VERSION "created by canmatrix"

NS_ :

BS_:

BU_: CabHeater_44 EAC_94 DCDC_1A HVJB_1E PPC_HV_5B PPC_00 PPC_EngineBrake_29 VECU_27 SAC_30 DTCO_EE eDS_5A EBS3_0B AEBS_A0 BMS_F4 Gearbox_03 DD_17 SERVICE_TOOL_F9 DANA_5F

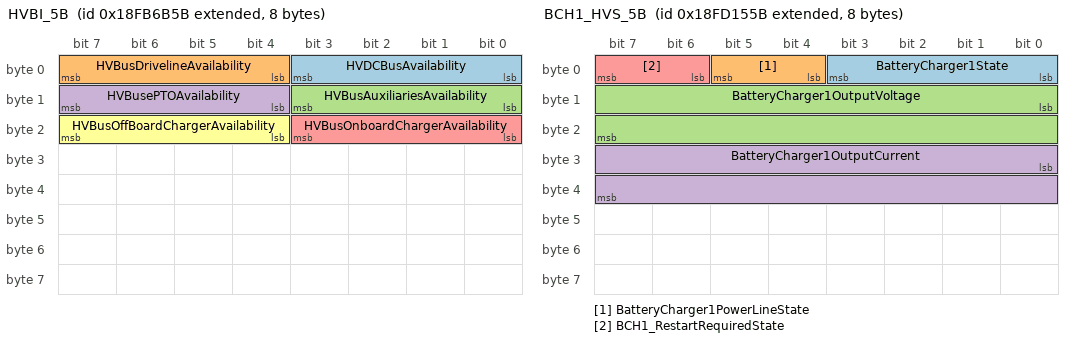
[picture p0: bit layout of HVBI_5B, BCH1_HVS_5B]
BO_ 2566613851 HVBI_5B: 8 PPC_HV_5B
 SG_ HVDCBusAvailability : 0|4@1+ (1,0) [0|15] "state" Vector__XXX
 SG_ HVBusDrivelineAvailability : 4|4@1+ (1,0) [0|15] "state" Vector__XXX
 SG_ HVBusAuxiliariesAvailability : 8|4@1+ (1,0) [0|15] "state" Vector__XXX
 SG_ HVBusePTOAvailability : 12|4@1+ (1,0) [0|15] "state" Vector__XXX
 SG_ HVBusOnboardChargerAvailability : 16|4@1+ (1,0) [0|15] "state" Vector__XXX
 SG_ HVBusOffBoardChargerAvailability : 20|4@1+ (1,0) [0|15] "state" Vector__XXX

BO_ 2566658651 HVESSTC1_5B: 8 PPC_HV_5B
 SG_ HVESSThermalManagementSystemHtrE : 32|2@1+ (1,0) [0|3] "state" Vector__XXX

BO_ 2566675956 HVESSCFG_F4: 20 BMS_F4
 SG_ HVESSNominalVoltage : 0|16@1+ (0.05,0) [0|3212.75] "V" Vector__XXX
 SG_ HVESSRecommendedMinOperatingVolt : 16|16@1+ (0.05,0) [0|3212.75] "V" Vector__XXX
 SG_ HVESSRecommendedMaxOperatingVolt : 32|16@1+ (0.05,0) [0|3212.75] "V" Vector__XXX
 SG_ HVESSRecommendedMinStateOfCharge : 48|16@1+ (0.0015625,0) [0|100.3984375] "%" Vector__XXX
 SG_ HVESSRecommendedMaxStateOfCharge : 64|16@1+ (0.0015625,0) [0|100.3984375] "%" Vector__XXX
 SG_ HVESSRecommendedMaxOperatingTemp : 80|16@1+ (0.03125,-273) [-273|1734.96875] "degC" Vector__XXX
 SG_ HVESSRecommendedMinOperatingTemp : 96|16@1+ (0.03125,-273) [-273|1734.96875] "degC" Vector__XXX
 SG_ HVESSCellMaximumVoltageLimit : 112|8@1+ (0.02044,0) [0|5.11] "V" Vector__XXX
 SG_ HVESSCellMinimumVoltageLimit : 120|8@1+ (0.02044,0) [0|5.11] "V" Vector__XXX
 SG_ HVESSNumberofHVESPsConfigured : 128|8@1+ (1,0) [0|250] "count" Vector__XXX
 SG_ HVESSNominalRatedCapacity : 136|24@1+ (0.001,0) [0|16449.535] "kWh" Vector__XXX

BO_ 2566722907 BCH1_HVS_5B: 8 PPC_HV_5B
 SG_ BatteryCharger1State : 0|4@1+ (1,0) [0|15] "state" Vector__XXX
 SG_ BatteryCharger1PowerLineState : 4|2@1+ (1,0) [0|3] "state" Vector__XXX
 SG_ BatteryCharger1OutputVoltage : 8|16@1+ (0.05,0) [0|3276.75] "V" Vector__XXX
 SG_ BatteryCharger1OutputCurrent : 24|16@1+ (0.05,-1600) [-1600|1676.75] "A" Vector__XXX
 SG_ BCH1_RestartRequiredState : 6|2@1+ (1,0) [0|0] "" Vector__XXX

BO_ 2566771751 CM3_27: 8 VECU_27
 SG_ OperatorKeySwitchIgnitionPower : 20|2@1+ (1,0) [0|3] "state" Vector__XXX

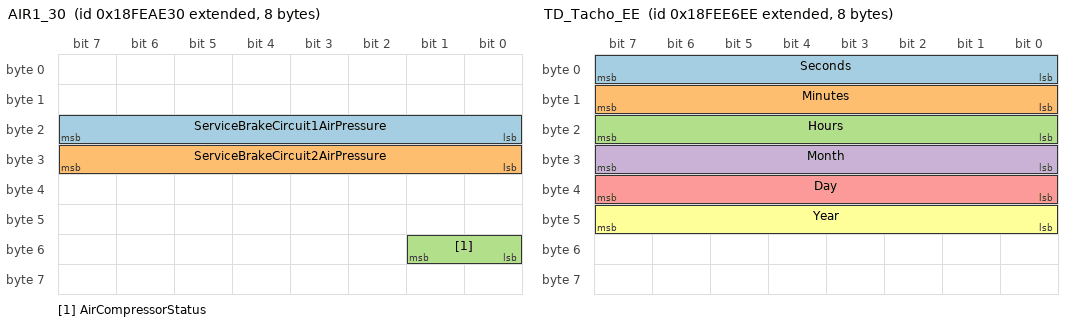
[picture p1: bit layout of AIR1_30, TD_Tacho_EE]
BO_ 2566827568 AIR1_30: 8 SAC_30
 SG_ ServiceBrakeCircuit1AirPressure : 16|8@1+ (8,0) [0|2040] "kPa" Vector__XXX
 SG_ ServiceBrakeCircuit2AirPressure : 24|8@1+ (8,0) [0|2040] "kPa" Vector__XXX
 SG_ AirCompressorStatus : 48|2@1+ (1,0) [0|3] "state" Vector__XXX

BO_ 2566832423 VDHR_VECU_27: 8 VECU_27

BO_ 2566832622 VDHR_EE: 8 DTCO_EE
 SG_ TotalVehicleDistHighResolution : 0|32@1+ (5,0) [-5|0] "m" Vector__XXX

BO_ 2566840154 EEC3_eDS_5A: 8 eDS_5A
 SG_ NominalFrictionPercentTorque : 0|8@1+ (1,-125) [-125|130] "%" Vector__XXX

BO_ 2566840666 RC_eDS_5A: 19 eDS_5A
 SG_ RetarderReferenceTorque : 128|16@1+ (1,0) [0|64255] "Nm" Vector__XXX
 SG_ RetarderType : 0|4@1+ (1,0) [0|15] "state" Vector__XXX
 SG_ RetarderLocation : 4|4@1+ (1,0) [0|15] "state" Vector__XXX
 SG_ RetarderControlMethod : 8|8@1+ (1,0) [0|250] "step" Vector__XXX
 SG_ RetarderPercentTorqueAtIdlePnt1 : 32|8@1+ (1,-125) [-125|125] "%" Vector__XXX
 SG_ RetarderPctTorqueAtMaxSpeedPnt2 : 56|8@1+ (1,-125) [-125|125] "%" Vector__XXX
 SG_ RetarderPercentTorqueAtPoint3 : 80|8@1+ (1,-125) [-125|125] "%" Vector__XXX
 SG_ RetarderPercentTorqueAtPoint4 : 104|8@1+ (1,-125) [-125|125] "%" Vector__XXX
 SG_ RetPctTorqueAtPeakTorquePnt5 : 144|8@1+ (1,-125) [-125|125] "%" Vector__XXX

BO_ 2566841895 TD_VECU_27: 8 VECU_27

BO_ 2566842094 TD_Tacho_EE: 8 DTCO_EE
 SG_ Seconds : 0|8@1+ (0.25,0) [0|63.75] "s" Vector__XXX
 SG_ Minutes : 8|8@1+ (1,0) [0|255] "min" Vector__XXX
 SG_ Hours : 16|8@1+ (1,0) [0|255] "h" Vector__XXX
 SG_ Month : 24|8@1+ (1,0) [0|255] "month" Vector__XXX
 SG_ Day : 32|8@1+ (0.25,0) [0|63.75] "day" Vector__XXX
 SG_ Year : 40|8@1+ (1,1985) [1985|2240] "year" Vector__XXX

BO_ 2566845696 AMB_Engine_00: 8 PPC_00
 SG_ BarometricPressure : 0|8@1+ (0.5,0) [0|127.5] "kPa" Vector__XXX
 SG_ AmbientAirTemperature : 24|16@1+ (0.03125,-273) [-273|1774.96875] "degC" Vector__XXX

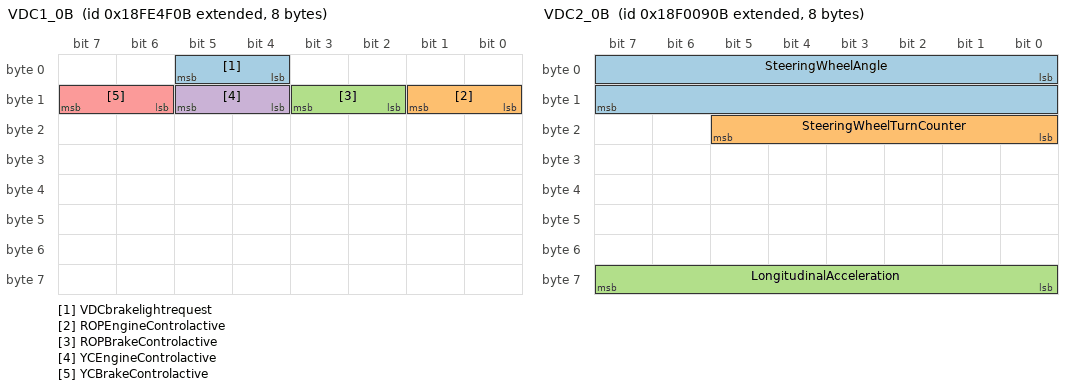
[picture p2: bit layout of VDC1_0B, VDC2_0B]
BO_ 2566803211 VDC1_0B: 8 EBS3_0B
 SG_ VDCbrakelightrequest : 4|2@1+ (1,0) [0|3] "state" Vector__XXX
 SG_ ROPEngineControlactive : 8|2@1+ (1,0) [0|3] "state" Vector__XXX
 SG_ ROPBrakeControlactive : 10|2@1+ (1,0) [0|3] "state" Vector__XXX
 SG_ YCEngineControlactive : 12|2@1+ (1,0) [0|3] "state" Vector__XXX
 SG_ YCBrakeControlactive : 14|2@1+ (1,0) [0|3] "state" Vector__XXX

BO_ 2565867787 VDC2_0B: 8 EBS3_0B
 SG_ SteeringWheelAngle : 0|16@1+ (0.0009765625,-31.374) [-31.374|32.625023437] "rad" Vector__XXX
 SG_ SteeringWheelTurnCounter : 16|6@1+ (1,-32) [-32|31] "count" Vector__XXX
 SG_ LongitudinalAcceleration : 56|8@1+ (0.1,-12.5) [-12.5|13] "m/s^2" Vector__XXX

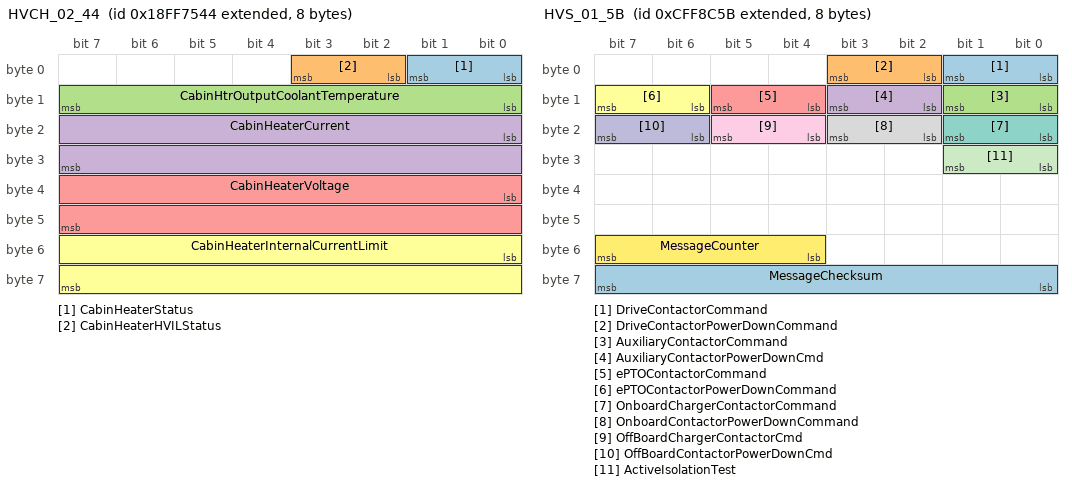
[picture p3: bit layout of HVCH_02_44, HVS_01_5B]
BO_ 2566878532 HVCH_02_44: 8 CabHeater_44
 SG_ CabinHeaterStatus : 0|2@1+ (1,0) [0|3] "state" Vector__XXX
 SG_ CabinHeaterHVILStatus : 2|2@1+ (1,0) [0|3] "state" Vector__XXX
 SG_ CabinHtrOutputCoolantTemperature : 8|8@1+ (1,-40) [-40|215] "degC" Vector__XXX
 SG_ CabinHeaterCurrent : 16|16@1+ (0.05,0) [0|3276.75] "A" Vector__XXX
 SG_ CabinHeaterVoltage : 32|16@1+ (0.05,0) [0|3276.75] "V" Vector__XXX
 SG_ CabinHeaterInternalCurrentLimit : 48|16@1+ (0.05,0) [0|3276.75] "A" Vector__XXX

BO_ 2633727015 WAKE_VECU_27: 8 VECU_27
 SG_ ControlBitVector : 0|8@1+ (1,0) [0|255] "state" Vector__XXX

BO_ 2633727067 WAKE_HVS_5B: 8 PPC_HV_5B
 SG_ ControlBitVector : 0|8@1+ (1,0) [0|255] "state" Vector__XXX

BO_ 2633727220 WAKE_BMS_F4: 8 BMS_F4
 SG_ ControlBitVector : 0|8@1+ (1,0) [0|255] "state" Vector__XXX

BO_ 2566549595 PC1LD_5B: 16 PPC_HV_5B
 SG_ PwrConv1TotalChargeGenerated : 96|32@1+ (100,0) [0|421108121500] "Ah" Vector__XXX
 SG_ PwrConv1TotalChargeConsumed : 64|32@1+ (100,0) [0|421108121500] "Ah" Vector__XXX
 SG_ PwrConv1TotalEnergyGenerated : 32|32@1+ (100,0) [0|201326492] "Wh" Vector__XXX
 SG_ PwrConv1TotalEnergyConsumed : 0|32@1+ (100,0) [0|201326492] "Wh" Vector__XXX

BO_ 2566549851 PC2LD_5B: 16 PPC_HV_5B
 SG_ PwrConv2TotalChargeGenerated : 96|32@1+ (100,0) [0|421108121500] "Ah" Vector__XXX
 SG_ PwrConv2TotalChargeConsumed : 64|32@1+ (100,0) [0|421108121500] "Ah" Vector__XXX
 SG_ PwrConv2TotalEnergyGenerated : 32|32@1+ (100,0) [0|201326492] "Wh" Vector__XXX
 SG_ PwrConv2TotalEnergyConsumed : 0|32@1+ (100,0) [0|201326492] "Wh" Vector__XXX

BO_ 2566569307 MG1LD_5B: 16 PPC_HV_5B
 SG_ MG1_TotalChargeGenerated : 96|32@1+ (100,0) [0|201326492] "Ah" Vector__XXX
 SG_ MG1_TotalChargeConsumed : 64|32@1+ (100,0) [0|201326492] "Ah" Vector__XXX
 SG_ MG1_TotalEnergyGenerated : 32|32@1+ (100,0) [0|201326492] "Wh" Vector__XXX
 SG_ MG1_TotalEnergyConsumed : 0|32@1+ (100,0) [0|201326492] "Wh" Vector__XXX

BO_ 2365557851 HVS_01_5B: 8 PPC_HV_5B
 SG_ DriveContactorCommand : 0|2@1+ (1,0) [0|3] "state" Vector__XXX
 SG_ DriveContactorPowerDownCommand : 2|2@1+ (1,0) [0|3] "state" Vector__XXX
 SG_ AuxiliaryContactorCommand : 8|2@1+ (1,0) [0|3] "state" Vector__XXX
 SG_ AuxiliaryContactorPowerDownCmd : 10|2@1+ (1,0) [0|3] "state" Vector__XXX
 SG_ ePTOContactorCommand : 12|2@1+ (1,0) [0|3] "state" Vector__XXX
 SG_ ePTOContactorPowerDownCommand : 14|2@1+ (1,0) [0|3] "state" Vector__XXX
 SG_ OnboardChargerContactorCommand : 16|2@1+ (1,0) [0|3] "state" Vector__XXX
 SG_ OnboardContactorPowerDownCommand : 18|2@1+ (1,0) [0|3] "state" Vector__XXX
 SG_ OffBoardChargerContactorCmd : 20|2@1+ (1,0) [0|3] "state" Vector__XXX
 SG_ OffBoardContactorPowerDownCmd : 22|2@1+ (1,0) [0|3] "state" Vector__XXX
 SG_ ActiveIsolationTest : 24|2@1+ (1,0) [0|3] "state" Vector__XXX
 SG_ MessageCounter : 52|4@1+ (1,0) [0|15] "count" Vector__XXX
 SG_ MessageChecksum : 56|8@1+ (1,0) [0|255] "count" Vector__XXX

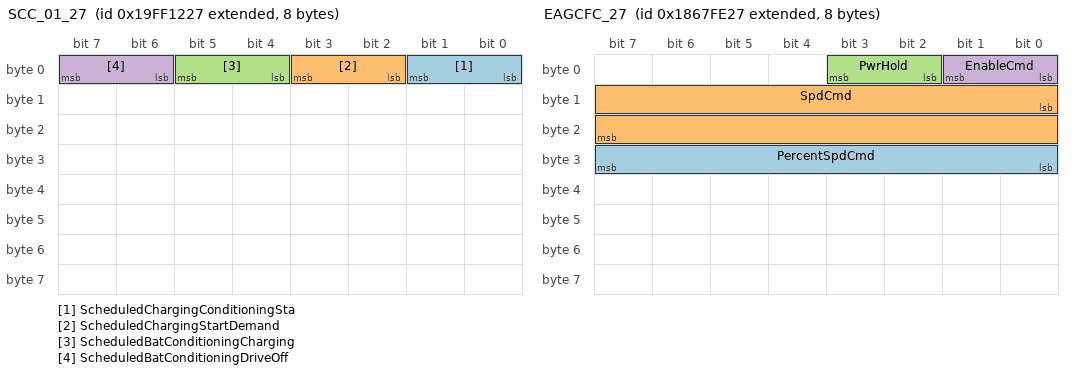
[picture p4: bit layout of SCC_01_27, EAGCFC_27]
BO_ 2583630375 SCC_01_27: 8 VECU_27
 SG_ ScheduledChargingConditioningSta : 0|2@1+ (1,0) [0|3] "state" Vector__XXX
 SG_ ScheduledChargingStartDemand : 2|2@1+ (1,0) [0|3] "state" Vector__XXX
 SG_ ScheduledBatConditioningCharging : 4|2@1+ (1,0) [0|3] "state" Vector__XXX
 SG_ ScheduledBatConditioningDriveOff : 6|2@1+ (1,0) [0|3] "state" Vector__XXX

BO_ 2556952103 EAGCFC_27: 8 VECU_27
 SG_ PercentSpdCmd : 24|8@1+ (0.5,0) [0|100] "%" Vector__XXX
 SG_ SpdCmd : 8|16@1+ (0.5,0) [0|32767.5] "rpm" Vector__XXX
 SG_ PwrHold : 2|2@1+ (1,0) [0|3] "" Vector__XXX
 SG_ EnableCmd : 0|2@1+ (1,0) [0|3] "" Vector__XXX

BO_ 2365558046 HVJB_01_1E: 8 HVJB_1E
 SG_ DriveContactorState : 0|2@1+ (1,0) [0|3] "state" Vector__XXX
 SG_ DrivePreChargeContactorState : 2|2@1+ (1,0) [0|3] "state" Vector__XXX
 SG_ DriveContactorErrorState : 4|2@1+ (1,0) [0|3] "state" Vector__XXX
 SG_ DrivePreChargeContactorErrorStat : 6|2@1+ (1,0) [0|3] "state" Vector__XXX
 SG_ AuxiliaryContactorState : 8|2@1+ (1,0) [0|3] "state" Vector__XXX
 SG_ AuxiliaryPreChargeContactorState : 10|2@1+ (1,0) [0|3] "state" Vector__XXX
 SG_ AuxiliaryContactorErrorState : 12|2@1+ (1,0) [0|3] "state" Vector__XXX
 SG_ AuxiliaryPreChargeContactorError : 14|2@1+ (1,0) [0|3] "state" Vector__XXX
 SG_ ePTOPositiveContactorState : 16|2@1+ (1,0) [0|3] "state" Vector__XXX
 SG_ ePTOPreChargeContactorState : 18|2@1+ (1,0) [0|3] "state" Vector__XXX
 SG_ ePTOPositiveContactorErrorState : 20|2@1+ (1,0) [0|3] "state" Vector__XXX
 SG_ ePTOPreChargeContactorErrorState : 22|2@1+ (1,0) [0|3] "state" Vector__XXX
 SG_ ePTONegativeContactorState : 24|2@1+ (1,0) [0|3] "state" Vector__XXX
 SG_ OnboardChargerContactorState_IM3 : 26|2@1+ (1,0) [0|3] "state" Vector__XXX
 SG_ ePTONegativeContactorErrorState : 28|2@1+ (1,0) [0|3] "state" Vector__XXX
 SG_ OnboardChargerContactorErrorStat : 30|2@1+ (1,0) [0|3] "state" Vector__XXX
 SG_ OffBoardChargerPosContactorState : 32|2@1+ (1,0) [0|3] "state" Vector__XXX
 SG_ OffBoardChargerNegContactorState : 34|2@1+ (1,0) [0|3] "state" Vector__XXX
 SG_ OffBoardChargerPosContactorError : 36|2@1+ (1,0) [0|3] "state" Vector__XXX
 SG_ OffBoardChargerNegContactorError : 38|2@1+ (1,0) [0|3] "state" Vector__XXX
 SG_ HVILStatus1_Drive : 40|2@1+ (1,0) [0|3] "state" Vector__XXX
 SG_ HVILStatus2_Aux : 42|2@1+ (1,0) [0|3] "state" Vector__XXX
 SG_ HVILStatus3_ePTO : 44|2@1+ (1,0) [0|3] "state" Vector__XXX
 SG_ HVJB_OperationalState : 48|4@1+ (1,0) [0|15] "state" Vector__XXX
 SG_ HVJB_01MessageCounter : 52|4@1+ (1,0) [0|15] "count" Vector__XXX
 SG_ HVJB_01MessageChecksum : 56|8@1+ (1,0) [0|255] "count" Vector__XXX

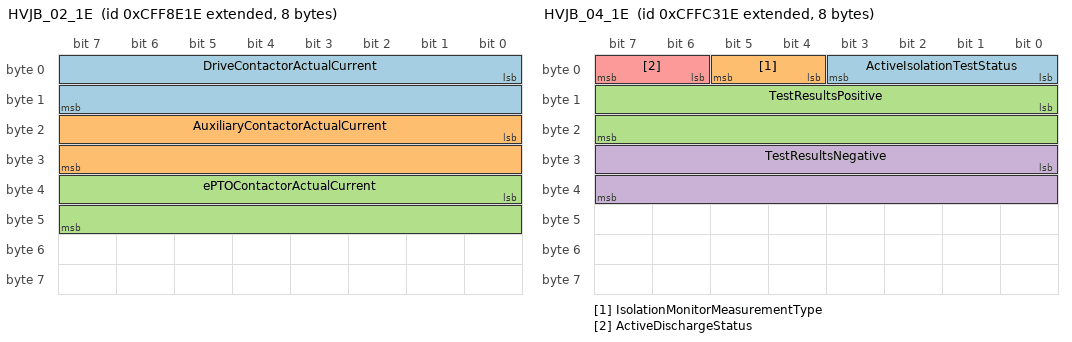
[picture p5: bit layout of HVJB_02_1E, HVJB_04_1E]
BO_ 2365558302 HVJB_02_1E: 8 HVJB_1E
 SG_ DriveContactorActualCurrent : 0|16@1+ (0.05,-1600) [-1600|1676.75] "A" Vector__XXX
 SG_ AuxiliaryContactorActualCurrent : 16|16@1+ (0.05,-1600) [-1600|1676.75] "A" Vector__XXX
 SG_ ePTOContactorActualCurrent : 32|16@1+ (0.05,-1600) [-1600|1676.75] "A" Vector__XXX

BO_ 2365558558 HVJB_03_1E: 8 HVJB_1E
 SG_ OffBoardChargerActualVoltage : 0|16@1+ (0.05,-1600) [-1600|1676.75] "V" Vector__XXX

BO_ 2365571870 HVJB_04_1E: 8 HVJB_1E
 SG_ ActiveIsolationTestStatus : 0|4@1+ (1,0) [0|15] "state" Vector__XXX
 SG_ IsolationMonitorMeasurementType : 4|2@1+ (1,0) [0|3] "state" Vector__XXX
 SG_ TestResultsPositive : 8|16@1+ (1,0) [0|65535] "kOhm" Vector__XXX
 SG_ TestResultsNegative : 24|16@1+ (1,0) [0|65535] "kOhm" Vector__XXX
 SG_ ActiveDischargeStatus : 6|2@1+ (1,0) [0|3] "state" Vector__XXX

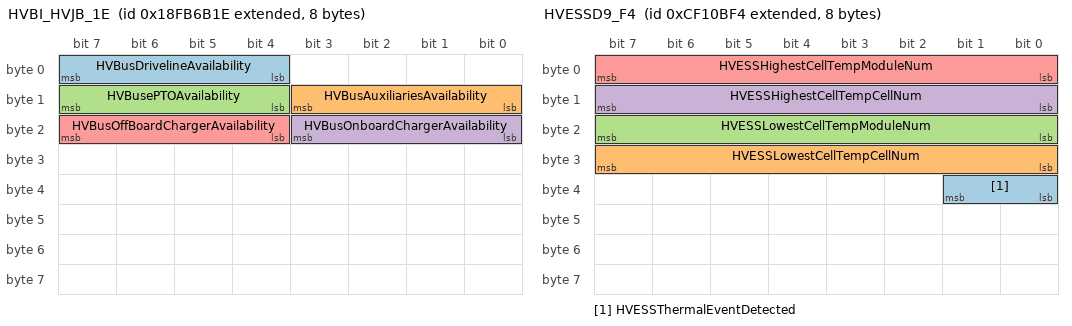
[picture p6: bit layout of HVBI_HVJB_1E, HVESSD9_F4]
BO_ 2566613790 HVBI_HVJB_1E: 8 HVJB_1E
 SG_ HVBusDrivelineAvailability : 4|4@1+ (1,0) [0|15] "state" Vector__XXX
 SG_ HVBusAuxiliariesAvailability : 8|4@1+ (1,0) [0|15] "state" Vector__XXX
 SG_ HVBusePTOAvailability : 12|4@1+ (1,0) [0|15] "state" Vector__XXX
 SG_ HVBusOnboardChargerAvailability : 16|4@1+ (1,0) [0|15] "state" Vector__XXX
 SG_ HVBusOffBoardChargerAvailability : 20|4@1+ (1,0) [0|15] "state" Vector__XXX

BO_ 2364607476 HVESSD9_F4: 8 BMS_F4
 SG_ HVESSThermalEventDetected : 32|2@1+ (1,0) [0|3] "" Vector__XXX
 SG_ HVESSLowestCellTempCellNum : 24|8@1+ (1,0) [0|250] "" Vector__XXX
 SG_ HVESSLowestCellTempModuleNum : 16|8@1+ (1,0) [0|250] "" Vector__XXX
 SG_ HVESSHighestCellTempCellNum : 8|8@1+ (1,0) [0|250] "" Vector__XXX
 SG_ HVESSHighestCellTempModuleNum : 0|8@1+ (1,0) [0|250] "" Vector__XXX

BO_ 2583632219 HVS_05_5B: 8 PPC_HV_5B
 SG_ CabinACCompressorSpeed : 0|8@1+ (50,0) [0|12500] "rpm" Vector__XXX
 SG_ CabinACCompressorErrorStatus : 8|2@1+ (1,0) [0|3] "state" Vector__XXX

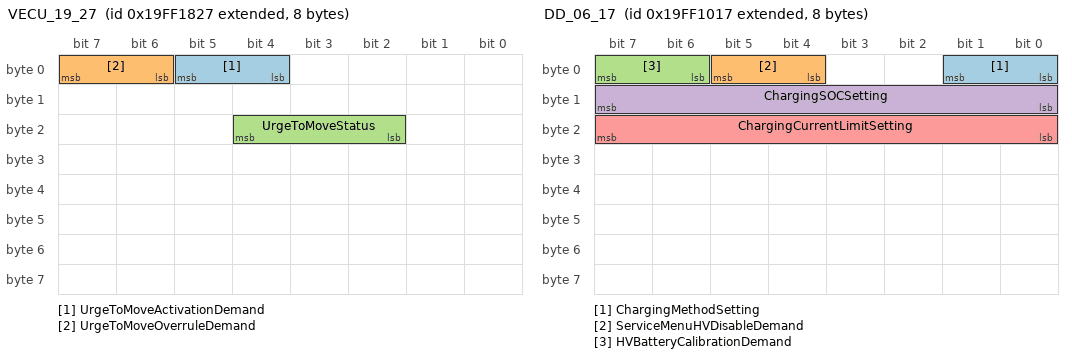
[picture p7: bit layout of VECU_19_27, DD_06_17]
BO_ 2583631911 VECU_19_27: 8 VECU_27
 SG_ UrgeToMoveActivationDemand : 4|2@1+ (1,0) [0|3] "state"  Gearbox_03
 SG_ UrgeToMoveOverruleDemand : 6|2@1+ (1,0) [0|3] "state"  Gearbox_03
 SG_ UrgeToMoveStatus : 18|3@1+ (1,0) [0|7] "state"  Gearbox_03

BO_ 2566810971 HTR_5B: 8 PPC_HV_5B
 SG_ AuxiliaryHeaterMode : 24|4@1+ (1,0) [0|15] "state" Vector__XXX

BO_ 2583631655 BCR_01_27: 8 VECU_27
 SG_ EnergyCapResPluginCharging : 0|8@1+ (1,0) [0|250] "kWh"  Gearbox_03
 SG_ EnergyCapResRegenerativeBraking : 8|8@1+ (1,0) [0|250] "kWh"  Gearbox_03

BO_ 2583629847 DD_06_17: 8 DD_17
 SG_ ChargingMethodSetting : 0|2@1+ (1,0) [0|3] "state"  Gearbox_03
 SG_ ServiceMenuHVDisableDemand : 4|2@1+ (1,0) [0|3] "state"  Gearbox_03
 SG_ HVBatteryCalibrationDemand : 6|2@1+ (1,0) [0|3] "state"  Gearbox_03
 SG_ ChargingSOCSetting : 8|8@1+ (0.5,0) [0|125] "%"  Gearbox_03
 SG_ ChargingCurrentLimitSetting : 16|8@1+ (5,0) [0|1250] "A"  Gearbox_03

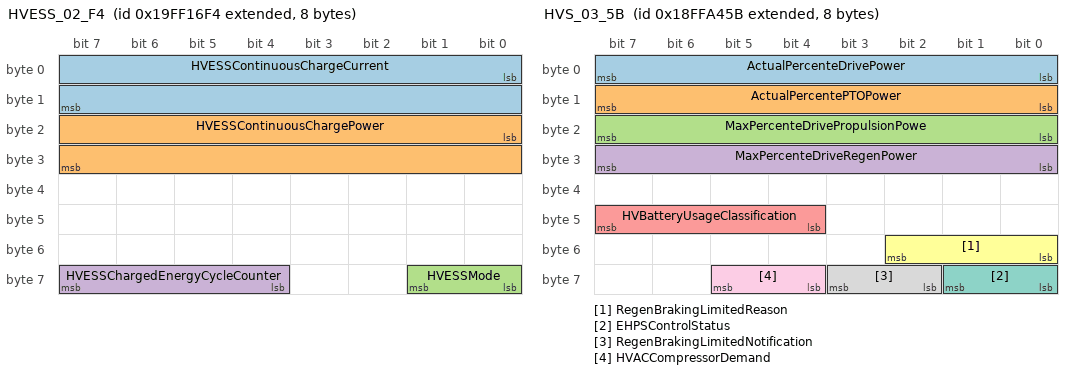
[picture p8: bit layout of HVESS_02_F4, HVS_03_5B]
BO_ 2583631604 HVESS_02_F4: 8 BMS_F4
 SG_ HVESSContinuousChargeCurrent : 0|16@1+ (0.05,-1600) [-1600|1612] "A"  Gearbox_03
 SG_ HVESSContinuousChargePower : 16|16@1+ (0.05,0) [0|3212] "kW"  Gearbox_03
 SG_ HVESSMode : 56|2@1+ (1,0) [0|3] "state"  Gearbox_03
 SG_ HVESSChargedEnergyCycleCounter : 60|4@1+ (1,0) [0|15] "count"  Gearbox_03

BO_ 2566889563 HVS_02_5B: 8 PPC_HV_5B
 SG_ StopChargingSwitchIndication : 8|2@1+ (1,0) [0|0] "" Vector__XXX
 SG_ ChargingState : 0|4@1+ (1,0) [0|15] "state" Vector__XXX
 SG_ ChargePlugLockedStatus : 4|2@1+ (1,0) [0|3] "state" Vector__XXX
 SG_ ChargePlugUnlockedStatus : 6|2@1+ (1,0) [0|3] "state" Vector__XXX
 SG_ ChargePlugNotSuppNotification : 24|2@1+ (1,0) [0|3] "state" Vector__XXX
 SG_ ChargePlugTempNotification : 26|2@1+ (1,0) [0|3] "state" Vector__XXX
 SG_ ChargingInterlockParkBrake : 28|2@1+ (1,0) [0|3] "state" Vector__XXX
 SG_ EVSEErrorNotification : 30|2@1+ (1,0) [0|3] "state" Vector__XXX
 SG_ EVSECommErrorNotification : 32|2@1+ (1,0) [0|3] "state" Vector__XXX
 SG_ EVSEVoltageRangeNotification : 34|2@1+ (1,0) [0|3] "state" Vector__XXX
 SG_ EVSECurrentRangeNotification : 36|2@1+ (1,0) [0|3] "state" Vector__XXX
 SG_ EVSEIsolationFailNotification : 38|2@1+ (1,0) [0|3] "state" Vector__XXX
 SG_ ChargeSessVehRestartNotification : 40|2@1+ (1,0) [0|3] "state" Vector__XXX
 SG_ HVBatteryCalibrationStatus : 42|2@1+ (1,0) [0|3] "state" Vector__XXX
 SG_ HVBattCalibrationPlannedForNextC : 44|2@1+ (1,0) [0|3] "state" Vector__XXX
 SG_ ChargingSOCActualSetting : 48|4@1+ (1,0) [0|15] "state" Vector__XXX
 SG_ ChargeSOCDriverSettingNotPossibl : 52|2@1+ (1,0) [0|3] "state" Vector__XXX
 SG_ ChargingMethodSelected : 54|2@1+ (1,0) [0|3] "state" Vector__XXX
 SG_ ChargingSOCTarget : 56|8@1+ (0.5,0) [0|125] "%" Vector__XXX

BO_ 2566890587 HVS_03_5B: 8 PPC_HV_5B
 SG_ ActualPercenteDrivePower : 0|8@1+ (1,-125) [-125|125] "%" Vector__XXX
 SG_ ActualPercentePTOPower : 8|8@1+ (1,-125) [-125|125] "%" Vector__XXX
 SG_ MaxPercenteDrivePropulsionPowe : 16|8@1+ (1,-125) [-125|125] "%" Vector__XXX
 SG_ MaxPercenteDriveRegenPower : 24|8@1+ (1,-125) [-125|125] "%" Vector__XXX
 SG_ HVBatteryUsageClassification : 44|4@1+ (1,0) [0|15] "state" Vector__XXX
 SG_ RegenBrakingLimitedReason : 48|3@1+ (1,0) [0|7] "state" Vector__XXX
 SG_ EHPSControlStatus : 56|2@1+ (1,0) [0|3] "state" Vector__XXX
 SG_ RegenBrakingLimitedNotification : 58|2@1+ (1,0) [0|3] "state" Vector__XXX
 SG_ HVACCompressorDemand : 60|2@1+ (1,0) [0|3] "state" Vector__XXX

BO_ 2364577115 HVESSD6_5B: 8 PPC_HV_5B
 SG_ HVESSIntakeCoolantTemperature : 32|8@1+ (1,-40) [-40|210] "degC" Vector__XXX

BO_ 2566775131 CCSI1_5B: 8 PPC_HV_5B
 SG_ AirConditionerCompressorStatus : 8|2@1+ (1,0) [0|3] "state" Vector__XXX

BO_ 2566573919 EVCC1D1_5F: 12 DANA_5F
 SG_ CompatibilityCode : 88|4@1+ (1,0) [0|15] "" Vector__XXX
 SG_ InletConnectorTemp : 80|8@1+ (1,-40) [-40|210] "∞C" Vector__XXX
 SG_ ProximityCircVoltage : 64|16@1+ (0.01,0) [0|642.55] "V" Vector__XXX
 SG_ CtrlPilotSubState : 60|4@1+ (1,0) [0|15] "" Vector__XXX
 SG_ CtrlPilotState : 56|4@1+ (1,0) [0|15] "" Vector__XXX
 SG_ CtrlPilotDutyCycle : 48|8@1+ (0.5,0) [0|125] "%" Vector__XXX
 SG_ CtrlPilotPWMFreq : 32|16@1+ (1,0) [0|64255] "Hz" Vector__XXX
 SG_ CtrlPilotMinVoltage : 16|16@1+ (0.05,-1606) [-1606|1606.75] "V" Vector__XXX
 SG_ CtrlPilotMaxVoltage : 0|16@1+ (0.05,-1606) [-1606|1606.75] "V" Vector__XXX

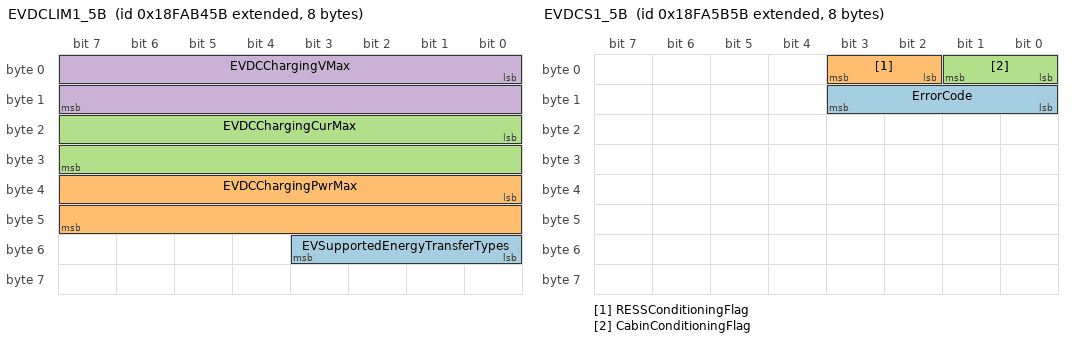
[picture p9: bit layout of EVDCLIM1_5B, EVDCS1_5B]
BO_ 2566567003 EVDCLIM1_5B: 8 PPC_HV_5B
 SG_ EVSupportedEnergyTransferTypes : 48|4@1+ (1,0) [0|15] "" Vector__XXX
 SG_ EVDCChargingPwrMax : 32|16@1+ (0.05,0) [0|3212.75] "kW" Vector__XXX
 SG_ EVDCChargingCurMax : 16|16@1+ (0.0625,0) [0|4015.9375] "A" Vector__XXX
 SG_ EVDCChargingVMax : 0|16@1+ (0.05,0) [0|3212.75] "V" Vector__XXX

BO_ 2566544219 EVDCS1_5B: 8 PPC_HV_5B
 SG_ ErrorCode : 8|4@1+ (1,0) [0|15] "" Vector__XXX
 SG_ RESSConditioningFlag : 2|2@1+ (1,0) [0|3] "" Vector__XXX
 SG_ CabinConditioningFlag : 0|2@1+ (1,0) [0|3] "" Vector__XXX

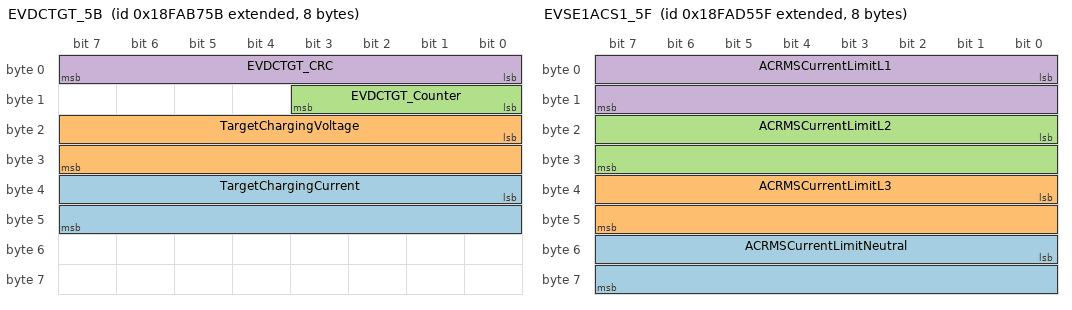
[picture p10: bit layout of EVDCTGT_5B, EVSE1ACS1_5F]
BO_ 2566567771 EVDCTGT_5B: 8 PPC_HV_5B
 SG_ TargetChargingCurrent : 32|16@1+ (0.0625,0) [0|4015.9375] "A" Vector__XXX
 SG_ TargetChargingVoltage : 16|16@1+ (0.05,0) [0|3212.75] "V" Vector__XXX
 SG_ EVDCTGT_Counter : 8|4@1+ (1,0) [0|15] "" Vector__XXX
 SG_ EVDCTGT_CRC : 0|8@1+ (1,0) [0|255] "" Vector__XXX

BO_ 2566575455 EVSE1ACS1_5F: 8 DANA_5F
 SG_ ACRMSCurrentLimitNeutral : 48|16@1+ (0.0625,0) [0|4015.9375] "A" Vector__XXX
 SG_ ACRMSCurrentLimitL3 : 32|16@1+ (0.0625,0) [0|4015.9375] "A" Vector__XXX
 SG_ ACRMSCurrentLimitL2 : 16|16@1+ (0.0625,0) [0|4015.9375] "A" Vector__XXX
 SG_ ACRMSCurrentLimitL1 : 0|16@1+ (0.0625,0) [0|4015.9375] "A" Vector__XXX

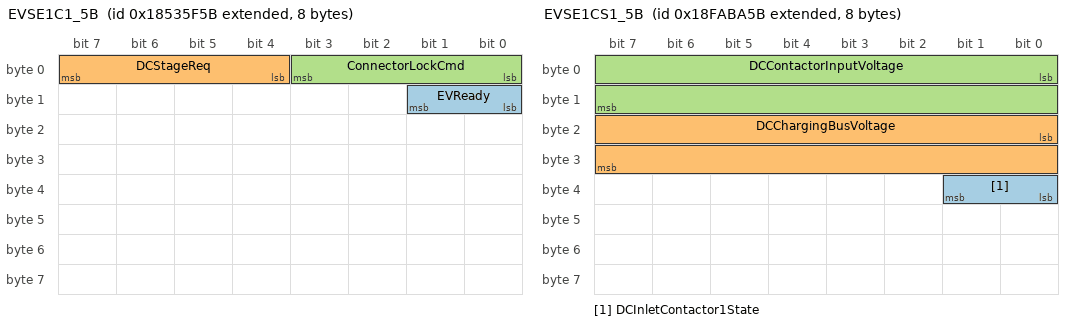
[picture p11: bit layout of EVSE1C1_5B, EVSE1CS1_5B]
BO_ 2555600731 EVSE1C1_5B: 8 PPC_HV_5B
 SG_ EVReady : 8|2@1+ (1,0) [0|3] "" Vector__XXX
 SG_ DCStageReq : 4|4@1+ (1,0) [0|15] "" Vector__XXX
 SG_ ConnectorLockCmd : 0|4@1+ (1,0) [0|15] "" Vector__XXX

BO_ 2566568287 EVSE1CC1_5F: 8 DANA_5F
 SG_ DCInletContactorCommand : 0|2@1+ (1,0) [0|3] "" Vector__XXX

BO_ 2566568539 EVSE1CS1_5B: 8 PPC_HV_5B
 SG_ DCInletContactor1State : 32|2@1+ (1,0) [0|3] "" Vector__XXX
 SG_ DCChargingBusVoltage : 16|16@1+ (0.05,0) [0|3212.75] "V" Vector__XXX
 SG_ DCContactorInputVoltage : 0|16@1+ (0.05,0) [0|3212.75] "V" Vector__XXX

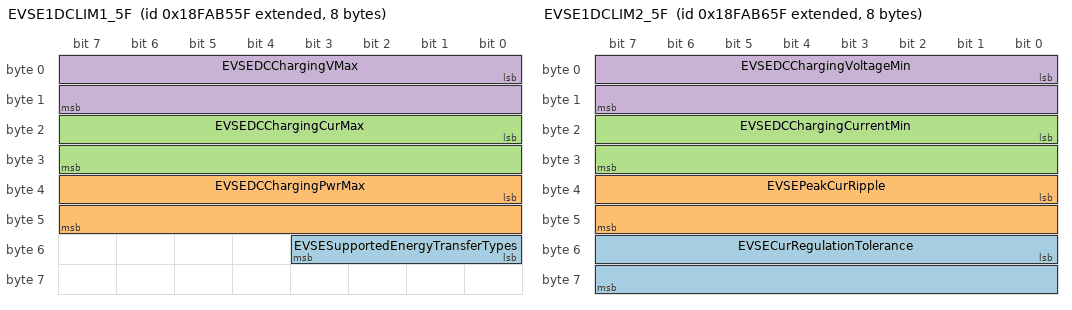
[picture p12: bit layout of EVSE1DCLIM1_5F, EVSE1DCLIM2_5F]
BO_ 2566567263 EVSE1DCLIM1_5F: 8 DANA_5F
 SG_ EVSESupportedEnergyTransferTypes : 48|4@1+ (1,0) [0|15] "" Vector__XXX
 SG_ EVSEDCChargingPwrMax : 32|16@1+ (0.05,0) [0|3212.75] "kW" Vector__XXX
 SG_ EVSEDCChargingCurMax : 16|16@1+ (0.0625,0) [0|4015.9375] "A" Vector__XXX
 SG_ EVSEDCChargingVMax : 0|16@1+ (0.05,0) [0|3212.75] "V" Vector__XXX

BO_ 2566567519 EVSE1DCLIM2_5F: 8 DANA_5F
 SG_ EVSECurRegulationTolerance : 48|16@1+ (0.0625,0) [0|4015.9375] "A" Vector__XXX
 SG_ EVSEPeakCurRipple : 32|16@1+ (0.0625,0) [0|4015.9375] "A" Vector__XXX
 SG_ EVSEDCChargingCurrentMin : 16|16@1+ (0.0625,0) [0|4015.9375] "A" Vector__XXX
 SG_ EVSEDCChargingVoltageMin : 0|16@1+ (0.05,0) [0|3212.75] "V" Vector__XXX

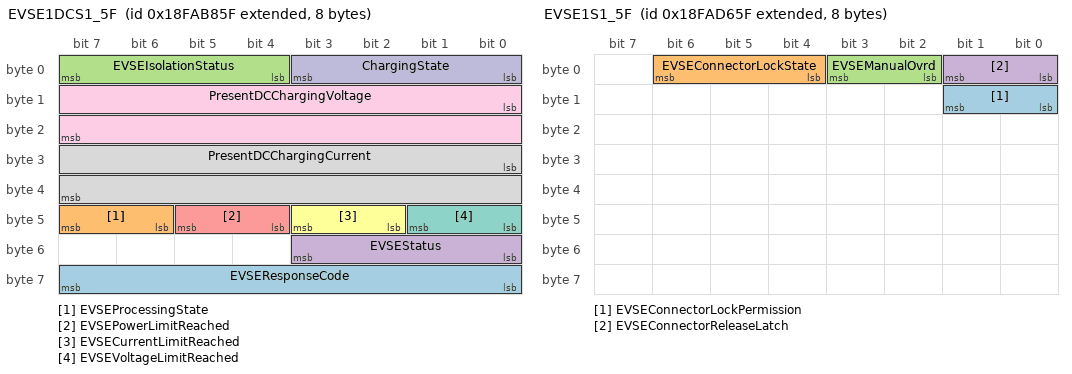
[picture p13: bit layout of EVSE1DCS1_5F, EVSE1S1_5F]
BO_ 2566568031 EVSE1DCS1_5F: 8 DANA_5F
 SG_ EVSEResponseCode : 56|8@1+ (1,0) [0|255] "" Vector__XXX
 SG_ EVSEProcessingState : 46|2@1+ (1,0) [0|3] "" Vector__XXX
 SG_ EVSEIsolationStatus : 4|4@1+ (1,0) [0|15] "" Vector__XXX
 SG_ EVSEStatus : 48|4@1+ (1,0) [0|15] "" Vector__XXX
 SG_ EVSEPowerLimitReached : 44|2@1+ (1,0) [0|3] "" Vector__XXX
 SG_ EVSECurrentLimitReached : 42|2@1+ (1,0) [0|3] "" Vector__XXX
 SG_ EVSEVoltageLimitReached : 40|2@1+ (1,0) [0|3] "" Vector__XXX
 SG_ PresentDCChargingCurrent : 24|16@1+ (0.05,-1600) [-1600|1612.75] "A" Vector__XXX
 SG_ PresentDCChargingVoltage : 8|16@1+ (0.05,0) [0|3212.75] "V" Vector__XXX
 SG_ ChargingState : 0|4@1+ (1,0) [0|15] "" Vector__XXX

BO_ 2566575711 EVSE1S1_5F: 8 DANA_5F
 SG_ EVSEConnectorLockPermission : 8|2@1+ (1,0) [0|3] "" Vector__XXX
 SG_ EVSEConnectorLockState : 4|3@1+ (1,0) [0|7] "" Vector__XXX
 SG_ EVSEManualOvrd : 2|2@1+ (1,0) [0|3] "" Vector__XXX
 SG_ EVSEConnectorReleaseLatch : 0|2@1+ (1,0) [0|3] "" Vector__XXX

BO_ 2558590815 HSC1_5F: 8 DANA_5F
 SG_ ConnectedEnergySourceType : 22|2@1+ (1,0) [0|3] "" Vector__XXX

BO_ 2566837855 HSI1_5F: 8 DANA_5F
 SG_ OffBoardChargerConnectionState : 6|2@1+ (1,0) [0|3] "" Vector__XXX

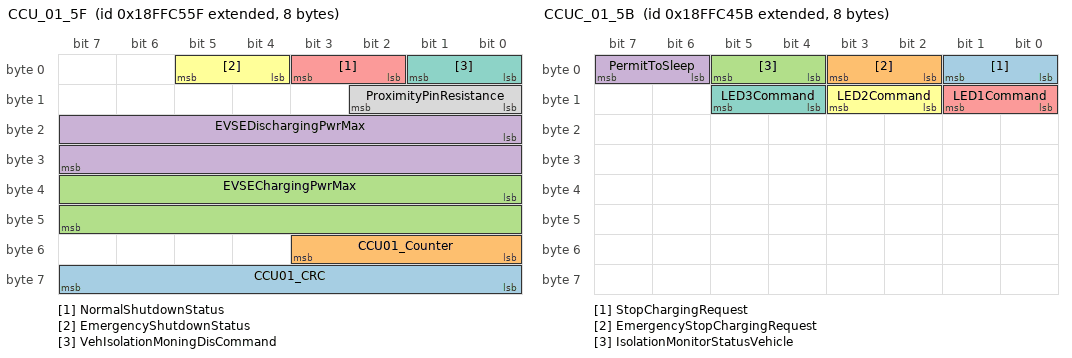
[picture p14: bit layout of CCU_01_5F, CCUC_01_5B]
BO_ 2566899039 CCU_01_5F: 8 DANA_5F
 SG_ CCU01_CRC : 56|8@1+ (1,0) [0|255] "" Vector__XXX
 SG_ CCU01_Counter : 48|4@1+ (1,0) [0|0] "" Vector__XXX
 SG_ EVSEChargingPwrMax : 32|16@1+ (0.05,0) [0|3212.75] "kW" Vector__XXX
 SG_ EVSEDischargingPwrMax : 16|16@1+ (0.05,0) [0|3212.75] "kW" Vector__XXX
 SG_ NormalShutdownStatus : 2|2@1+ (1,0) [0|0] "" Vector__XXX
 SG_ EmergencyShutdownStatus : 4|2@1+ (1,0) [0|0] "" Vector__XXX
 SG_ VehIsolationMoningDisCommand : 0|2@1+ (1,0) [0|3] "state" Vector__XXX
 SG_ ProximityPinResistance : 8|3@1+ (1,0) [0|7] "state" Vector__XXX

BO_ 2566898779 CCUC_01_5B: 8 PPC_HV_5B
 SG_ StopChargingRequest : 0|2@1+ (1,0) [0|3] "state" Vector__XXX
 SG_ EmergencyStopChargingRequest : 2|2@1+ (1,0) [0|3] "state" Vector__XXX
 SG_ IsolationMonitorStatusVehicle : 4|2@1+ (1,0) [0|3] "state" Vector__XXX
 SG_ PermitToSleep : 6|2@1+ (1,0) [0|3] "state" Vector__XXX
 SG_ LED1Command : 8|2@1+ (1,0) [0|3] "state" Vector__XXX
 SG_ LED2Command : 10|2@1+ (1,0) [0|3] "state" Vector__XXX
 SG_ LED3Command : 12|2@1+ (1,0) [0|3] "state" Vector__XXX

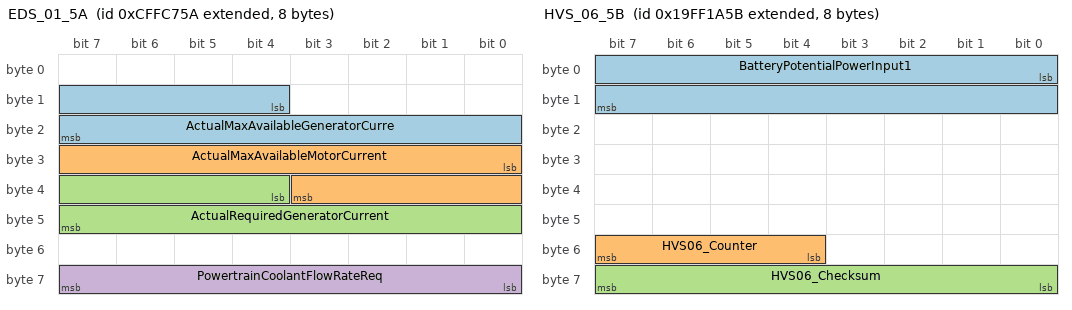
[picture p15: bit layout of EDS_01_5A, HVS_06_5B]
BO_ 2365572954 EDS_01_5A: 8 eDS_5A
 SG_ ActualMaxAvailableGeneratorCurre : 12|12@1+ (0.0625,-125) [-125|125] "%" Vector__XXX
 SG_ ActualMaxAvailableMotorCurrent : 24|12@1+ (0.0625,-125) [-125|125] "%" Vector__XXX
 SG_ ActualRequiredGeneratorCurrent : 36|12@1+ (0.0625,-125) [-125|125] "%" Vector__XXX
 SG_ PowertrainCoolantFlowRateReq : 56|8@1+ (0.5,0) [0|125] "l/min" Vector__XXX

BO_ 2583632475 HVS_06_5B: 8 PPC_HV_5B
 SG_ BatteryPotentialPowerInput1 : 0|16@1+ (0.05,0) [0|3212] "V" Vector__XXX
 SG_ HVS06_Counter : 52|4@1+ (1,0) [0|15] "count" Vector__XXX
 SG_ HVS06_Checksum : 56|8@1+ (1,0) [0|255] "count" Vector__XXX

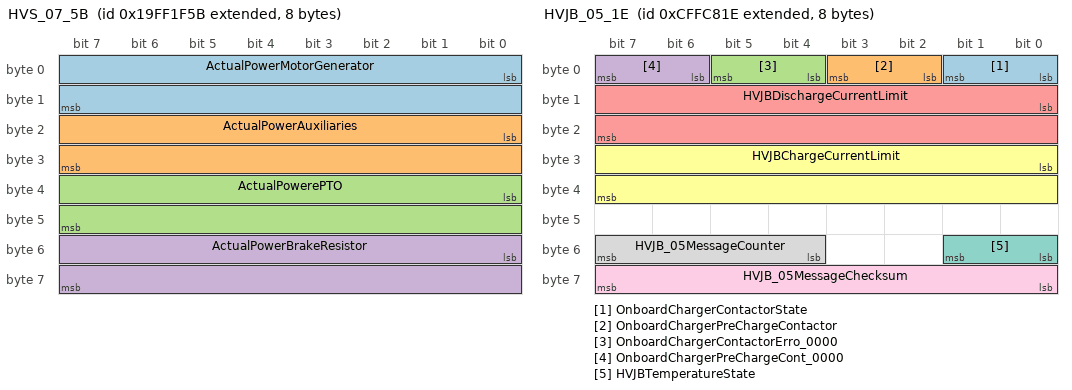
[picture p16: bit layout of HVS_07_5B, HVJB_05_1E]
BO_ 2583633755 HVS_07_5B: 8 PPC_HV_5B
 SG_ ActualPowerMotorGenerator : 0|16@1+ (0.05,-1600) [-1600|1612] "kW" Vector__XXX
 SG_ ActualPowerAuxiliaries : 16|16@1+ (0.05,-1600) [-1600|1612] "kW" Vector__XXX
 SG_ ActualPowerePTO : 32|16@1+ (0.05,-1600) [-1600|1612] "kW" Vector__XXX
 SG_ ActualPowerBrakeResistor : 48|16@1+ (0.05,-1600) [-1600|1612] "kW" Vector__XXX

BO_ 2365573150 HVJB_05_1E: 8 HVJB_1E
 SG_ OnboardChargerContactorState : 0|2@1+ (1,0) [0|3] "state" Vector__XXX
 SG_ OnboardChargerPreChargeContactor : 2|2@1+ (1,0) [0|3] "state" Vector__XXX
 SG_ OnboardChargerContactorErro_0000 : 4|2@1+ (1,0) [0|3] "state" Vector__XXX
 SG_ OnboardChargerPreChargeCont_0000 : 6|2@1+ (1,0) [0|3] "state" Vector__XXX
 SG_ HVJBDischargeCurrentLimit : 8|16@1+ (0.05,-1600) [-1600|1612] "A" Vector__XXX
 SG_ HVJBChargeCurrentLimit : 24|16@1+ (0.05,-1600) [-1600|1612] "A" Vector__XXX
 SG_ HVJBTemperatureState : 48|2@1+ (1,0) [0|3] "state" Vector__XXX
 SG_ HVJB_05MessageCounter : 52|4@1+ (1,0) [0|15] "count" Vector__XXX
 SG_ HVJB_05MessageChecksum : 56|8@1+ (1,0) [0|255] "count" Vector__XXX

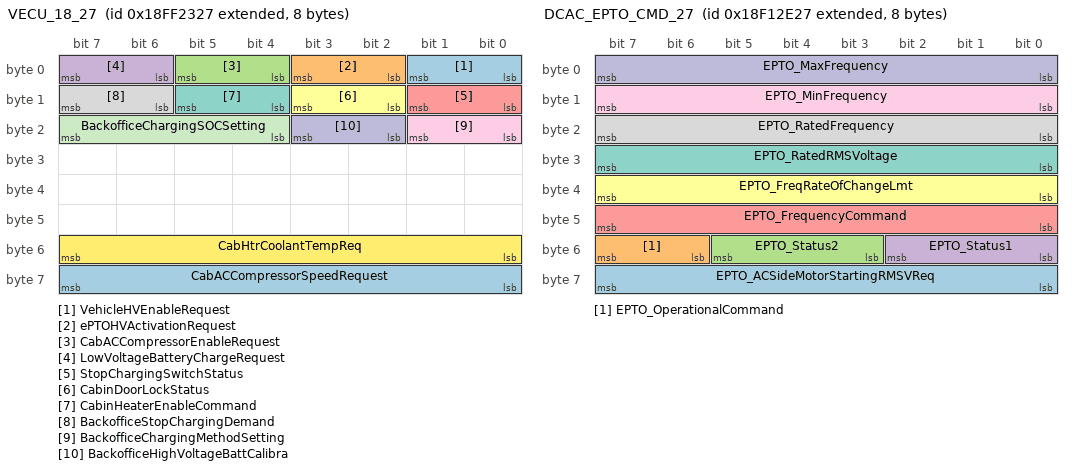
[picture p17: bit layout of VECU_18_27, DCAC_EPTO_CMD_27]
BO_ 2566857511 VECU_18_27: 8 VECU_27
 SG_ VehicleHVEnableRequest : 0|2@1+ (1,0) [0|3] "state" Vector__XXX
 SG_ ePTOHVActivationRequest : 2|2@1+ (1,0) [0|3] "state" Vector__XXX
 SG_ CabACCompressorEnableRequest : 4|2@1+ (1,0) [0|3] "state" Vector__XXX
 SG_ LowVoltageBatteryChargeRequest : 6|2@1+ (1,0) [0|3] "state" Vector__XXX
 SG_ StopChargingSwitchStatus : 8|2@1+ (1,0) [0|3] "state" Vector__XXX
 SG_ CabinDoorLockStatus : 10|2@1+ (1,0) [0|3] "state" Vector__XXX
 SG_ CabinHeaterEnableCommand : 12|2@1+ (1,0) [0|3] "state" Vector__XXX
 SG_ BackofficeStopChargingDemand : 14|2@1+ (1,0) [0|3] "state" Vector__XXX
 SG_ BackofficeChargingMethodSetting : 16|2@1+ (1,0) [0|3] "state" Vector__XXX
 SG_ BackofficeHighVoltageBattCalibra : 18|2@1+ (1,0) [0|3] "state" Vector__XXX
 SG_ BackofficeChargingSOCSetting : 20|4@1+ (1,0) [0|15] "state" Vector__XXX
 SG_ CabHtrCoolantTempReq : 48|8@1+ (1,-40) [-40|210] "degC" Vector__XXX
 SG_ CabACCompressorSpeedRequest : 56|8@1+ (50,0) [0|12500] "rpm" Vector__XXX

BO_ 2565942823 DCAC_EPTO_CMD_27: 8 VECU_27
 SG_ EPTO_ACSideMotorStartingRMSVReq : 56|8@1+ (2,0) [0|500] "V" Vector__XXX
 SG_ EPTO_OperationalCommand : 54|2@1+ (1,0) [0|3] "" Vector__XXX
 SG_ EPTO_Status2 : 51|3@1+ (1,0) [0|7] "" Vector__XXX
 SG_ EPTO_Status1 : 48|3@1+ (1,0) [0|7] "" Vector__XXX
 SG_ EPTO_FrequencyCommand : 40|8@1+ (1,0) [0|250] "Hz" Vector__XXX
 SG_ EPTO_FreqRateOfChangeLmt : 32|8@1+ (2,0) [0|500] "Hz/s" Vector__XXX
 SG_ EPTO_RatedRMSVoltage : 24|8@1+ (2,0) [0|500] "V" Vector__XXX
 SG_ EPTO_RatedFrequency : 16|8@1+ (1,0) [0|250] "Hz" Vector__XXX
 SG_ EPTO_MinFrequency : 8|8@1+ (1,0) [0|250] "Hz" Vector__XXX
 SG_ EPTO_MaxFrequency : 0|8@1+ (1,0) [0|250] "Hz" Vector__XXX

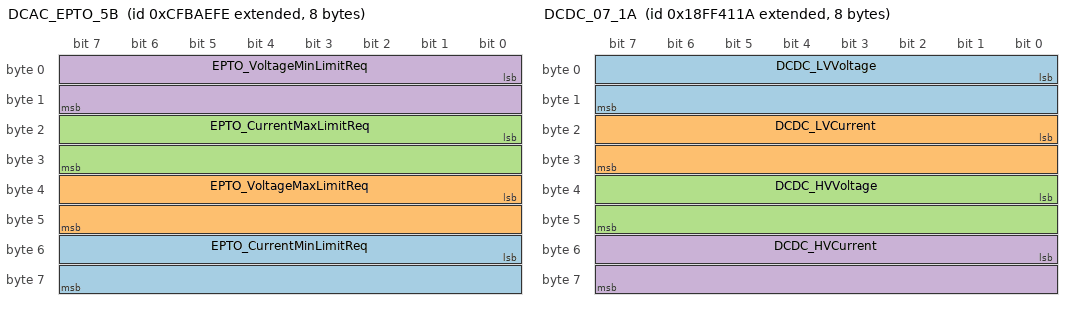
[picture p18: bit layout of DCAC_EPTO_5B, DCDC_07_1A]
BO_ 2365304574 DCAC_EPTO_5B: 8 PPC_HV_5B
 SG_ EPTO_CurrentMinLimitReq : 48|16@1+ (0.05,-3212.75) [-3212.75|0] "A" Vector__XXX
 SG_ EPTO_VoltageMaxLimitReq : 32|16@1+ (0.05,0) [0|3212.75] "V" Vector__XXX
 SG_ EPTO_CurrentMaxLimitReq : 16|16@1+ (0.05,0) [0|3212.75] "A" Vector__XXX
 SG_ EPTO_VoltageMinLimitReq : 0|16@1+ (0.05,0) [0|3212.75] "V" Vector__XXX

BO_ 2566865178 DCDC_07_1A: 8 DCDC_1A
 SG_ DCDC_LVVoltage : 0|16@1+ (0.05,0) [0|3276.75] "V" Vector__XXX
 SG_ DCDC_LVCurrent : 16|16@1+ (0.05,-1600) [-1600|1676.75] "A" Vector__XXX
 SG_ DCDC_HVVoltage : 32|16@1+ (0.05,0) [0|3276.75] "V" Vector__XXX
 SG_ DCDC_HVCurrent : 48|16@1+ (0.05,-1600) [-1600|1676.75] "A" Vector__XXX

BO_ 2365573467 HVS_04_5B: 8 PPC_HV_5B
 SG_ HVESSModeRequest : 0|2@1+ (1,0) [0|3] "state" Vector__XXX
 SG_ HVESSStopPreconditioningRequest : 2|2@1+ (1,0) [0|3] "state" Vector__XXX

CM_ BO_ 2566613851 "High Voltage Bus Information : High Voltage Bus Information";
CM_ BO_ 2566658651 "HVESS Thermal Management System Control 1 : Control requests to be sent to High Voltage Energy Storage System (or Pack 1 in systems with only one pack) Thermal Management System.";
CM_ SG_ 2566658651 HVESSThermalManagementSystemHtrE "SPN:20457 VVR:[0,1]
Command to enable HVESS Thermal Management heater.
00b = Disable Heater
01b = Enable Heater
10b = Reserved
11b = Dont Care/Take no action";
CM_ BO_ 2566675956 "High Voltage Energy Storage System Configuration : Configuration data for High Voltage Energy Storage System (or Pack 1 in systems with only one pack).Note that configuration data should not dynamically change during vehicle operation.";
CM_ SG_ 2566675956 HVESSNominalVoltage "SPN 8115";
CM_ SG_ 2566675956 HVESSNumberofHVESPsConfigured "SPN 12904";
CM_ BO_ 2566722907 "Battery Charger 1 : Parameters for the battery charger connected to the main battery.";
CM_ SG_ 2566722907 BatteryCharger1State "SPN:4990 VVR:[0,2]
A state of the battery charger connected to the main battery.";
CM_ SG_ 2566722907 BatteryCharger1PowerLineState "SPN:4991
A state of the battery charger connection to the power line for the charger connected to the main battery.";
CM_ SG_ 2566722907 BatteryCharger1OutputVoltage "SPN:4992 VVR:[0,64255]
Output voltage measured on the battery terminals of the battery charger connected to the main battery.";
CM_ SG_ 2566722907 BatteryCharger1OutputCurrent "SPN:4993
Output current of the battery charger connected to the main battery. If positive, this parameter shows the charging current of the battery charger connected to the main battery.  ";
CM_ SG_ 2566722907 BCH1_RestartRequiredState "Indicates that the battery charger requires a restart due to an exception event.
The battery charger operates in conjunction with the vehicle's HVESS controller. The HVESS will control the charger's output by sending current and voltage limits ...";
CM_ BO_ 2566771751 "Cab Message 3 : Provides information from Cab mounted operator inputs.";
CM_ SG_ 2566771751 OperatorKeySwitchIgnitionPower "SPN:10145
Indicates that the ignition (or run) state of the operator key switch is active.";
CM_ BO_ 2566827568 "Air Supply Pressure : Air Supply Pressure";
CM_ SG_ 2566827568 ServiceBrakeCircuit1AirPressure "SPN:1087 VVR:[0,250]
The pneumatic pressure in the primary service brake circuit or reservoir, supplying the rear axle.";
CM_ SG_ 2566827568 ServiceBrakeCircuit2AirPressure "SPN:1088 VVR:[0,250]
The pneumatic pressure in the secondary service brake circuit or reservoir, supplying the front axle.";
CM_ SG_ 2566827568 AirCompressorStatus "SPN:1351
Indicates whether the air compressor is actively compressing air.
00     Compressor not active
01     Compressor active
10     Error indicator
11     Not available";
CM_ BO_ 2566832423 "GTW: High Resolution Vehicle Distance : ";
CM_ BO_ 2566832622 "High Resolution Vehicle Distance : ";
CM_ SG_ 2566832622 TotalVehicleDistHighResolution "SPN:917
Accumulated distance traveled by the vehicle during its operation.
NOTE - See SPN 245 for alternate resolution.";
CM_ BO_ 2566840154 "Electronic Engine Controller 3 : ";
CM_ SG_ 2566840154 NominalFrictionPercentTorque "SPN:514
The calculated torque that indicates the amount of torque required by the basic engine itself added by the loss torque of accessories.";
CM_ BO_ 2566840666 "Retarder Configuration : This map describes the stationary behavior of the retarder.Note:  Grandfathered definition for systems that implemented this message prior to July, 2010: On change of torque/speed points of more than 10% since last transmission, or every 5 s.";
CM_ BO_ 2566841895 "GTW: Time/Date : ";
CM_ BO_ 2566842094 "Time/Date : ";
CM_ SG_ 2566842094 Seconds "SPN:959 VVR:[0,239]
The seconds component of the current time of day.  ";
CM_ SG_ 2566842094 Minutes "SPN:960 VVR:[0,59]
The minutes component of the current time of day. ";
CM_ SG_ 2566842094 Hours "SPN:961 VVR:[0,23]
The hour component of the current time of day.";
CM_ SG_ 2566842094 Month "SPN:963 VVR:[0,12]
The month component of the current calendar date. ";
CM_ SG_ 2566842094 Day "SPN:962 VVR:[1,127]
The day component of the current calendar date.  ";
CM_ BO_ 2566845696 "Ambient Conditions : ";
CM_ SG_ 2566845696 BarometricPressure "SPN:108 VVR:[0,250]
Absolute air pressure of the atmosphere.";
CM_ SG_ 2566845696 AmbientAirTemperature "SPN:171
Temperature of air surrounding vehicle.";
CM_ BO_ 2566803211 "Vehicle Dynamic Stability Control 1 : Contains information which relates to the VDC system status.";
CM_ SG_ 2566803211 VDCbrakelightrequest "SPN:1815 VVR:[0,1]
Indicates whether VDC requests to turn the vehicle brake lights on
00 Turn brake light not on
01 Turn brake light on
10 Reserved
11 Dont care/Take no action";
CM_ SG_ 2566803211 ROPEngineControlactive "SPN:1816 VVR:[0,1]
State Signal which indicates that the Roll Over Prevention (ROP) has commanded engine control to be active. ";
CM_ SG_ 2566803211 ROPBrakeControlactive "SPN:1818 VVR:[0,1]
State signal which indicates that Roll over Prevention (ROP) has activated brake control.";
CM_ SG_ 2566803211 YCEngineControlactive "SPN:1817 VVR:[0,1]
State Signal which indicates that the Yaw Control (YC) has commanded engine control to be active.";
CM_ SG_ 2566803211 YCBrakeControlactive "SPN:1819 VVR:[0,1]
State signal which indicates that Yaw Control (YC) has activated brake control.";
CM_ BO_ 2565867787 "Vehicle Dynamic Stability Control 2 : Contains information which relates to the vehicle's movement.";
CM_ SG_ 2565867787 SteeringWheelAngle "SPN:1807
The main operator`s steering wheel angle (on the steering column, not the actual wheel angle). ";
CM_ SG_ 2565867787 LongitudinalAcceleration "SPN:1810
Indicates the longitudinal acceleration of the vehicle. A positive longitudinal acceleration signal results when the vehicle speed increases,";
CM_ BO_ 2566878532 "PropB_HVCH_02 : High Voltage Cabin Heater Status Message";
CM_ SG_ 2566878532 CabinHeaterStatus "SPN:521903 VVR:[0,1]
00b = Disabled
01b = Enabled
10b = Reserved
11b = Not available";
CM_ SG_ 2566878532 CabinHeaterHVILStatus "SPN:521905 VVR:[0,1]
00b = HVIL Closed
01b = HVIL Open
10b = Reserved
11b = Not Available";
CM_ SG_ 2566878532 CabinHtrOutputCoolantTemperature "SPN:521904
";
CM_ SG_ 2566878532 CabinHeaterCurrent "SPN:521906 VVR:[0,64255]
";
CM_ SG_ 2566878532 CabinHeaterVoltage "SPN:521907 VVR:[0,64255]
";
CM_ SG_ 2566878532 CabinHeaterInternalCurrentLimit "SPN:521908 VVR:[0,64255]
";
CM_ BO_ 2633727015 "Wake : Reserved for Network Operation Mode";
CM_ SG_ 2633727015 ControlBitVector "SPN:8623
The Control Bit Vector shall consist of:
Bit 0: Repeat Message Request
Bit 3: NM Coordinator Sleep Bit
Bit 4 Active Wakeup Bit
";
CM_ BO_ 2633727067 "Wake : Reserved for Network Operation Mode";
CM_ SG_ 2633727067 ControlBitVector "SPN:8623
The Control Bit Vector shall consist of:
Bit 0: Repeat Message Request
Bit 3: NM Coordinator Sleep Bit
Bit 4 Active Wakeup Bit
";
CM_ BO_ 2566549595 "Inverter 1 Lifetime Data
Contains data accumulated over the lifetime of this Inverter.";
CM_ SG_ 2566549595 PwrConv1TotalChargeGenerated "Indicates the total lifetime charge generated by this Inverter.  For example, this would include the charge created during regerative braking in a propulsion system.";
CM_ SG_ 2566549595 PwrConv1TotalChargeConsumed "Indicates the total lifetime charge consumed by this Inverter.  For example, this would include the charge used for propulsion in a propulsion system.";
CM_ SG_ 2566549595 PwrConv1TotalEnergyGenerated "Indicates the total lifetime energy generated by this Inverter.  For example, this would include the energy created during regerative braking in a propulsion system.";
CM_ SG_ 2566549595 PwrConv1TotalEnergyConsumed "Indicates the total lifetime energy consumed by this Inverter.  For example, this would include the energy used for propulsion in a propulsion system.";
CM_ BO_ 2566549851 "Inverter 2 Lifetime Data
Contains data accumulated over the lifetime of this Inverter.";
CM_ SG_ 2566549851 PwrConv2TotalChargeGenerated "Indicates the total lifetime charge generated by this Inverter.  For example, this would include the charge created during regerative braking in a propulsion system.";
CM_ SG_ 2566549851 PwrConv2TotalChargeConsumed "Indicates the total lifetime charge consumed by this Inverter.  For example, this would include the charge used for propulsion in a propulsion system.";
CM_ SG_ 2566549851 PwrConv2TotalEnergyGenerated "Indicates the total lifetime energy generated by this Inverter.  For example, this would include the energy created during regerative braking in a propulsion system.";
CM_ SG_ 2566549851 PwrConv2TotalEnergyConsumed "Indicates the total lifetime energy consumed by this Inverter.  For example, this would include the energy used for propulsion in a propulsion system.";
CM_ BO_ 2566569307 "Motor/Generator 1 Lifetime Data
Contains data accumulated over the lifetime of this Motor/Generator.";
CM_ SG_ 2566569307 MG1_TotalChargeGenerated "Indicates the total lifetime charge generated by this Motor/Generator.  For example, this would include the charge created during regerative braking in a propulsion motor.";
CM_ SG_ 2566569307 MG1_TotalChargeConsumed "Indicates the total lifetime charge consumed by this Motor/Generator.  For example, this would include the charge used for propulsion in a propulsion motor.";
CM_ SG_ 2566569307 MG1_TotalEnergyGenerated "Indicates the total lifetime energy generated by this Motor/Generator.  For example, this would include the energy created during regerative braking in a propulsion motor.";
CM_ SG_ 2566569307 MG1_TotalEnergyConsumed "Indicates the total lifetime energy consumed by this Motor/Generator.  For example, this would include the energy used for propulsion in a propulsion motor.";
CM_ BO_ 2365557851 "PropB_HVS_01 : Control commands to be sent to High Voltage Junction Box.";
CM_ SG_ 2365557851 DriveContactorCommand "SPN:521910 VVR:[0,1]
Command to connect the Drive Contactor
00b = Open contactor
01b = Close contactor
10b = Reserved
11b = Not available";
CM_ SG_ 2365557851 DriveContactorPowerDownCommand "SPN:520064
Command to shut down the High Voltage Contactor Group.
00b = Power-down not requested
01b = Execute normal power-down
10b = Execute emergency power-down
11b = Dont care/Take no action";
CM_ SG_ 2365557851 AuxiliaryContactorCommand "SPN:521914 VVR:[0,1]
Command to connect the Auxiliary Contactor
00b = Open contactor
01b = Close contactor
10b = Reserved
11b = Not available";
CM_ SG_ 2365557851 AuxiliaryContactorPowerDownCmd "SPN:520065
Command to shut down the High Voltage Contactor Group.
00b = Power-down not requested
01b = Execute normal power-down
10b = Execute emergency power-down
11b = Dont care/Take no action";
CM_ SG_ 2365557851 ePTOContactorCommand "SPN:521916 VVR:[0,1]
Command to connect the ePTO Contactor
00b = Open contactor
01b = Close contactor
10b = Reserved
11b = Not available";
CM_ SG_ 2365557851 ePTOContactorPowerDownCommand "SPN:520066
Command to shut down the High Voltage Contactor Group.
00b = Power-down not requested
01b = Execute normal power-down
10b = Execute emergency power-down
11b = Dont care/Take no action";
CM_ SG_ 2365557851 OnboardChargerContactorCommand "SPN:521918 VVR:[0,1]
Command to connect the On Board Charger Contactor
00b = Open contactor
01b = Close contactor
10b = Reserved
11b = Not available";
CM_ SG_ 2365557851 OnboardContactorPowerDownCommand "SPN:520067
Command to shut down the High Voltage Contactor Group.
00b = Power-down not requested
01b = Execute normal power-down
10b = Execute emergency power-down
11b = Dont care/Take no action";
CM_ SG_ 2365557851 OffBoardChargerContactorCmd "SPN:521920 VVR:[0,1]
Command to connect the Off Board Charger + Contactor
00b = Open contactor
01b = Close contactor
10b = Reserved
11b = Not available";
CM_ SG_ 2365557851 OffBoardContactorPowerDownCmd "SPN:520068
Command to shut down the High Voltage Contactor Group.
00b = Power-down not requested
01b = Execute normal power-down
10b = Execute emergency power-down
11b = Dont care/Take no action";
CM_ SG_ 2365557851 ActiveIsolationTest "SPN:521951
Command for the High Voltage Junction Box to perform an active electrical isolation test on the high voltage bus.";
CM_ SG_ 2365557851 MessageCounter "SPN:521922
The message counter is used to detect situations where the transmitting ECU malfunction repeats the same frame all the time. ";
CM_ SG_ 2365557851 MessageChecksum "SPN:521923
The CRC is defined as follows:
";
CM_ BO_ 2583630375 "PropB_ScheduledChargingConditioning_01 : Control commands of the schedule energy usage function to enable charging and/or vehicle conditioning.";
CM_ SG_ 2583630375 ScheduledChargingConditioningSta "SPN:520041 VVR:[0,1]
Status of the Scheduled Charging / Conditioning function.
00b = Not active
01b = Active
10b = Reserved
11b = Not available";
CM_ SG_ 2583630375 ScheduledChargingStartDemand "SPN:520042 VVR:[0,1]
Demand to start the Scheduled Charging.
00b = Not active
01b = Active
10b = Reserved
11b = Not available";
CM_ SG_ 2583630375 ScheduledBatConditioningCharging "SPN:520043 VVR:[0,1]
Demand to start the Scheduled Conditioning function for charging.
00b = Not active
01b = Active
10b = Reserved
11b = Not available";
CM_ SG_ 2583630375 ScheduledBatConditioningDriveOff "SPN:520044 VVR:[0,1]
Status of the Scheduled Charging / Conditioning function for drive off.
00b = Not active
01b = Active
10b = Reserved
11b = Not available";
CM_ BO_ 2556952103 "Electrified Accessory Generator Coolant Fan Command
The command message to the electrified accessory: Generator Coolant Fan.   See PGN 64382 for the corresponding status message.";
CM_ SG_ 2556952103 PercentSpdCmd "Speed command to the Generator Coolant Fan in percentage of maximum speed.";
CM_ SG_ 2556952103 SpdCmd "Speed command to the Generator Coolant Fan.
Note: Both Speed Command and Percent Speed Command cannot be used at the same time.  Always set the unused speed command to Not Available.  If both commands are set to Not Available, a preprogrammed ...";
CM_ SG_ 2556952103 PwrHold "Command to allow the Generator Coolant Fan to remain alive independently of the electrical enable input to the Accessory Motor. ";
CM_ SG_ 2556952103 EnableCmd "Enable and direction command to the Generator Coolant Fan.";
CM_ BO_ 2365558046 "PropB_HVJB_01 : High Voltage Junction Box Status";
CM_ SG_ 2365558046 DriveContactorState "SPN:521924
Status of the Drive Contactor
00b = Contactor Open
01b = Contactor Closed
10b = Error
11b = Not available";
CM_ SG_ 2365558046 DrivePreChargeContactorState "SPN:521925
Status of the Drive Pre-Charge Contactor
00b = Contactor Open
01b = Contactor Closed
10b = Error
11b = Not available";
CM_ SG_ 2365558046 DriveContactorErrorState "SPN:520070
Status of the Drive Contactor
00b = Other error
01b = Failed to Open
10b = Failed to Close
11b = Take no action (leave function as is)";
CM_ SG_ 2365558046 DrivePreChargeContactorErrorStat "SPN:520071
Status of the Drive Contactor
00b = Other error
01b = Failed to Open
10b = Failed to Close
11b = Take no action (leave function as is)";
CM_ SG_ 2365558046 AuxiliaryContactorState "SPN:521928
Status of the Auxiliary Contactor
00b = Contactor Open
01b = Contactor Closed
10b = Error
11b = Not available";
CM_ SG_ 2365558046 AuxiliaryPreChargeContactorState "SPN:521929
Status of the Auxiliary Pre-Charge Contactor
00b = Contactor Open
01b = Contactor Closed
10b = Error
11b = Not available";
CM_ SG_ 2365558046 AuxiliaryContactorErrorState "SPN:520072
Status of the Drive Contactor
00b = Other error
01b = Failed to Open
10b = Failed to Close
11b = Take no action (leave function as is)";
CM_ SG_ 2365558046 AuxiliaryPreChargeContactorError "SPN:520073
Status of the Drive Contactor
00b = Other error
01b = Failed to Open
10b = Failed to Close
11b = Take no action (leave function as is)";
CM_ SG_ 2365558046 ePTOPositiveContactorState "SPN:521930
Status of the ePTO Contactor
00b = Contactor Open
01b = Contactor Closed
10b = Error
11b = Not available";
CM_ SG_ 2365558046 ePTOPreChargeContactorState "SPN:521931
Status of the ePTO Pre-Charge Contactor
00b = Contactor Open
01b = Contactor Closed
10b = Error
11b = Not available";
CM_ SG_ 2365558046 ePTOPositiveContactorErrorState "SPN:520074
Status of the Drive Contactor
00b = Other error
01b = Failed to Open
10b = Failed to Close
11b = Take no action (leave function as is)";
CM_ SG_ 2365558046 ePTOPreChargeContactorErrorState "SPN:520075
Status of the Drive Contactor
00b = Other error
01b = Failed to Open
10b = Failed to Close
11b = Take no action (leave function as is)";
CM_ SG_ 2365558046 ePTONegativeContactorState "SPN:521950
Status of the ePTO Contactor
00b = Contactor Open
01b = Contactor Closed
10b = Error
11b = Not available";
CM_ SG_ 2365558046 OnboardChargerContactorState_IM3 "SPN:521932
Status of the On Board Contactor
00b = Contactor Open
01b = Contactor Closed
10b = Error
11b = Not available";
CM_ SG_ 2365558046 ePTONegativeContactorErrorState "SPN:520076
Status of the Drive Contactor
00b = Other error
01b = Failed to Open
10b = Failed to Close
11b = Take no action (leave function as is)";
CM_ SG_ 2365558046 OnboardChargerContactorErrorStat "SPN:520077
Status of the Onboard Charger  Contactor
00b = Other error
01b = Failed to Open
10b = Failed to Close
11b = Take no action (leave function as is)";
CM_ SG_ 2365558046 OffBoardChargerPosContactorState "SPN:521934
Status of the Off Board Positive Contactor
00b = Contactor Open
01b = Contactor Closed
10b = Error
11b = Not available";
CM_ SG_ 2365558046 OffBoardChargerNegContactorState "SPN:521935
Status of the Off board Negative Contactor
00b = Contactor Open
01b = Contactor Closed
10b = Error
11b = Not available";
CM_ SG_ 2365558046 OffBoardChargerPosContactorError "SPN:520078
Status of the Off Board Charger Positive Contactor
00b = Other error
01b = Failed to Open
10b = Failed to Close
11b = Take no action (leave function as is)";
CM_ SG_ 2365558046 OffBoardChargerNegContactorError "SPN:520079
Status of the Off Board Charger Negative Contactor
00b = Other error
01b = Failed to Open
10b = Failed to Close
11b = Take no action (leave function as is)";
CM_ SG_ 2365558046 HVILStatus1_Drive "SPN:521936
Reports the High Voltage Interlock Loop (HVIL) state.
00b = HVIL Closed
01b = HVIL Open
10b = Error
11b = Not Available";
CM_ SG_ 2365558046 HVILStatus2_Aux "SPN:521937
Reports the High Voltage Interlock Loop (HVIL) state.
00b = HVIL Closed
01b = HVIL Open
10b = Error
11b = Not Available";
CM_ SG_ 2365558046 HVILStatus3_ePTO "SPN:521938
Reports the High Voltage Interlock Loop (HVIL) state.
00b = HVIL Closed
01b = HVIL Open
10b = Error
11b = Not Available";
CM_ SG_ 2365558046 HVJB_OperationalState "SPN:520061 VVR:[0,1]
Operational State of the HVJB
0000b = Startup, self initialization ongoing.
0001b = Operational, ready to accept commands
0010b-1101b = Reserved
1110b = Error
1111b = Not available";
CM_ SG_ 2365558046 HVJB_01MessageCounter "SPN:521939
The message counter will count from 0 to 15 and then restart at 0.
Since there is no Not Available state, the sender must support the counter.";
CM_ SG_ 2365558046 HVJB_01MessageChecksum "SPN:521940
The CRC is defined as follows:
- Length: 8 bits
- Polynomial: x^8+x^5+x^3+x^2+x+1
- Initial Value: FFh
";
CM_ BO_ 2365558302 "PropB_HVJB_02 : HV Junction Box Current measurements";
CM_ SG_ 2365558302 DriveContactorActualCurrent "SPN:521941
The setting defines the Drive Contactor Actual current";
CM_ SG_ 2365558302 AuxiliaryContactorActualCurrent "SPN:521942
The setting defines the Auxiliary Contactor Actual Current";
CM_ SG_ 2365558302 ePTOContactorActualCurrent "SPN:521943
The setting defines the PTO Contactor Actual Current";
CM_ BO_ 2365558558 "PropB_HVJB_03 : HV Junction Box Voltage measurements";
CM_ SG_ 2365558558 OffBoardChargerActualVoltage "SPN:521945
The setting defines the Actual Off Board Voltage level";
CM_ BO_ 2365571870 "PropB_HVJB_04 : HV Junction Box Voltage Isolation Measurements";
CM_ SG_ 2365571870 IsolationMonitorMeasurementType "SPN:522015
Measurement type of the isolation monitoring.
00b = Estimation
01b = Measured value during startup (first measurement pulse)
10b = Measured value (normal measurement)
11b = Not available";
CM_ SG_ 2365571870 TestResultsPositive "SPN:521953 VVR:[0,64255]
The isolation resistance of the high voltage positive wire expressed in Ohms per Volt that resulted from the High Voltage Bus Active Isolation Test.";
CM_ SG_ 2365571870 TestResultsNegative "SPN:521954 VVR:[0,64255]
The isolation resistance of the high voltage negative wire expressed in Ohms per Volt that resulted from the High Voltage Bus Active Isolation Test.";
CM_ BO_ 2566613790 "High Voltage Bus Information : High Voltage Bus Information";
CM_ BO_ 2364607476 "High Voltage Energy Storage System Data 9
Data set 9 (thermal) for High Voltage Energy Storage System (or Pack 1 in systems with only one pack).";
CM_ SG_ 2364607476 HVESSThermalEventDetected "A sensor has detected the presence of a thermal event at or near HVESS.
00b = No Thermal Event Detected
01b = Thermal Event Detected
10b = Error
11b = Not available";
CM_ SG_ 2364607476 HVESSLowestCellTempCellNum "Identifies the location of SPN 8076 (HVESS Lowest Cell Temperature) within SPN 8243 (HVESS Lowest Cell Temperature Module Number).
This parameter provides HVES system level information. If there are multiple packs in the system, then both ...";
CM_ SG_ 2364607476 HVESSLowestCellTempModuleNum "Identifies the location of the module containing SPN 8076 (HVESS Lowest Cell Temperature ).";
CM_ SG_ 2364607476 HVESSHighestCellTempCellNum "Identifies the location of SPN 8075 (HVESS Highest Cell Temperature) within SPN 8241 (HVESS Highest Cell Temperature Module Number).";
CM_ SG_ 2364607476 HVESSHighestCellTempModuleNum "Identifies the location of the module containing SPN 8075 (HVESS Highest Cell Temperature).";
CM_ BO_ 2583632219 "HVS_05_5B";
CM_ SG_ 2583632219 CabinACCompressorSpeed "CabinACCompressorSpeed";
CM_ SG_ 2583632219 CabinACCompressorErrorStatus "CabinACCompressorErrorStatus";
CM_ BO_ 2583631911 "VECU_19_27";
CM_ SG_ 2583631911 UrgeToMoveActivationDemand "UrgeToMoveActivationDemand";
CM_ SG_ 2583631911 UrgeToMoveOverruleDemand "UrgeToMoveOverruleDemand";
CM_ SG_ 2583631911 UrgeToMoveStatus "UrgeToMoveStatus";
CM_ BO_ 2566810971 "HTR_HVS_5B";
CM_ SG_ 2566810971 AuxiliaryHeaterMode "AuxiliaryHeaterMode";
CM_ BO_ 2583631655 "BCR_01_27";
CM_ SG_ 2583631655 EnergyCapResPluginCharging "HVESSEnergyCapacityReservationPluginCharging";
CM_ SG_ 2583631655 EnergyCapResRegenerativeBraking "HVESSEnergyCapacityReservationRegenerativeBraking";
CM_ BO_ 2583629847 "DD_06_17";
CM_ SG_ 2583629847 ChargingMethodSetting "ChargingMethodSetting";
CM_ SG_ 2583629847 ServiceMenuHVDisableDemand "ServiceMenuHighVoltageDisableDemand";
CM_ SG_ 2583629847 HVBatteryCalibrationDemand "HighVoltageBatteryCalibrationDemand";
CM_ SG_ 2583629847 ChargingSOCSetting "ChargingSOCSetting";
CM_ SG_ 2583629847 ChargingCurrentLimitSetting "ChargingCurrentLimitSetting";
CM_ BO_ 2583631604 "HVESS_02_F4";
CM_ SG_ 2583631604 HVESSContinuousChargeCurrent "HVESSContinuousChargeCurrent";
CM_ SG_ 2583631604 HVESSContinuousChargePower "HVESSContinuousChargePower";
CM_ SG_ 2583631604 HVESSMode "HVESSMode";
CM_ SG_ 2583631604 HVESSChargedEnergyCycleCounter "HVESSChargedEnergyCycleCounter";
CM_ BO_ 2566889563 "HVS_02_5B";
CM_ SG_ 2566889563 StopChargingSwitchIndication "StopChargingSwitchIndication";
CM_ SG_ 2566889563 ChargingState "ChargingState";
CM_ SG_ 2566889563 ChargePlugLockedStatus "ChargePlugLockedStatus";
CM_ SG_ 2566889563 ChargePlugUnlockedStatus "ChargePlugUnlockedStatus";
CM_ SG_ 2566889563 ChargePlugNotSuppNotification "ChargePlugNotSupportedNotification";
CM_ SG_ 2566889563 ChargePlugTempNotification "ChargePlugTemperatureNotification";
CM_ SG_ 2566889563 ChargingInterlockParkBrake "ChargingInterlockParkBrake";
CM_ SG_ 2566889563 EVSEErrorNotification "EVSEErrorNotification";
CM_ SG_ 2566889563 EVSECommErrorNotification "EVSECommunicationErrorNotification";
CM_ SG_ 2566889563 EVSEVoltageRangeNotification "EVSEVoltageRangeNotification";
CM_ SG_ 2566889563 EVSECurrentRangeNotification "EVSECurrentRangeNotification";
CM_ SG_ 2566889563 EVSEIsolationFailNotification "EVSEIsolationFailureNotification";
CM_ SG_ 2566889563 ChargeSessVehRestartNotification "ChargingSessionVehicleRestartNotification";
CM_ SG_ 2566889563 HVBatteryCalibrationStatus "HighVoltageBatteryCalibrationStatus";
CM_ SG_ 2566889563 HVBattCalibrationPlannedForNextC "HighVoltageBatteryCalibrationPlannedforNextCharging";
CM_ SG_ 2566889563 ChargingSOCActualSetting "ChargingSOCActualSetting";
CM_ SG_ 2566889563 ChargeSOCDriverSettingNotPossibl "ChargingSOCDriverSettingNotPossibleIndication";
CM_ SG_ 2566889563 ChargingMethodSelected "ChargingMethodSelected";
CM_ SG_ 2566889563 ChargingSOCTarget "ChargingSOCTarget";
CM_ BO_ 2566890587 "HVS_03_5B";
CM_ SG_ 2566890587 ActualPercenteDrivePower "ActualPercenteDrivePower";
CM_ SG_ 2566890587 ActualPercentePTOPower "ActualPercentePTOPower";
CM_ SG_ 2566890587 MaxPercenteDrivePropulsionPowe "MaximumPercenteDrivePropulsionPower";
CM_ SG_ 2566890587 MaxPercenteDriveRegenPower "MaximumPercenteDriveRegenerationPower";
CM_ SG_ 2566890587 HVBatteryUsageClassification "HighVoltageBatteryUsageClassification";
CM_ SG_ 2566890587 RegenBrakingLimitedReason "RegenerativeBrakingLimitedReason";
CM_ SG_ 2566890587 EHPSControlStatus "EHPSControlStatus";
CM_ SG_ 2566890587 RegenBrakingLimitedNotification "RegenerativeBrakingLimitedNotification";
CM_ SG_ 2566890587 HVACCompressorDemand "HVACCompressorDemand";
CM_ BO_ 2364577115 "HVESSD6_HVS_5B";
CM_ SG_ 2364577115 HVESSIntakeCoolantTemperature "HVESSIntakeCoolantTemperature";
CM_ BO_ 2566775131 "CCSI1_HVS_5B";
CM_ SG_ 2566775131 AirConditionerCompressorStatus "AirConditionerCompressorStatus";
CM_ BO_ 2566573919 "EVCC1 Diagnostic Data 1
Reports this EVCC internal parameters for diagnostic purposes.";
CM_ SG_ 2566573919 CompatibilityCode "Indicates incompatability between the vehicle and the EVSE.";
CM_ SG_ 2566573919 InletConnectorTemp "Temperature reading at the vehicle inlet connector.";
CM_ SG_ 2566573919 ProximityCircVoltage "The cable from the EVSE may contain a resistive proximity circuit.  Resistors are built into both the cable and inlet sides of the connectors and are supplied from a DC source....";
CM_ SG_ 2566573919 CtrlPilotSubState "Indicates the EVSE sub-state as determined by the frequency of the Control Pilot as defined by IEC-61851 and J1772.";
CM_ SG_ 2566573919 CtrlPilotState "Indicates the EVSE state as determined by the peak voltage level of the Control Pilot and representing states A to F as defined by IEC-61851 and J1772.";
CM_ SG_ 2566573919 CtrlPilotDutyCycle "The control pilot from the off-board EVSE is either a DC signal or a square wave. This parameter contains the duty cycle of the PWM square wave.";
CM_ SG_ 2566573919 CtrlPilotPWMFreq "The control pilot from the off-board EVSE is either a DC signal or a square wave. This parameter contains either zero when a DC value or the frequency when a square wave.";
CM_ SG_ 2566573919 CtrlPilotMinVoltage "The control pilot from the off-board EVSE is either a DC signal or a square wave. This parameter contains the DC value or the minimum voltage of the square wave.";
CM_ SG_ 2566573919 CtrlPilotMaxVoltage "The control pilot from the off-board EVSE is either a DC signal or a square wave. This parameter contains the DC value or the maximum voltage of the square wave.";
CM_ BO_ 2566567003 "EV DC Charging Limits 1
Data used by the EVCC when negotiating charging limits with an EVSE that supports DC charging.";
CM_ SG_ 2566567003 EVSupportedEnergyTransferTypes "Hybrid  or Electric vehicle's required Energy transfer type
0000b = DC-Extended
0001b = DC-Core
0010b to 1111b = reserved
This parameter is mandatory, one of the non-reserved values must be specified.
See J2847-2 201504 Sect 4.2.32";
CM_ SG_ 2566567003 EVDCChargingPwrMax "Hybrid or Electric Vehicle's maximum rated DC charging input power.
This is communicated to a DC EVSE during initial exchange of parameters.
When charging, the smallest value of this and SPN 13161 (EVSE DC Charging Power Maximum) will be used.
...";
CM_ SG_ 2566567003 EVDCChargingCurMax "Hybrid or Electric Vehicle's maximum rated DC charging input current.
This is communicated to a DC EVSE during initial exchange of parameters.
When charging, the smallest value of this and SPN 13160 (EVSE DC Charging Current Maximum) will be used.
...";
CM_ SG_ 2566567003 EVDCChargingVMax "Hybrid or Electric Vehicle's maximum rated DC charging input voltage.
This is communicated to a DC EVSE during initial exchange of parameters.
When charging, the smallest value of this and SPN 13159 (EVSE DC Charging Voltage Maximum) will be used.
...";
CM_ BO_ 2566544219 "EV DC Status 1
This message carries status of the vehicle during DC charging to the EVSE.";
CM_ SG_ 2566544219 ErrorCode "Indicates the highest priority EV internal error state that may inhibit/abort charging
See J2847-2 (April 2015 Section 4.2.26)
0000b = No Error
0001b = Battery Temperature too hot/cold
0010b = Shift Position  (Vehicle not in park)
0011b = ...";
CM_ SG_ 2566544219 RESSConditioningFlag "Informs the EVSE that the EV is using energy from the EVSE  to perform battery (RESS/HVES) conditioning.
See J2847-2 (April 2015 Section 4.2.33)
00b = Battery conditioning not active
01b = Battery conditioning active
10b = Reserved
11b = Not ...";
CM_ SG_ 2566544219 CabinConditioningFlag "Informs the EVSE that the EV is performing cabin conditioning.
See J2847-2 (April 2015 Section 4.2.23)
00b = Cabin conditioning not active
01b = Cabin conditioning active
10b = Reserved
11b = Not available";
CM_ BO_ 2566567771 "EV DC Charging Target
This message is sent to the EVCC (and forwarded to the EVSE) and sets the instantaneous limits to be applied during the charge cycle.";
CM_ SG_ 2566567771 TargetChargingCurrent "Hybrid or Electric vehicle's instantaneous requested DC output current limit.
See also:
SPN 13160 (EVSE DC Charging Current Maximum)
SPN 13164 (EVSE DC Charging Current Minimum)
SPN 13156 (Hybrid DC Charging Current Maximum)
SPN 13169 (DC ...";
CM_ SG_ 2566567771 TargetChargingVoltage "Hybrid or Electric vehicle's instantaneous requested DC output voltage limit.
See also:
SPN 13159 (EVSE DC Charging Voltage Maximum)
SPN 13163 (EVSE DC Charging Voltage Minimum)
SPN 13155 (Hybrid DC Charging Voltage Maximum)
SPN 13170 (DC ...";
CM_ SG_ 2566567771 EVDCTGT_Counter "The message counter is used to detect situations where the transmitting ECU malfunction repeats the same frame all the time. The receiver of the information may use the counter parameter to detect this situation. The transmitting device will ...";
CM_ SG_ 2566567771 EVDCTGT_CRC "8-bit CRC covering the following bytes in this PG.
The CRC is defined as follows:
ï Length: 8 bits
ï Polynomial: x^8+x^5+x^3+x^2+x+1
ï Initial Value: FFh
ï Input Data Reflection: Not reflected
ï Result Data Reflection: Not reflected
ï XOR ...";
CM_ BO_ 2566575455 "EVSE 1 AC Status 1
This message is sent by a CA that manages the connection to an AC Electric Vehicle Supply Equipment (EVSE).
The on-change transmission of this message is only needed for SP changes that require a time critical response.  For ...";
CM_ SG_ 2566575455 ACRMSCurrentLimitNeutral "Maximum AC RMS current that can carried on the neutral connection from the EVSE.
If this parameter is set to 0 A then only symmetrical 3-phase operation is allowed.";
CM_ SG_ 2566575455 ACRMSCurrentLimitL3 "Maximum AC RMS current that can be supplied by the EVSE on L3 of a 3-phase AC supply.";
CM_ SG_ 2566575455 ACRMSCurrentLimitL2 "Maximum AC RMS current that can be supplied by the EVSE on L2 of a 3-phase AC supply.";
CM_ SG_ 2566575455 ACRMSCurrentLimitL1 "Maximum AC RMS current that can be supplied by the EVSE on a single phase AC supply or L1 of a 3-phase AC supply.";
CM_ BO_ 2555600731 "EVSE 1 Control 1
This PG carries SPs associated with the control of the connection to the external power source.";
CM_ SG_ 2555600731 EVReady "Informs the EVSE that the EV is ready to charge.
Intended for use by systems that support multiple active power sources. If the connection to the EVSE has a control pilot signal, this parameter can be used to to switch the Control Pilot between ...";
CM_ SG_ 2555600731 DCStageReq "DC EVSE Charging stage request that may be used to cycle the connection to the EVSE through various phases of the charging cycle.
Some EVCC implementations will handle this sequencing internally, in which case this SP should be set to 1111b, Don't ...";
CM_ SG_ 2555600731 ConnectorLockCmd "Request to engage or disengage the locking mechanism fitted to this EVSE connector to the vehicle.
The actual Lock state will be reported via SPN 12863 (EVSE1 Connector Lock State).
This parameter shall be from only one source. However, it may be ...";
CM_ BO_ 2566568287 "EVSE 1 Contactor Cmd 1
Command sent to control the DC Charging Inlet Contactors, which are used to isolate vehicle's internal DC bus from the EVSE Inlet Connector.";
CM_ SG_ 2566568287 DCInletContactorCommand "Contactor command.
00b = Open Contactor
01b = Close Contactor
10b = Reserved
11b = Don't Care / Take no action";
CM_ BO_ 2566568539 "EVSE 1 Contactor Status 1
Status of the DC Charging Inlet Contactors, which are used to isolate vehicle's internal DC bus from the EVSE Inlet Connector.
There may be multiple senders of this PG in the system. However, typically each SP will only ...";
CM_ SG_ 2566568539 DCInletContactor1State "Indicates the state of DC Inlet Contactor 1.
00b = Contactor Open
01b = Contactor Closed
10b = Error- Contactor fault detected
11b = Not available";
CM_ SG_ 2566568539 DCChargingBusVoltage "Voltage measured on the HVES side of the DC Charging Inlet Contactors.";
CM_ SG_ 2566568539 DCContactorInputVoltage "Voltage measured on the inlet side of the DC Charging Inlet Contactors.
If provided, this value should be in agreement with SPN 13172 (EVSE Present DC Charging Voltage).";
CM_ BO_ 2566567263 "EVSE 1 DC Charging Limits 1
Data from the EVCC that reports the maximum charging limits of a DC EVSE.
If this PG is requested, e.g. using RQST, when no EVSE is connected then specific values or states are provided in each parameter.";
CM_ SG_ 2566567263 EVSESupportedEnergyTransferTypes "Energy transfer types supported by the EVSE
0000b = DC-Extended
0001b = DC-Core
0010b - 1100b reserved
1101b = No EVSE connected
1110b = Error
1111b = Data not available
See J2847-2 201504 Sect 4.2.22";
CM_ SG_ 2566567263 EVSEDCChargingPwrMax "EVSE's maximum rated DC output power.
This is communicated to the hybrid vehicle during initial exchange of parameters.
When charging, the smallest value of this and SPN 13157 (Hybrid DC Charging Power Maximum) will be used.
FB00h = Parameter ...";
CM_ SG_ 2566567263 EVSEDCChargingCurMax "EVSE's maximum rated DC output current.
This is communicated to the hybrid vehicle during initial exchange of parameters.
When charging, the smallest value of this and SPN 13156 (Hybrid DC Charging Current Maximum) will be used.
FB00h = Parameter ...";
CM_ SG_ 2566567263 EVSEDCChargingVMax "EVSE's maximum rated DC output voltage.
This is communicated to the hybrid vehicle during initial exchange of parameters.
When charging, the smallest value of this and SPN 13155 (Hybrid DC Charging Voltage Maximum) will be used.
FB00h = Parameter ...";
CM_ BO_ 2566567519 "EVSE 1 DC Charging Limits 2
This message is sent the from EVCC and reports the minimum charging limits and tolerances of a DC EVSE.";
CM_ SG_ 2566567519 EVSECurRegulationTolerance "Regulated current tolerance of the EVSE.
FB00h = Parameter supported, but no tolerance provided by EVSE
See J2847-2 201504 Sect 4.2.38";
CM_ SG_ 2566567519 EVSEPeakCurRipple "Maximum peak to peak ripple current amplitude on the EVSE output.
FB00h = Parameter supported, but no value provided by EVSE
See J2847-2 201504 Sect 4.2.48";
CM_ SG_ 2566567519 EVSEDCChargingCurrentMin "Minimum stable DC output current that can be supplied by the EVSE.
FB00h = Parameter supported, but no value provided by EVSE
See J2847-2 201504 Sect 4.2.45";
CM_ SG_ 2566567519 EVSEDCChargingVoltageMin "Minimum stable DC output voltage that can be supplied by the EVSE.
FB00h = Parameter supported, but no value provided by EVSE
See J2847-2 201504 Sect 4.2.46";
CM_ BO_ 2566568031 "EVSE 1 DC Status 1
This message is sent from the EVCC containing status information receved from the DC EVSE.
If this PG is requested, e.g. using RQST, when no EVSE is connected then specific values or states are provided in each parameter.";
CM_ SG_ 2566568031 EVSEResponseCode "The response code of the EVSE to the last request from the EV.
Typically the values are only significant once current operation progress indicates \"Finished\"
See J2847-2 201504 Sect 4.2.78
0 = OK
1 = OK New Session Established
2 = OK Old ...";
CM_ SG_ 2566568031 EVSEProcessingState "The progress of the EVSE within its current DC Charging State, as reported by SPN 13171.
For example, if the EVSE is doing a cable check SPN 13171 = 9, Cable check and this SP will indicate 01b, Ongoing. On completion of the cable check this SP ...";
CM_ SG_ 2566568031 EVSEIsolationStatus "Isolation Status as returned from this instance of EVSE.
The EVSE checks its internal isolation during the Cable Check phase of establishing the DC connection. On completion of the cable check, the value would change from 14 to one of either 0, 1 ...";
CM_ SG_ 2566568031 EVSEStatus "Status of the DC EVSE as returned from the EVSE
0 = EVSE Not Ready
1 = EVSE Ready
2 = EVSE Shutdown
3 = Utility Interrupt Event
4 = Isolation Monitoring Active
5 = Emergency Shutdown
6 = Malfunction
7 = Reserved
8 = Reserved
9 = Reserved
...";
CM_ SG_ 2566568031 EVSEPowerLimitReached "Indicates if the output power from the EVSE has reached the negotiated power limit as determined by the lower of SPN 13161 (EVSE DC Charging Power Maximum) and SPN 13157 (Hybrid DC Charging Power Maximum).
00b = Not limited or no EVSE connected - ...";
CM_ SG_ 2566568031 EVSECurrentLimitReached "Indicates if the output current from the EVSE has reached the negotiated current limit as determined by SPN 13160 (EVSE DC Charging Current Maximum) and SPN 13156 (Hybrid DC Charging Current Maximum).
00b = Not limited or no EVSE connected - see ...";
CM_ SG_ 2566568031 EVSEVoltageLimitReached "Indicates if the output voltage from the EVSE has reached the negotiated voltage limit as determined by SPN 13159 (EVSE DC Charging Voltage Maximum) and SPN 13155 (Hybrid DC Charging Voltage Maximum).
00b = Not limited or no EVSE connected - see ...";
CM_ SG_ 2566568031 PresentDCChargingCurrent "High Voltage DC current at the output of the EVSE as measured by the EVSE
FB00h = Parameter supported, but no current provided by EVSE
See J2847-2 201504 Sect 4.2.51";
CM_ SG_ 2566568031 PresentDCChargingVoltage "High Voltage DC voltage at the output of the EVSE as measured by the EVSE
FB00h = Parameter supported, but no voltage provided by EVSE
See J2847-2 201504 Sect 4.2.50";
CM_ SG_ 2566568031 ChargingState "Overall State of the DC charging system
0 = Idle. No EVSE connected
1 = Charging
2 = Standby
3 = Reserved
4 = Power Delivery (Start-up)
5 = reserved
6 = Power Delivery (Shutdown)
7 = Welding Check
8 = Charge Parameter Discovery
9 = Cable ...";
CM_ BO_ 2566575711 "EVSE 1 Status 1
This message is sent by the CA that manages the connection to Electric Vehicle Supply Equipment (EVSE).
This PG is related to the physical connection and is generic to all types of EVSE (AC or DC).";
CM_ SG_ 2566575711 EVSEConnectorLockPermission "Indicates whether the connector lock is currently able to be controlled by EVSE1 Connector Lock Request, SPN 12864.
This SP should be used in conjunction with the EVSE1 Connector Lock State, SPN 12863.
Some charging standards mandate that the ...";
CM_ SG_ 2566575711 EVSEConnectorLockState "Indicates the state of this EVSE Connector Lock (if present).
000b = Unlocked
001b = Locked
010b = In transition to/from Locked
011b = Reserved
100b = Reserved
101b = No locking mechanism is available on this vehicle
110b = Error
111b = Not ...";
CM_ SG_ 2566575711 EVSEManualOvrd "Indicates the state of a manual override switch on the vehicle, if present. The switch may be used to disable charging and unlock the the connector.
00b = Manual override not active
01b = Manual override active
10b = Error
11b = Not available";
CM_ SG_ 2566575711 EVSEConnectorReleaseLatch "Indicates the Release Latch status of this EVSE Connector.
J1772 and IEC-61851-1 describes a momentary push-to-break switch (S3) that will be opened when the Release Latch is operated prior to removal of the connector.
00b = Latch released (S3 ...";
CM_ BO_ 2558590815 "Hybrid System Control 1
This messages is sent to the hybrid system to control hybrid related features.";
CM_ SG_ 2558590815 ConnectedEnergySourceType "The type of energy source (EVSE) currently connected as specified in SPN 7890.
This parameter and SPN 7890 shall only be sent by the same controller application.
This parameter shall only be sent if SPN 7890 is also sent.
This parameter is only ...";
CM_ BO_ 2566837855 "Hybrid System Inputs 1
This message can be sent by any controller that has hybrid system related information.";
CM_ SG_ 2566837855 OffBoardChargerConnectionState "Indicates the off-board plug-in charger connection status.  One of the uses of this signal is to protect against vehicle motion while a charger is plugged in.
00b = Off-board charger is not connected
01b = Off-board charger is connected
10b = ...";
CM_ BO_ 2566899039 "CCU_01_5F";
CM_ SG_ 2566899039 CCU01_CRC "8-bit CRC covering the following bytes in this PG.
The CRC is defined as follows:
ï Length: 8 bits
ï Polynomial: x^8+x^5+x^3+x^2+x+1
ï Initial Value: FFh
ï Input Data Reflection: Not reflected
ï Result Data Reflection: Not reflected
ï XOR ...";
CM_ SG_ 2566899039 EVSEChargingPwrMax "EVSE's maximum rated DC output power.
This is communicated to the hybrid vehicle during initial exchange of parameters.
When charging, the smallest value of this and SPN 13157 (Hybrid DC Charging Power Maximum) will be used.
FB00h = Parameter ...";
CM_ SG_ 2566899039 EVSEDischargingPwrMax "EVSE's maximum rated DC output power.
This is communicated to the hybrid vehicle during initial exchange of parameters.
When charging, the smallest value of this and SPN 13157 (Hybrid DC Charging Power Maximum) will be used.
FB00h = Parameter ...";
CM_ SG_ 2566899039 VehIsolationMoningDisCommand "VehicleIsolationMonitoringDisableCommand";
CM_ SG_ 2566899039 ProximityPinResistance "ProximityPinResistance";
CM_ BO_ 2566898779 "CCUC_01_5B";
CM_ SG_ 2566898779 StopChargingRequest "StopChargingRequest";
CM_ SG_ 2566898779 EmergencyStopChargingRequest "EmergencyStopChargingRequest";
CM_ SG_ 2566898779 IsolationMonitorStatusVehicle "IsolationMonitorStatusVehicle";
CM_ SG_ 2566898779 PermitToSleep "PermitToSleep";
CM_ SG_ 2566898779 LED1Command "LED1Command";
CM_ SG_ 2566898779 LED2Command "LED2Command";
CM_ SG_ 2566898779 LED3Command "LED3Command";
CM_ BO_ 2365572954 "eDS_01_5A";
CM_ SG_ 2365572954 ActualMaxAvailableGeneratorCurre "MotorGenerator1InverterDCSideActual";
CM_ SG_ 2365572954 ActualRequiredGeneratorCurrent "MotorGenerator1InverterDCSideActualRequiredGeneratorCurrent";
CM_ SG_ 2365572954 PowertrainCoolantFlowRateReq "PowertrainCoolantFlowRateRequest";
CM_ BO_ 2583632475 "HVS_06_5B";
CM_ SG_ 2583632475 BatteryPotentialPowerInput1 "BatteryPotentialPowerInput1";
CM_ SG_ 2583632475 HVS06_Counter "MessageCounter";
CM_ SG_ 2583632475 HVS06_Checksum "MessageChecksum";
CM_ BO_ 2583633755 "HVS_07_5B";
CM_ SG_ 2583633755 ActualPowerMotorGenerator "ActualPowerMotorGenerator";
CM_ SG_ 2583633755 ActualPowerAuxiliaries "ActualPowerAuxiliaries";
CM_ SG_ 2583633755 ActualPowerePTO "ActualPowerePTO";
CM_ SG_ 2583633755 ActualPowerBrakeResistor "ActualPowerBrakeResistor";
CM_ BO_ 2365573150 "HVJB_05_1E";
CM_ SG_ 2365573150 OnboardChargerContactorState "OnboardChargerContactorState";
CM_ SG_ 2365573150 OnboardChargerPreChargeContactor "OnboardChargerPreChargeContactorState";
CM_ SG_ 2365573150 OnboardChargerContactorErro_0000 "OnboardChargerContactorErrorState";
CM_ SG_ 2365573150 OnboardChargerPreChargeCont_0000 "OnboardChargerPreChargeContactorErrorState";
CM_ SG_ 2365573150 HVJBDischargeCurrentLimit "HVJBDischargeCurrentLimit";
CM_ SG_ 2365573150 HVJBChargeCurrentLimit "HVJBChargeCurrentLimit";
CM_ SG_ 2365573150 HVJBTemperatureState "HVJBTemperatureState";
CM_ SG_ 2365573150 HVJB_05MessageCounter "HVJB_05MessageCounter";
CM_ SG_ 2365573150 HVJB_05MessageChecksum "HVJB_05MessageChecksum";
CM_ BO_ 2566857511 "VECU_18_27";
CM_ SG_ 2566857511 VehicleHVEnableRequest "VehicleHVEnableRequest";
CM_ SG_ 2566857511 ePTOHVActivationRequest "ePTOHVActivationRequest";
CM_ SG_ 2566857511 CabACCompressorEnableRequest "CabACCompressorEnableRequest";
CM_ SG_ 2566857511 LowVoltageBatteryChargeRequest "LowVoltageBatteryChargeRequest";
CM_ SG_ 2566857511 StopChargingSwitchStatus "StopChargingSwitchStatus";
CM_ SG_ 2566857511 CabinDoorLockStatus "CabinDoorLockStatus";
CM_ SG_ 2566857511 CabinHeaterEnableCommand "CabinHeaterEnableCommand";
CM_ SG_ 2566857511 BackofficeStopChargingDemand "BackofficeStopChargingDemand";
CM_ SG_ 2566857511 BackofficeChargingMethodSetting "BackofficeChargingMethodSetting";
CM_ SG_ 2566857511 BackofficeHighVoltageBattCalibra "BackofficeHighVoltageBatteryCalibrationDemand";
CM_ SG_ 2566857511 BackofficeChargingSOCSetting "BackofficeChargingSOCSetting";
CM_ SG_ 2566857511 CabHtrCoolantTempReq "CabinHeaterCoolantTemperatureRequest";
CM_ SG_ 2566857511 CabACCompressorSpeedRequest "CabACCompressorSpeedRequest";
CM_ BO_ 2565942823 "DC/AC Accessory Inverter 5 Command
Used to command this instance of an DC/AC Accessory Inverter that uses a V/Hz algorithm.  The Inverter may have multiple outputs to power accessories on a vehicle (e.g. HVAC compressor, air compressor, power ...";
CM_ SG_ 2565942823 EPTO_ACSideMotorStartingRMSVReq "Signal to the DC/AC Accessory Inverter indicating the requested AC side RMS voltage for starting the attached accessory motor.   In a V/Hz variable speed motor control application, this voltage typically may be set to a non-zero value when an ...";
CM_ SG_ 2565942823 EPTO_OperationalCommand "Command to the DC/AC Accessory Inverter to enable this output.  Each output may control multiple devices (e.g. electric motors) if they all operate at the same frequency.
00b = Disable DC/AC Accessory Inverter Output
01b = Enable DC/AC Accessory ...";
CM_ SG_ 2565942823 EPTO_Status2 "Signal to the DC/AC Accessory Inverter indicating the state of the device attached to the inverter output.  Each output may control multiple devices (e.g. electric motors) if they all operate at the same frequency.
The Faulted Off state will be ...";
CM_ SG_ 2565942823 EPTO_Status1 "Signal to the DC/AC Accessory Inverter indicating the state of the device attached to the inverter output.  Each output may control multiple devices (e.g. electric motors) if they all operate at the same frequency.
The Faulted Off state will be ...";
CM_ SG_ 2565942823 EPTO_FrequencyCommand "Command to the DC/AC Accessory Inverter indicating the Inverter frequency desired for the device(s) attached to the inverter output.  Each output may control multiple devices (e.g. electric motors) if they all operate at the same frequency.";
CM_ SG_ 2565942823 EPTO_FreqRateOfChangeLmt "Signal to the DC/AC Accessory Inverter indicating the frequency rate of change limit of the device(s) attached to the inverter output (Note: Increasing and decreasing rates can be controlled by the same signal).  Each output may control multiple ...";
CM_ SG_ 2565942823 EPTO_RatedRMSVoltage "Signal to the DC/AC Accessory Inverter indicating the rated RMS voltage of the device(s) attached to the inverter output.   Each output may control multiple devices (e.g. electric motors) if they all operate at the same frequency.";
CM_ SG_ 2565942823 EPTO_RatedFrequency "Signal to the DC/AC Accessory Inverter indicating the rated frequency of the device(s) attached to the inverter output.  Each output may control multiple devices (e.g. electric motors) if they all operate at the same frequency.";
CM_ SG_ 2565942823 EPTO_MinFrequency "Signal to the DC/AC Accessory Inverter indicating the minimum frequency of the device(s) attached to the inverter output.  Each output may control multiple devices (e.g. electric motors) if they all operate at the same frequency.";
CM_ SG_ 2565942823 EPTO_MaxFrequency "Signal to the DC/AC Accessory Inverter indicating the maximum frequency of the devices(s) attached to the inverter output.  Each output may control multiple devices (e.g. electric motors) if they all operate at the same frequency.";
CM_ BO_ 2365304574 "DC/AC Accessory Inverter 5 DC Side Limits
Sets the HVES or High Voltage system limits for the transfer of energy between the high voltage system (i.e. DC side) and the accessory loads (i.e. AC side) in a hybrid or electric vehicle.";
CM_ SG_ 2365304574 EPTO_CurrentMinLimitReq "The minimum allowed DC Side input current requested by a separate device.   Under normal conditions this requested limit would be reflected in SPN 9556.";
CM_ SG_ 2365304574 EPTO_VoltageMaxLimitReq "The maximum allowed DC Side input voltage requested by a separate device.   Under normal conditions this requested limit would be reflected in SPN 9555.";
CM_ SG_ 2365304574 EPTO_CurrentMaxLimitReq "The maximum allowed DC Side input current requested by a separate device.   Under normal conditions this requested limit would be reflected in SPN 9362.";
CM_ SG_ 2365304574 EPTO_VoltageMinLimitReq "The minimum allowed DC Side input voltage requested by a separate device.   Under normal conditions this requested limit would be reflected in SPN 9361.";
CM_ BO_ 2566865178 "PropB_DCDC : It transmits low side voltage, low side current, high side voltage and high side current. All the units, disregarding the type of it, transmit one actual message.";
CM_ SG_ 2566865178 DCDC_LVVoltage "SPN:520092 VVR:[0,64255]
Measured low side voltage.";
CM_ SG_ 2566865178 DCDC_LVCurrent "SPN:520091
Measured low side current.";
CM_ SG_ 2566865178 DCDC_HVVoltage "SPN:520090 VVR:[0,64255]
Measured high side voltage.";
CM_ SG_ 2566865178 DCDC_HVCurrent "SPN:520089
Measured High side current.";
CM_ BO_ 2365573467 "HVS_04_5B";
CM_ SG_ 2365573467 HVESSModeRequest "HVESSModeRequest";
CM_ SG_ 2365573467 HVESSStopPreconditioningRequest "HVESSStopPreconditioningRequest";
BA_DEF_ BO_  "Bus" STRING ;
BA_DEF_ BO_  "GenMsgCycleTime" INT 0 3600000;
BA_DEF_ BO_  "GenMsgDbName" STRING ;
BA_DEF_ BO_  "GenMsgDelayTime" INT 0 1000;
BA_DEF_ BO_  "GenMsgDescription" STRING ;
BA_DEF_ BO_  "GenMsgILSupport" ENUM  "No","Yes";
BA_DEF_ BO_  "GenMsgRequestable" INT 0 1;
BA_DEF_ BO_  "GenMsgSendType" ENUM  "NoMsgSendType","Cyclic","CyclicOnChange","OnWrite","cyclic","noMsgSendType","Triggered";
BA_DEF_ BO_  "J1939PgAppearanceOnBus" ENUM  "Default","CAN_Extended","CANFD_Extended";
BA_DEF_ BO_  "MsgType" ENUM  "Application","NM ","NMH","TP2.0","ISO-TP ","BAP","EID","KS";
BA_DEF_ BO_  "VFrameFormat" ENUM  "StandardCAN","ExtendedCAN","reserved","J1939PG";
BA_DEF_ SG_  "GenSigDbName" STRING ;
BA_DEF_ SG_  "GenSigDescription" STRING ;
BA_DEF_ SG_  "GenSigEVName" STRING ;
BA_DEF_ SG_  "GenSigILSupport" ENUM  "No","Yes";
BA_DEF_ SG_  "GenSigSendType" ENUM  "Cyclic","OnWrite","reserved","OnChange","reserved","reserved","reserved","NoSigSendType";
BA_DEF_ SG_  "GenSigStartValue" INT 0 10000;
BA_DEF_ SG_  "SPN" INT 0 1000000;
BA_DEF_ SG_  "SigType" ENUM  "Default","Range","RangeSigned","ASCII","Discrete","Control","ReferencePGN","DTC","StringDelimiter","StringLength","StringLengthControl","MessageCounter","MessageChecksum";
BA_DEF_ SG_  "SystemSignalLongSymbol" STRING ;
BA_DEF_DEF_  "Bus" "HCAN";
BA_DEF_DEF_  "GenMsgCycleTime" 0;
BA_DEF_DEF_  "GenMsgDbName" "";
BA_DEF_DEF_  "GenMsgDelayTime" 0;
BA_DEF_DEF_  "GenMsgDescription" "";
BA_DEF_DEF_  "GenMsgILSupport" "Yes";
BA_DEF_DEF_  "GenMsgRequestable" 1;
BA_DEF_DEF_  "GenMsgSendType" "";
BA_DEF_DEF_  "J1939PgAppearanceOnBus" "Default";
BA_DEF_DEF_  "MsgType" "Application";
BA_DEF_DEF_  "VFrameFormat" "J1939PG";
BA_DEF_DEF_  "GenSigDbName" "";
BA_DEF_DEF_  "GenSigDescription" "";
BA_DEF_DEF_  "GenSigEVName" "Env@Nodename_@Signame";
BA_DEF_DEF_  "GenSigILSupport" "Yes";
BA_DEF_DEF_  "GenSigSendType" "NoSigSendType";
BA_DEF_DEF_  "GenSigStartValue" 0;
BA_DEF_DEF_  "SPN" 0;
BA_DEF_DEF_  "SigType" "Default";
BA_DEF_DEF_  "SystemSignalLongSymbol" "";
BA_ "GenMsgCycleTime" BO_ 2566613851 1000;
BA_ "GenMsgDelayTime" BO_ 2566613851 30;
BA_ "GenMsgRequestable" BO_ 2566613851 0;
BA_ "GenMsgSendType" BO_ 2566613851 2;
BA_ "GenMsgCycleTime" BO_ 2566658651 100;
BA_ "GenMsgDelayTime" BO_ 2566658651 19;
BA_ "GenMsgRequestable" BO_ 2566658651 0;
BA_ "GenMsgSendType" BO_ 2566658651 1;
BA_ "GenMsgCycleTime" BO_ 2566675956 5000;
BA_ "GenMsgDbName" BO_ 2566675956 "HVESSCFG";
BA_ "GenMsgDescription" BO_ 2566675956 "High Voltage Energy Storage System Configuration : Configuration data for High Voltage Energy Storage System ";
BA_ "GenMsgSendType" BO_ 2566675956 1;
BA_ "GenMsgCycleTime" BO_ 2566722907 1000;
BA_ "GenMsgDelayTime" BO_ 2566722907 110;
BA_ "GenMsgRequestable" BO_ 2566722907 0;
BA_ "GenMsgSendType" BO_ 2566722907 1;
BA_ "GenMsgCycleTime" BO_ 2566771751 10000;
BA_ "GenMsgDelayTime" BO_ 2566771751 122;
BA_ "GenMsgRequestable" BO_ 2566771751 0;
BA_ "GenMsgSendType" BO_ 2566771751 2;
BA_ "GenMsgCycleTime" BO_ 2566827568 1000;
BA_ "GenMsgDelayTime" BO_ 2566827568 77;
BA_ "GenMsgRequestable" BO_ 2566827568 0;
BA_ "GenMsgSendType" BO_ 2566827568 1;
BA_ "GenMsgCycleTime" BO_ 2566832423 1000;
BA_ "GenMsgRequestable" BO_ 2566832423 0;
BA_ "GenMsgSendType" BO_ 2566832423 1;
BA_ "GenMsgCycleTime" BO_ 2566832622 1000;
BA_ "GenMsgDelayTime" BO_ 2566832622 27;
BA_ "GenMsgRequestable" BO_ 2566832622 0;
BA_ "GenMsgSendType" BO_ 2566832622 1;
BA_ "GenMsgCycleTime" BO_ 2566840154 250;
BA_ "GenMsgDelayTime" BO_ 2566840154 45;
BA_ "GenMsgRequestable" BO_ 2566840154 0;
BA_ "GenMsgSendType" BO_ 2566840154 1;
BA_ "GenMsgCycleTime" BO_ 2566840666 5000;
BA_ "GenMsgDbName" BO_ 2566840666 "RC_DR_EST";
BA_ "GenMsgDelayTime" BO_ 2566840666 120;
BA_ "GenMsgDescription" BO_ 2566840666 "This map describes the stationary behavior of the retarder.Note:";
BA_ "GenMsgRequestable" BO_ 2566840666 0;
BA_ "GenMsgSendType" BO_ 2566840666 1;
BA_ "GenMsgCycleTime" BO_ 2566841895 1000;
BA_ "GenMsgRequestable" BO_ 2566841895 0;
BA_ "GenMsgSendType" BO_ 2566841895 1;
BA_ "GenMsgCycleTime" BO_ 2566842094 1000;
BA_ "GenMsgDelayTime" BO_ 2566842094 43;
BA_ "GenMsgRequestable" BO_ 2566842094 0;
BA_ "GenMsgSendType" BO_ 2566842094 1;
BA_ "GenMsgCycleTime" BO_ 2566845696 1000;
BA_ "GenMsgDelayTime" BO_ 2566845696 10;
BA_ "GenMsgRequestable" BO_ 2566845696 0;
BA_ "GenMsgSendType" BO_ 2566845696 1;
BA_ "GenMsgCycleTime" BO_ 2566803211 100;
BA_ "GenMsgDelayTime" BO_ 2566803211 28;
BA_ "GenMsgRequestable" BO_ 2566803211 0;
BA_ "GenMsgSendType" BO_ 2566803211 1;
BA_ "GenMsgCycleTime" BO_ 2565867787 100;
BA_ "GenMsgDelayTime" BO_ 2565867787 23;
BA_ "GenMsgRequestable" BO_ 2565867787 0;
BA_ "GenMsgSendType" BO_ 2565867787 1;
BA_ "GenMsgCycleTime" BO_ 2566878532 1000;
BA_ "GenMsgDelayTime" BO_ 2566878532 86;
BA_ "GenMsgRequestable" BO_ 2566878532 0;
BA_ "GenMsgSendType" BO_ 2566878532 1;
BA_ "GenMsgCycleTime" BO_ 2633727015 100;
BA_ "GenMsgDelayTime" BO_ 2633727015 11;
BA_ "GenMsgRequestable" BO_ 2633727015 0;
BA_ "GenMsgSendType" BO_ 2633727015 1;
BA_ "GenMsgCycleTime" BO_ 2633727067 100;
BA_ "GenMsgDelayTime" BO_ 2633727067 20;
BA_ "GenMsgRequestable" BO_ 2633727067 0;
BA_ "GenMsgSendType" BO_ 2633727067 1;
BA_ "GenMsgCycleTime" BO_ 2633727220 100;
BA_ "GenMsgSendType" BO_ 2633727220 1;
BA_ "GenMsgSendType" BO_ 2566549595 0;
BA_ "GenMsgSendType" BO_ 2566549851 0;
BA_ "GenMsgSendType" BO_ 2566569307 0;
BA_ "GenMsgCycleTime" BO_ 2365557851 100;
BA_ "GenMsgDelayTime" BO_ 2365557851 19;
BA_ "GenMsgRequestable" BO_ 2365557851 0;
BA_ "GenMsgSendType" BO_ 2365557851 1;
BA_ "GenMsgCycleTime" BO_ 2583630375 1000;
BA_ "GenMsgRequestable" BO_ 2583630375 0;
BA_ "GenMsgSendType" BO_ 2583630375 3;
BA_ "GenMsgCycleTime" BO_ 2556952103 1000;
BA_ "GenMsgSendType" BO_ 2556952103 1;
BA_ "GenMsgCycleTime" BO_ 2365558046 100;
BA_ "GenMsgDelayTime" BO_ 2365558046 45;
BA_ "GenMsgRequestable" BO_ 2365558046 0;
BA_ "GenMsgSendType" BO_ 2365558046 2;
BA_ "GenMsgCycleTime" BO_ 2365558302 100;
BA_ "GenMsgDelayTime" BO_ 2365558302 28;
BA_ "GenMsgRequestable" BO_ 2365558302 0;
BA_ "GenMsgSendType" BO_ 2365558302 1;
BA_ "GenMsgCycleTime" BO_ 2365558558 100;
BA_ "GenMsgDelayTime" BO_ 2365558558 35;
BA_ "GenMsgRequestable" BO_ 2365558558 0;
BA_ "GenMsgSendType" BO_ 2365558558 1;
BA_ "GenMsgCycleTime" BO_ 2365571870 1000;
BA_ "GenMsgDelayTime" BO_ 2365571870 54;
BA_ "GenMsgRequestable" BO_ 2365571870 0;
BA_ "GenMsgSendType" BO_ 2365571870 2;
BA_ "GenMsgCycleTime" BO_ 2566613790 1000;
BA_ "GenMsgDelayTime" BO_ 2566613790 30;
BA_ "GenMsgRequestable" BO_ 2566613790 0;
BA_ "GenMsgSendType" BO_ 2566613790 2;
BA_ "GenMsgCycleTime" BO_ 2364607476 100;
BA_ "GenMsgSendType" BO_ 2364607476 4;
BA_ "GenMsgCycleTime" BO_ 2583632219 1000;
BA_ "GenMsgSendType" BO_ 2583632219 5;
BA_ "GenMsgCycleTime" BO_ 2583631911 1000;
BA_ "GenMsgSendType" BO_ 2583631911 5;
BA_ "GenMsgCycleTime" BO_ 2566810971 1000;
BA_ "GenMsgSendType" BO_ 2566810971 5;
BA_ "GenMsgCycleTime" BO_ 2583631655 5000;
BA_ "GenMsgSendType" BO_ 2583631655 5;
BA_ "GenMsgCycleTime" BO_ 2583629847 1000;
BA_ "GenMsgSendType" BO_ 2583629847 5;
BA_ "GenMsgCycleTime" BO_ 2583631604 1000;
BA_ "GenMsgSendType" BO_ 2583631604 5;
BA_ "GenMsgCycleTime" BO_ 2566889563 5000;
BA_ "GenMsgSendType" BO_ 2566889563 5;
BA_ "GenMsgCycleTime" BO_ 2566890587 100;
BA_ "GenMsgSendType" BO_ 2566890587 5;
BA_ "GenMsgCycleTime" BO_ 2364577115 1000;
BA_ "GenMsgSendType" BO_ 2364577115 5;
BA_ "GenMsgCycleTime" BO_ 2566775131 1000;
BA_ "GenMsgSendType" BO_ 2566775131 5;
BA_ "GenMsgCycleTime" BO_ 2566573919 100;
BA_ "GenMsgSendType" BO_ 2566573919 1;
BA_ "GenMsgCycleTime" BO_ 2566567003 1000;
BA_ "GenMsgSendType" BO_ 2566567003 4;
BA_ "GenMsgCycleTime" BO_ 2566544219 1000;
BA_ "GenMsgSendType" BO_ 2566544219 4;
BA_ "GenMsgCycleTime" BO_ 2566567771 20;
BA_ "GenMsgSendType" BO_ 2566567771 4;
BA_ "GenMsgCycleTime" BO_ 2566575455 100;
BA_ "GenMsgDelayTime" BO_ 2566575455 10;
BA_ "GenMsgSendType" BO_ 2566575455 4;
BA_ "GenMsgCycleTime" BO_ 2555600731 100;
BA_ "GenMsgSendType" BO_ 2555600731 4;
BA_ "GenMsgCycleTime" BO_ 2566568287 1000;
BA_ "GenMsgSendType" BO_ 2566568287 4;
BA_ "GenMsgCycleTime" BO_ 2566568539 100;
BA_ "GenMsgSendType" BO_ 2566568539 4;
BA_ "GenMsgCycleTime" BO_ 2566567263 1000;
BA_ "GenMsgDelayTime" BO_ 2566567263 100;
BA_ "GenMsgSendType" BO_ 2566567263 4;
BA_ "GenMsgCycleTime" BO_ 2566567519 100;
BA_ "GenMsgSendType" BO_ 2566567519 1;
BA_ "GenMsgCycleTime" BO_ 2566568031 1000;
BA_ "GenMsgSendType" BO_ 2566568031 4;
BA_ "GenMsgCycleTime" BO_ 2566575711 1000;
BA_ "GenMsgSendType" BO_ 2566575711 4;
BA_ "GenMsgCycleTime" BO_ 2558590815 1000;
BA_ "GenMsgDelayTime" BO_ 2558590815 100;
BA_ "GenMsgSendType" BO_ 2558590815 4;
BA_ "GenMsgCycleTime" BO_ 2566837855 1000;
BA_ "GenMsgSendType" BO_ 2566837855 4;
BA_ "GenMsgCycleTime" BO_ 2566899039 100;
BA_ "GenMsgSendType" BO_ 2566899039 5;
BA_ "GenMsgCycleTime" BO_ 2566898779 100;
BA_ "GenMsgSendType" BO_ 2566898779 5;
BA_ "GenMsgCycleTime" BO_ 2365572954 100;
BA_ "GenMsgSendType" BO_ 2365572954 5;
BA_ "GenMsgCycleTime" BO_ 2583632475 1000;
BA_ "GenMsgSendType" BO_ 2583632475 5;
BA_ "GenMsgCycleTime" BO_ 2583633755 100;
BA_ "GenMsgSendType" BO_ 2583633755 5;
BA_ "GenMsgCycleTime" BO_ 2365573150 100;
BA_ "GenMsgSendType" BO_ 2365573150 5;
BA_ "GenMsgCycleTime" BO_ 2566857511 100;
BA_ "GenMsgSendType" BO_ 2566857511 5;
BA_ "GenMsgCycleTime" BO_ 2565942823 100;
BA_ "GenMsgSendType" BO_ 2565942823 0;
BA_ "GenMsgCycleTime" BO_ 2365304574 1000;
BA_ "GenMsgSendType" BO_ 2365304574 4;
BA_ "Bus" BO_ 2566865178 "HVCAN";
BA_ "GenMsgCycleTime" BO_ 2566865178 100;
BA_ "GenMsgDelayTime" BO_ 2566865178 6;
BA_ "GenMsgRequestable" BO_ 2566865178 0;
BA_ "GenMsgSendType" BO_ 2566865178 6;
BA_ "GenMsgCycleTime" BO_ 2365573467 1000;
BA_ "GenMsgSendType" BO_ 2365573467 5;
BA_ "SPN" SG_ 2566613851 HVDCBusAvailability 10298;
BA_ "SPN" SG_ 2566613851 HVBusDrivelineAvailability 20802;
BA_ "SPN" SG_ 2566613851 HVBusAuxiliariesAvailability 20803;
BA_ "SPN" SG_ 2566613851 HVBusePTOAvailability 20804;
BA_ "SPN" SG_ 2566613851 HVBusOnboardChargerAvailability 20805;
BA_ "SPN" SG_ 2566613851 HVBusOffBoardChargerAvailability 20806;
BA_ "SPN" SG_ 2566658651 HVESSThermalManagementSystemHtrE 20457;
BA_ "SPN" SG_ 2566675956 HVESSNominalVoltage 8115;
BA_ "SigType" SG_ 2566675956 HVESSNominalVoltage 1;
BA_ "GenSigDbName" SG_ 2566675956 HVESSRecommendedMinOperatingVolt "HVESS Recommended Minimum Operating Voltage";
BA_ "GenSigDescription" SG_ 2566675956 HVESSRecommendedMinOperatingVolt "Per the HVES manufacturer, this is the minimum recommended voltage level for High Voltage Energy Storage System ";
BA_ "SPN" SG_ 2566675956 HVESSRecommendedMinOperatingVolt 8116;
BA_ "SigType" SG_ 2566675956 HVESSRecommendedMinOperatingVolt 1;
BA_ "GenSigDbName" SG_ 2566675956 HVESSRecommendedMaxOperatingVolt "HVESS Recommended Maximum Operating Voltage";
BA_ "GenSigDescription" SG_ 2566675956 HVESSRecommendedMaxOperatingVolt "Per the HVES manufacturer, this is the maximum recommended voltage level for High Voltage Energy Storage System ";
BA_ "SPN" SG_ 2566675956 HVESSRecommendedMaxOperatingVolt 8117;
BA_ "SigType" SG_ 2566675956 HVESSRecommendedMaxOperatingVolt 1;
BA_ "SigType" SG_ 2566675956 HVESSRecommendedMinStateOfCharge 1;
BA_ "SigType" SG_ 2566675956 HVESSRecommendedMaxStateOfCharge 1;
BA_ "SPN" SG_ 2566675956 HVESSRecommendedMaxOperatingTemp 8117;
BA_ "SigType" SG_ 2566675956 HVESSRecommendedMaxOperatingTemp 1;
BA_ "SPN" SG_ 2566675956 HVESSRecommendedMinOperatingTemp 8116;
BA_ "SigType" SG_ 2566675956 HVESSRecommendedMinOperatingTemp 1;
BA_ "SPN" SG_ 2566675956 HVESSCellMaximumVoltageLimit 8209;
BA_ "SigType" SG_ 2566675956 HVESSCellMaximumVoltageLimit 1;
BA_ "SPN" SG_ 2566675956 HVESSCellMinimumVoltageLimit 8210;
BA_ "SigType" SG_ 2566675956 HVESSCellMinimumVoltageLimit 1;
BA_ "SPN" SG_ 2566675956 HVESSNumberofHVESPsConfigured 12904;
BA_ "SigType" SG_ 2566675956 HVESSNominalRatedCapacity 1;
BA_ "SPN" SG_ 2566722907 BatteryCharger1State 4990;
BA_ "SPN" SG_ 2566722907 BatteryCharger1PowerLineState 4991;
BA_ "SPN" SG_ 2566722907 BatteryCharger1OutputVoltage 4992;
BA_ "SigType" SG_ 2566722907 BatteryCharger1OutputVoltage 1;
BA_ "GenSigStartValue" SG_ 2566722907 BatteryCharger1OutputCurrent 10000;
BA_ "SPN" SG_ 2566722907 BatteryCharger1OutputCurrent 4993;
BA_ "SigType" SG_ 2566722907 BatteryCharger1OutputCurrent 1;
BA_ "SPN" SG_ 2566771751 OperatorKeySwitchIgnitionPower 10145;
BA_ "SPN" SG_ 2566827568 ServiceBrakeCircuit1AirPressure 1087;
BA_ "SigType" SG_ 2566827568 ServiceBrakeCircuit1AirPressure 1;
BA_ "SPN" SG_ 2566827568 ServiceBrakeCircuit2AirPressure 1088;
BA_ "SigType" SG_ 2566827568 ServiceBrakeCircuit2AirPressure 1;
BA_ "SPN" SG_ 2566827568 AirCompressorStatus 1351;
BA_ "SPN" SG_ 2566832622 TotalVehicleDistHighResolution 917;
BA_ "GenSigStartValue" SG_ 2566840154 NominalFrictionPercentTorque 125;
BA_ "SPN" SG_ 2566840154 NominalFrictionPercentTorque 514;
BA_ "SigType" SG_ 2566840154 NominalFrictionPercentTorque 1;
BA_ "GenSigDbName" SG_ 2566840666 RetarderReferenceTorque "Retarder Reference Torque";
BA_ "GenSigDescription" SG_ 2566840666 RetarderReferenceTorque "This parameter is the 100% reference value for all defined indicated retarder torque parameters.  ";
BA_ "SPN" SG_ 2566840666 RetarderReferenceTorque 556;
BA_ "GenSigDbName" SG_ 2566840666 RetarderType "Retarder Type";
BA_ "GenSigDescription" SG_ 2566840666 RetarderType "A vehicle retarder is a supplementary device to the wheel brakes for the driver to better control the vehicle.  ";
BA_ "SPN" SG_ 2566840666 RetarderType 901;
BA_ "GenSigDbName" SG_ 2566840666 RetarderLocation "Retarder Location";
BA_ "GenSigDescription" SG_ 2566840666 RetarderLocation "This parameter defines whether the torque/speed curve defined by the retarder configuration message (PGN 65249)";
BA_ "SPN" SG_ 2566840666 RetarderLocation 902;
BA_ "GenSigDbName" SG_ 2566840666 RetarderControlMethod "Retarder Control Method";
BA_ "GenSigDescription" SG_ 2566840666 RetarderControlMethod "This parameter identifies the number of steps used by the retarder.";
BA_ "SPN" SG_ 2566840666 RetarderControlMethod 557;
BA_ "GenSigDbName" SG_ 2566840666 RetarderPercentTorqueAtIdlePnt1 "Retarder Percent Torque At Idle, Point 1";
BA_ "GenSigDescription" SG_ 2566840666 RetarderPercentTorqueAtIdlePnt1 "The torque limit that indicates the available retarder torque which can be provided by the retarder at idle speed.";
BA_ "GenSigStartValue" SG_ 2566840666 RetarderPercentTorqueAtIdlePnt1 125;
BA_ "SPN" SG_ 2566840666 RetarderPercentTorqueAtIdlePnt1 551;
BA_ "SigType" SG_ 2566840666 RetarderPercentTorqueAtIdlePnt1 1;
BA_ "GenSigDbName" SG_ 2566840666 RetarderPctTorqueAtMaxSpeedPnt2 "Retarder Percent Torque At Maximum Speed, Point 2";
BA_ "GenSigDescription" SG_ 2566840666 RetarderPctTorqueAtMaxSpeedPnt2 "The torque limit that indicates the available retarder torque which can be provided by the retarder at its maximum speed.";
BA_ "GenSigStartValue" SG_ 2566840666 RetarderPctTorqueAtMaxSpeedPnt2 125;
BA_ "SPN" SG_ 2566840666 RetarderPctTorqueAtMaxSpeedPnt2 552;
BA_ "SigType" SG_ 2566840666 RetarderPctTorqueAtMaxSpeedPnt2 1;
BA_ "GenSigDbName" SG_ 2566840666 RetarderPercentTorqueAtPoint3 "Retarder Percent Torque At Point 3";
BA_ "GenSigDescription" SG_ 2566840666 RetarderPercentTorqueAtPoint3 "The torque limit that indicates the available retarder torque which can be provided by the retarder at points 3 and 4";
BA_ "GenSigStartValue" SG_ 2566840666 RetarderPercentTorqueAtPoint3 125;
BA_ "SPN" SG_ 2566840666 RetarderPercentTorqueAtPoint3 553;
BA_ "SigType" SG_ 2566840666 RetarderPercentTorqueAtPoint3 1;
BA_ "GenSigDbName" SG_ 2566840666 RetarderPercentTorqueAtPoint4 "Retarder Percent Torque At Point 4";
BA_ "GenSigDescription" SG_ 2566840666 RetarderPercentTorqueAtPoint4 "The torque limit that indicates the available retarder torque which can be provided by the retarder at points 3 and 4";
BA_ "GenSigStartValue" SG_ 2566840666 RetarderPercentTorqueAtPoint4 125;
BA_ "SPN" SG_ 2566840666 RetarderPercentTorqueAtPoint4 554;
BA_ "SigType" SG_ 2566840666 RetarderPercentTorqueAtPoint4 1;
BA_ "GenSigDbName" SG_ 2566840666 RetPctTorqueAtPeakTorquePnt5 "Retarder Percent Torque At Peak Torque, Point 5";
BA_ "GenSigDescription" SG_ 2566840666 RetPctTorqueAtPeakTorquePnt5 "The torque limit that indicates the available retarder torque which can be provided by the retarder at point 5";
BA_ "GenSigStartValue" SG_ 2566840666 RetPctTorqueAtPeakTorquePnt5 125;
BA_ "SPN" SG_ 2566840666 RetPctTorqueAtPeakTorquePnt5 555;
BA_ "SigType" SG_ 2566840666 RetPctTorqueAtPeakTorquePnt5 1;
BA_ "SPN" SG_ 2566842094 Seconds 959;
BA_ "SigType" SG_ 2566842094 Seconds 1;
BA_ "SPN" SG_ 2566842094 Minutes 960;
BA_ "SPN" SG_ 2566842094 Hours 961;
BA_ "SPN" SG_ 2566842094 Month 963;
BA_ "SPN" SG_ 2566842094 Day 962;
BA_ "SigType" SG_ 2566842094 Day 1;
BA_ "SPN" SG_ 2566842094 Year 964;
BA_ "SPN" SG_ 2566845696 BarometricPressure 108;
BA_ "SigType" SG_ 2566845696 BarometricPressure 1;
BA_ "GenSigStartValue" SG_ 2566845696 AmbientAirTemperature 8736;
BA_ "SPN" SG_ 2566845696 AmbientAirTemperature 171;
BA_ "SigType" SG_ 2566845696 AmbientAirTemperature 1;
BA_ "SPN" SG_ 2566803211 VDCbrakelightrequest 1815;
BA_ "SPN" SG_ 2566803211 ROPEngineControlactive 1816;
BA_ "SPN" SG_ 2566803211 ROPBrakeControlactive 1818;
BA_ "SPN" SG_ 2566803211 YCEngineControlactive 1817;
BA_ "SPN" SG_ 2566803211 YCBrakeControlactive 1819;
BA_ "GenSigStartValue" SG_ 2565867787 SteeringWheelAngle 10000;
BA_ "SPN" SG_ 2565867787 SteeringWheelAngle 1807;
BA_ "SigType" SG_ 2565867787 SteeringWheelAngle 1;
BA_ "GenSigStartValue" SG_ 2565867787 SteeringWheelTurnCounter 32;
BA_ "SPN" SG_ 2565867787 SteeringWheelTurnCounter 1811;
BA_ "GenSigStartValue" SG_ 2565867787 LongitudinalAcceleration 125;
BA_ "SPN" SG_ 2565867787 LongitudinalAcceleration 1810;
BA_ "SigType" SG_ 2565867787 LongitudinalAcceleration 1;
BA_ "SPN" SG_ 2566878532 CabinHeaterStatus 521903;
BA_ "SPN" SG_ 2566878532 CabinHeaterHVILStatus 521905;
BA_ "GenSigStartValue" SG_ 2566878532 CabinHtrOutputCoolantTemperature 40;
BA_ "SPN" SG_ 2566878532 CabinHtrOutputCoolantTemperature 521904;
BA_ "SPN" SG_ 2566878532 CabinHeaterCurrent 521906;
BA_ "SigType" SG_ 2566878532 CabinHeaterCurrent 1;
BA_ "SPN" SG_ 2566878532 CabinHeaterVoltage 521907;
BA_ "SigType" SG_ 2566878532 CabinHeaterVoltage 1;
BA_ "SPN" SG_ 2566878532 CabinHeaterInternalCurrentLimit 521908;
BA_ "SigType" SG_ 2566878532 CabinHeaterInternalCurrentLimit 1;
BA_ "SPN" SG_ 2633727015 ControlBitVector 8623;
BA_ "SPN" SG_ 2633727067 ControlBitVector 8623;
BA_ "SPN" SG_ 2566549595 PwrConv1TotalChargeGenerated 20610;
BA_ "SigType" SG_ 2566549595 PwrConv1TotalChargeGenerated 1;
BA_ "SPN" SG_ 2566549595 PwrConv1TotalChargeConsumed 20609;
BA_ "SigType" SG_ 2566549595 PwrConv1TotalChargeConsumed 1;
BA_ "SPN" SG_ 2566549595 PwrConv1TotalEnergyGenerated 20608;
BA_ "SigType" SG_ 2566549595 PwrConv1TotalEnergyGenerated 1;
BA_ "SPN" SG_ 2566549595 PwrConv1TotalEnergyConsumed 20607;
BA_ "SigType" SG_ 2566549595 PwrConv1TotalEnergyConsumed 1;
BA_ "SPN" SG_ 2566549851 PwrConv2TotalChargeGenerated 20614;
BA_ "SigType" SG_ 2566549851 PwrConv2TotalChargeGenerated 1;
BA_ "SPN" SG_ 2566549851 PwrConv2TotalChargeConsumed 20613;
BA_ "SigType" SG_ 2566549851 PwrConv2TotalChargeConsumed 1;
BA_ "SPN" SG_ 2566549851 PwrConv2TotalEnergyGenerated 20612;
BA_ "SigType" SG_ 2566549851 PwrConv2TotalEnergyGenerated 1;
BA_ "SPN" SG_ 2566549851 PwrConv2TotalEnergyConsumed 20611;
BA_ "SigType" SG_ 2566549851 PwrConv2TotalEnergyConsumed 1;
BA_ "SPN" SG_ 2566569307 MG1_TotalChargeGenerated 13084;
BA_ "SigType" SG_ 2566569307 MG1_TotalChargeGenerated 1;
BA_ "SPN" SG_ 2566569307 MG1_TotalChargeConsumed 13083;
BA_ "SigType" SG_ 2566569307 MG1_TotalChargeConsumed 1;
BA_ "SPN" SG_ 2566569307 MG1_TotalEnergyGenerated 13082;
BA_ "SigType" SG_ 2566569307 MG1_TotalEnergyGenerated 1;
BA_ "SPN" SG_ 2566569307 MG1_TotalEnergyConsumed 13081;
BA_ "SigType" SG_ 2566569307 MG1_TotalEnergyConsumed 1;
BA_ "SPN" SG_ 2365557851 DriveContactorCommand 521910;
BA_ "SPN" SG_ 2365557851 DriveContactorPowerDownCommand 520064;
BA_ "SPN" SG_ 2365557851 AuxiliaryContactorCommand 521914;
BA_ "SPN" SG_ 2365557851 AuxiliaryContactorPowerDownCmd 520065;
BA_ "SPN" SG_ 2365557851 ePTOContactorCommand 521916;
BA_ "SPN" SG_ 2365557851 ePTOContactorPowerDownCommand 520066;
BA_ "SPN" SG_ 2365557851 OnboardChargerContactorCommand 521918;
BA_ "SPN" SG_ 2365557851 OnboardContactorPowerDownCommand 520067;
BA_ "SPN" SG_ 2365557851 OffBoardChargerContactorCmd 521920;
BA_ "SPN" SG_ 2365557851 OffBoardContactorPowerDownCmd 520068;
BA_ "SPN" SG_ 2365557851 ActiveIsolationTest 521951;
BA_ "SPN" SG_ 2365557851 MessageCounter 521922;
BA_ "SPN" SG_ 2365557851 MessageChecksum 521923;
BA_ "SPN" SG_ 2583630375 ScheduledChargingConditioningSta 520041;
BA_ "SPN" SG_ 2583630375 ScheduledChargingStartDemand 520042;
BA_ "SPN" SG_ 2583630375 ScheduledBatConditioningCharging 520043;
BA_ "SPN" SG_ 2583630375 ScheduledBatConditioningDriveOff 520044;
BA_ "SPN" SG_ 2556952103 PercentSpdCmd 9819;
BA_ "SigType" SG_ 2556952103 PercentSpdCmd 1;
BA_ "SPN" SG_ 2556952103 SpdCmd 9818;
BA_ "SigType" SG_ 2556952103 SpdCmd 1;
BA_ "SPN" SG_ 2556952103 PwrHold 9817;
BA_ "SigType" SG_ 2556952103 PwrHold 4;
BA_ "SPN" SG_ 2556952103 EnableCmd 9816;
BA_ "SigType" SG_ 2556952103 EnableCmd 4;
BA_ "SPN" SG_ 2365558046 DriveContactorState 521924;
BA_ "SPN" SG_ 2365558046 DrivePreChargeContactorState 521925;
BA_ "SPN" SG_ 2365558046 DriveContactorErrorState 520070;
BA_ "SPN" SG_ 2365558046 DrivePreChargeContactorErrorStat 520071;
BA_ "SPN" SG_ 2365558046 AuxiliaryContactorState 521928;
BA_ "SPN" SG_ 2365558046 AuxiliaryPreChargeContactorState 521929;
BA_ "SPN" SG_ 2365558046 AuxiliaryContactorErrorState 520072;
BA_ "SPN" SG_ 2365558046 AuxiliaryPreChargeContactorError 520073;
BA_ "SPN" SG_ 2365558046 ePTOPositiveContactorState 521930;
BA_ "SPN" SG_ 2365558046 ePTOPreChargeContactorState 521931;
BA_ "SPN" SG_ 2365558046 ePTOPositiveContactorErrorState 520074;
BA_ "SPN" SG_ 2365558046 ePTOPreChargeContactorErrorState 520075;
BA_ "SPN" SG_ 2365558046 ePTONegativeContactorState 521950;
BA_ "SPN" SG_ 2365558046 OnboardChargerContactorState_IM3 521932;
BA_ "SystemSignalLongSymbol" SG_ 2365558046 OnboardChargerContactorState_IM3 "OnboardChargerContactorState_IM30";
BA_ "SPN" SG_ 2365558046 ePTONegativeContactorErrorState 520076;
BA_ "SPN" SG_ 2365558046 OnboardChargerContactorErrorStat 520077;
BA_ "SystemSignalLongSymbol" SG_ 2365558046 OnboardChargerContactorErrorStat "OnboardChargerContactorErrorStat_IM30";
BA_ "SPN" SG_ 2365558046 OffBoardChargerPosContactorState 521934;
BA_ "SPN" SG_ 2365558046 OffBoardChargerNegContactorState 521935;
BA_ "SPN" SG_ 2365558046 OffBoardChargerPosContactorError 520078;
BA_ "SPN" SG_ 2365558046 OffBoardChargerNegContactorError 520079;
BA_ "SPN" SG_ 2365558046 HVILStatus1_Drive 521936;
BA_ "SPN" SG_ 2365558046 HVILStatus2_Aux 521937;
BA_ "SPN" SG_ 2365558046 HVILStatus3_ePTO 521938;
BA_ "SPN" SG_ 2365558046 HVJB_OperationalState 520061;
BA_ "SPN" SG_ 2365558046 HVJB_01MessageCounter 521939;
BA_ "SPN" SG_ 2365558046 HVJB_01MessageChecksum 521940;
BA_ "GenSigStartValue" SG_ 2365558302 DriveContactorActualCurrent 10000;
BA_ "SPN" SG_ 2365558302 DriveContactorActualCurrent 521941;
BA_ "SigType" SG_ 2365558302 DriveContactorActualCurrent 1;
BA_ "GenSigStartValue" SG_ 2365558302 AuxiliaryContactorActualCurrent 10000;
BA_ "SPN" SG_ 2365558302 AuxiliaryContactorActualCurrent 521942;
BA_ "SigType" SG_ 2365558302 AuxiliaryContactorActualCurrent 1;
BA_ "GenSigStartValue" SG_ 2365558302 ePTOContactorActualCurrent 10000;
BA_ "SPN" SG_ 2365558302 ePTOContactorActualCurrent 521943;
BA_ "SigType" SG_ 2365558302 ePTOContactorActualCurrent 1;
BA_ "GenSigStartValue" SG_ 2365558558 OffBoardChargerActualVoltage 10000;
BA_ "SPN" SG_ 2365558558 OffBoardChargerActualVoltage 521945;
BA_ "SigType" SG_ 2365558558 OffBoardChargerActualVoltage 1;
BA_ "SPN" SG_ 2365571870 ActiveIsolationTestStatus 521952;
BA_ "SPN" SG_ 2365571870 IsolationMonitorMeasurementType 522015;
BA_ "SPN" SG_ 2365571870 TestResultsPositive 521953;
BA_ "SigType" SG_ 2365571870 TestResultsPositive 1;
BA_ "SPN" SG_ 2365571870 TestResultsNegative 521954;
BA_ "SigType" SG_ 2365571870 TestResultsNegative 1;
BA_ "SPN" SG_ 2365571870 ActiveDischargeStatus 519969;
BA_ "SPN" SG_ 2566613790 HVBusDrivelineAvailability 20802;
BA_ "SPN" SG_ 2566613790 HVBusAuxiliariesAvailability 20803;
BA_ "SPN" SG_ 2566613790 HVBusePTOAvailability 20804;
BA_ "SPN" SG_ 2566613790 HVBusOnboardChargerAvailability 20805;
BA_ "SPN" SG_ 2566613790 HVBusOffBoardChargerAvailability 20806;
BA_ "SPN" SG_ 2364607476 HVESSThermalEventDetected 21287;
BA_ "SigType" SG_ 2364607476 HVESSThermalEventDetected 4;
BA_ "SPN" SG_ 2364607476 HVESSLowestCellTempCellNum 8244;
BA_ "SigType" SG_ 2364607476 HVESSLowestCellTempCellNum 1;
BA_ "SPN" SG_ 2364607476 HVESSLowestCellTempModuleNum 8243;
BA_ "SigType" SG_ 2364607476 HVESSLowestCellTempModuleNum 1;
BA_ "SPN" SG_ 2364607476 HVESSHighestCellTempCellNum 8242;
BA_ "SigType" SG_ 2364607476 HVESSHighestCellTempCellNum 1;
BA_ "SPN" SG_ 2364607476 HVESSHighestCellTempModuleNum 8241;
BA_ "SigType" SG_ 2364607476 HVESSHighestCellTempModuleNum 1;
BA_ "SPN" SG_ 2583632219 CabinACCompressorSpeed 522416;
BA_ "SigType" SG_ 2583632219 CabinACCompressorSpeed 1;
BA_ "SPN" SG_ 2583632219 CabinACCompressorErrorStatus 522417;
BA_ "SPN" SG_ 2583631911 UrgeToMoveActivationDemand 519747;
BA_ "SPN" SG_ 2583631911 UrgeToMoveOverruleDemand 519746;
BA_ "SPN" SG_ 2583631911 UrgeToMoveStatus 519744;
BA_ "SPN" SG_ 2566810971 AuxiliaryHeaterMode 1677;
BA_ "SPN" SG_ 2583631655 EnergyCapResPluginCharging 519827;
BA_ "SigType" SG_ 2583631655 EnergyCapResPluginCharging 1;
BA_ "SPN" SG_ 2583631655 EnergyCapResRegenerativeBraking 519828;
BA_ "SigType" SG_ 2583631655 EnergyCapResRegenerativeBraking 1;
BA_ "SPN" SG_ 2583629847 ChargingMethodSetting 520183;
BA_ "SPN" SG_ 2583629847 ServiceMenuHVDisableDemand 519743;
BA_ "SPN" SG_ 2583629847 HVBatteryCalibrationDemand 519733;
BA_ "SPN" SG_ 2583629847 ChargingSOCSetting 520184;
BA_ "SigType" SG_ 2583629847 ChargingSOCSetting 1;
BA_ "SPN" SG_ 2583629847 ChargingCurrentLimitSetting 520185;
BA_ "SigType" SG_ 2583629847 ChargingCurrentLimitSetting 1;
BA_ "SPN" SG_ 2583631604 HVESSContinuousChargeCurrent 519837;
BA_ "SigType" SG_ 2583631604 HVESSContinuousChargeCurrent 1;
BA_ "SPN" SG_ 2583631604 HVESSContinuousChargePower 519846;
BA_ "SigType" SG_ 2583631604 HVESSContinuousChargePower 1;
BA_ "SPN" SG_ 2583631604 HVESSMode 519847;
BA_ "SPN" SG_ 2583631604 HVESSChargedEnergyCycleCounter 521504;
BA_ "SPN" SG_ 2566889563 StopChargingSwitchIndication 519431;
BA_ "SPN" SG_ 2566889563 ChargingState 522022;
BA_ "SPN" SG_ 2566889563 ChargePlugLockedStatus 522023;
BA_ "SPN" SG_ 2566889563 ChargePlugUnlockedStatus 520173;
BA_ "SPN" SG_ 2566889563 ChargePlugNotSuppNotification 520174;
BA_ "SPN" SG_ 2566889563 ChargePlugTempNotification 520175;
BA_ "SPN" SG_ 2566889563 ChargingInterlockParkBrake 520176;
BA_ "SPN" SG_ 2566889563 EVSEErrorNotification 520177;
BA_ "SPN" SG_ 2566889563 EVSECommErrorNotification 520178;
BA_ "SPN" SG_ 2566889563 EVSEVoltageRangeNotification 520179;
BA_ "SPN" SG_ 2566889563 EVSECurrentRangeNotification 520180;
BA_ "SPN" SG_ 2566889563 EVSEIsolationFailNotification 520181;
BA_ "SPN" SG_ 2566889563 ChargeSessVehRestartNotification 520170;
BA_ "SPN" SG_ 2566889563 HVBatteryCalibrationStatus 519731;
BA_ "SPN" SG_ 2566889563 HVBattCalibrationPlannedForNextC 519732;
BA_ "SystemSignalLongSymbol" SG_ 2566889563 HVBattCalibrationPlannedForNextC "HVBattCalibrationPlannedForNextCharging";
BA_ "SPN" SG_ 2566889563 ChargingSOCActualSetting 519896;
BA_ "SPN" SG_ 2566889563 ChargeSOCDriverSettingNotPossibl 519897;
BA_ "SystemSignalLongSymbol" SG_ 2566889563 ChargeSOCDriverSettingNotPossibl "ChargeSOCDriverSettingNotPossibleInd";
BA_ "SPN" SG_ 2566889563 ChargingMethodSelected 520060;
BA_ "SPN" SG_ 2566889563 ChargingSOCTarget 520084;
BA_ "SigType" SG_ 2566889563 ChargingSOCTarget 1;
BA_ "SPN" SG_ 2566890587 ActualPercenteDrivePower 522030;
BA_ "SigType" SG_ 2566890587 ActualPercenteDrivePower 1;
BA_ "SPN" SG_ 2566890587 ActualPercentePTOPower 522031;
BA_ "SigType" SG_ 2566890587 ActualPercentePTOPower 1;
BA_ "SPN" SG_ 2566890587 MaxPercenteDrivePropulsionPowe 522032;
BA_ "SigType" SG_ 2566890587 MaxPercenteDrivePropulsionPowe 1;
BA_ "SPN" SG_ 2566890587 MaxPercenteDriveRegenPower 522033;
BA_ "SigType" SG_ 2566890587 MaxPercenteDriveRegenPower 1;
BA_ "SPN" SG_ 2566890587 HVBatteryUsageClassification 519742;
BA_ "SPN" SG_ 2566890587 RegenBrakingLimitedReason 519797;
BA_ "SPN" SG_ 2566890587 EHPSControlStatus 520168;
BA_ "SPN" SG_ 2566890587 RegenBrakingLimitedNotification 520055;
BA_ "SPN" SG_ 2566890587 HVACCompressorDemand 520053;
BA_ "SPN" SG_ 2364577115 HVESSIntakeCoolantTemperature 8088;
BA_ "SigType" SG_ 2364577115 HVESSIntakeCoolantTemperature 1;
BA_ "SPN" SG_ 2566775131 AirConditionerCompressorStatus 7853;
BA_ "SPN" SG_ 2566573919 CompatibilityCode 12935;
BA_ "SPN" SG_ 2566573919 InletConnectorTemp 12934;
BA_ "SigType" SG_ 2566573919 InletConnectorTemp 1;
BA_ "SPN" SG_ 2566573919 ProximityCircVoltage 12933;
BA_ "SigType" SG_ 2566573919 ProximityCircVoltage 1;
BA_ "SPN" SG_ 2566573919 CtrlPilotSubState 12932;
BA_ "SPN" SG_ 2566573919 CtrlPilotState 12931;
BA_ "SPN" SG_ 2566573919 CtrlPilotDutyCycle 12930;
BA_ "SigType" SG_ 2566573919 CtrlPilotDutyCycle 1;
BA_ "SPN" SG_ 2566573919 CtrlPilotPWMFreq 12929;
BA_ "SigType" SG_ 2566573919 CtrlPilotPWMFreq 1;
BA_ "SPN" SG_ 2566573919 CtrlPilotMinVoltage 12928;
BA_ "SigType" SG_ 2566573919 CtrlPilotMinVoltage 1;
BA_ "SPN" SG_ 2566573919 CtrlPilotMaxVoltage 12927;
BA_ "SigType" SG_ 2566573919 CtrlPilotMaxVoltage 1;
BA_ "SPN" SG_ 2566567003 EVSupportedEnergyTransferTypes 13158;
BA_ "SPN" SG_ 2566567003 EVDCChargingPwrMax 13157;
BA_ "SigType" SG_ 2566567003 EVDCChargingPwrMax 1;
BA_ "SPN" SG_ 2566567003 EVDCChargingCurMax 13156;
BA_ "SigType" SG_ 2566567003 EVDCChargingCurMax 1;
BA_ "SPN" SG_ 2566567003 EVDCChargingVMax 13155;
BA_ "SigType" SG_ 2566567003 EVDCChargingVMax 1;
BA_ "SPN" SG_ 2566544219 ErrorCode 21063;
BA_ "SPN" SG_ 2566544219 RESSConditioningFlag 21062;
BA_ "SigType" SG_ 2566544219 RESSConditioningFlag 5;
BA_ "SPN" SG_ 2566544219 CabinConditioningFlag 21061;
BA_ "SigType" SG_ 2566544219 CabinConditioningFlag 5;
BA_ "SPN" SG_ 2566567771 TargetChargingCurrent 13170;
BA_ "SigType" SG_ 2566567771 TargetChargingCurrent 1;
BA_ "SPN" SG_ 2566567771 TargetChargingVoltage 13169;
BA_ "SigType" SG_ 2566567771 TargetChargingVoltage 1;
BA_ "SPN" SG_ 2566567771 EVDCTGT_Counter 13168;
BA_ "SigType" SG_ 2566567771 EVDCTGT_Counter 11;
BA_ "SPN" SG_ 2566567771 EVDCTGT_CRC 13167;
BA_ "SigType" SG_ 2566567771 EVDCTGT_CRC 12;
BA_ "SPN" SG_ 2566575455 ACRMSCurrentLimitNeutral 13005;
BA_ "SigType" SG_ 2566575455 ACRMSCurrentLimitNeutral 1;
BA_ "SPN" SG_ 2566575455 ACRMSCurrentLimitL3 13004;
BA_ "SigType" SG_ 2566575455 ACRMSCurrentLimitL3 1;
BA_ "SPN" SG_ 2566575455 ACRMSCurrentLimitL2 13003;
BA_ "SigType" SG_ 2566575455 ACRMSCurrentLimitL2 1;
BA_ "SPN" SG_ 2566575455 ACRMSCurrentLimitL1 12865;
BA_ "SigType" SG_ 2566575455 ACRMSCurrentLimitL1 1;
BA_ "SPN" SG_ 2555600731 EVReady 21085;
BA_ "SigType" SG_ 2555600731 EVReady 5;
BA_ "SPN" SG_ 2555600731 DCStageReq 21084;
BA_ "SPN" SG_ 2555600731 ConnectorLockCmd 12864;
BA_ "SPN" SG_ 2566568287 DCInletContactorCommand 13178;
BA_ "SigType" SG_ 2566568287 DCInletContactorCommand 5;
BA_ "SPN" SG_ 2566568539 DCInletContactor1State 13181;
BA_ "SigType" SG_ 2566568539 DCInletContactor1State 5;
BA_ "SPN" SG_ 2566568539 DCChargingBusVoltage 13180;
BA_ "SigType" SG_ 2566568539 DCChargingBusVoltage 1;
BA_ "SPN" SG_ 2566568539 DCContactorInputVoltage 13179;
BA_ "SigType" SG_ 2566568539 DCContactorInputVoltage 1;
BA_ "SPN" SG_ 2566567263 EVSESupportedEnergyTransferTypes 13162;
BA_ "SPN" SG_ 2566567263 EVSEDCChargingPwrMax 13161;
BA_ "SigType" SG_ 2566567263 EVSEDCChargingPwrMax 1;
BA_ "SPN" SG_ 2566567263 EVSEDCChargingCurMax 13160;
BA_ "SigType" SG_ 2566567263 EVSEDCChargingCurMax 1;
BA_ "SPN" SG_ 2566567263 EVSEDCChargingVMax 13159;
BA_ "SigType" SG_ 2566567263 EVSEDCChargingVMax 1;
BA_ "SPN" SG_ 2566567519 EVSECurRegulationTolerance 13166;
BA_ "SigType" SG_ 2566567519 EVSECurRegulationTolerance 1;
BA_ "SPN" SG_ 2566567519 EVSEPeakCurRipple 13165;
BA_ "SigType" SG_ 2566567519 EVSEPeakCurRipple 1;
BA_ "SPN" SG_ 2566567519 EVSEDCChargingCurrentMin 13164;
BA_ "SigType" SG_ 2566567519 EVSEDCChargingCurrentMin 1;
BA_ "SPN" SG_ 2566567519 EVSEDCChargingVoltageMin 13163;
BA_ "SigType" SG_ 2566567519 EVSEDCChargingVoltageMin 1;
BA_ "SPN" SG_ 2566568031 EVSEResponseCode 21089;
BA_ "SPN" SG_ 2566568031 EVSEProcessingState 21088;
BA_ "SigType" SG_ 2566568031 EVSEProcessingState 4;
BA_ "SPN" SG_ 2566568031 EVSEIsolationStatus 21087;
BA_ "SPN" SG_ 2566568031 EVSEStatus 13177;
BA_ "SPN" SG_ 2566568031 EVSEPowerLimitReached 13176;
BA_ "SigType" SG_ 2566568031 EVSEPowerLimitReached 4;
BA_ "SPN" SG_ 2566568031 EVSECurrentLimitReached 13175;
BA_ "SigType" SG_ 2566568031 EVSECurrentLimitReached 4;
BA_ "SPN" SG_ 2566568031 EVSEVoltageLimitReached 13174;
BA_ "SigType" SG_ 2566568031 EVSEVoltageLimitReached 4;
BA_ "SPN" SG_ 2566568031 PresentDCChargingCurrent 13173;
BA_ "SigType" SG_ 2566568031 PresentDCChargingCurrent 1;
BA_ "SPN" SG_ 2566568031 PresentDCChargingVoltage 13172;
BA_ "SigType" SG_ 2566568031 PresentDCChargingVoltage 1;
BA_ "SPN" SG_ 2566568031 ChargingState 13171;
BA_ "SPN" SG_ 2566575711 EVSEConnectorLockPermission 21086;
BA_ "SigType" SG_ 2566575711 EVSEConnectorLockPermission 5;
BA_ "SPN" SG_ 2566575711 EVSEConnectorLockState 12863;
BA_ "SPN" SG_ 2566575711 EVSEManualOvrd 12862;
BA_ "SigType" SG_ 2566575711 EVSEManualOvrd 4;
BA_ "SPN" SG_ 2566575711 EVSEConnectorReleaseLatch 12861;
BA_ "SigType" SG_ 2566575711 EVSEConnectorReleaseLatch 5;
BA_ "SPN" SG_ 2558590815 ConnectedEnergySourceType 13154;
BA_ "SigType" SG_ 2558590815 ConnectedEnergySourceType 5;
BA_ "SPN" SG_ 2566837855 OffBoardChargerConnectionState 7551;
BA_ "SigType" SG_ 2566837855 OffBoardChargerConnectionState 4;
BA_ "SPN" SG_ 2566899039 CCU01_CRC 13167;
BA_ "SigType" SG_ 2566899039 CCU01_CRC 12;
BA_ "SPN" SG_ 2566899039 EVSEChargingPwrMax 13161;
BA_ "SigType" SG_ 2566899039 EVSEChargingPwrMax 1;
BA_ "SPN" SG_ 2566899039 EVSEDischargingPwrMax 13161;
BA_ "SigType" SG_ 2566899039 EVSEDischargingPwrMax 1;
BA_ "SPN" SG_ 2566899039 VehIsolationMoningDisCommand 521970;
BA_ "SPN" SG_ 2566899039 ProximityPinResistance 520048;
BA_ "SPN" SG_ 2566898779 StopChargingRequest 522047;
BA_ "SPN" SG_ 2566898779 EmergencyStopChargingRequest 521526;
BA_ "SPN" SG_ 2566898779 IsolationMonitorStatusVehicle 521958;
BA_ "SPN" SG_ 2566898779 PermitToSleep 519753;
BA_ "SigType" SG_ 2566898779 PermitToSleep 4;
BA_ "SPN" SG_ 2566898779 LED1Command 519898;
BA_ "SigType" SG_ 2566898779 LED1Command 4;
BA_ "SPN" SG_ 2566898779 LED2Command 519899;
BA_ "SigType" SG_ 2566898779 LED2Command 4;
BA_ "SPN" SG_ 2566898779 LED3Command 519900;
BA_ "SigType" SG_ 2566898779 LED3Command 4;
BA_ "SPN" SG_ 2365572954 ActualMaxAvailableGeneratorCurre 522036;
BA_ "SigType" SG_ 2365572954 ActualMaxAvailableGeneratorCurre 1;
BA_ "SystemSignalLongSymbol" SG_ 2365572954 ActualMaxAvailableGeneratorCurre "ActualMaxAvailableGeneratorCurrent";
BA_ "SPN" SG_ 2365572954 ActualMaxAvailableMotorCurrent 522037;
BA_ "SigType" SG_ 2365572954 ActualMaxAvailableMotorCurrent 1;
BA_ "SPN" SG_ 2365572954 ActualRequiredGeneratorCurrent 522038;
BA_ "SigType" SG_ 2365572954 ActualRequiredGeneratorCurrent 1;
BA_ "SPN" SG_ 2365572954 PowertrainCoolantFlowRateReq 519741;
BA_ "SigType" SG_ 2365572954 PowertrainCoolantFlowRateReq 1;
BA_ "SPN" SG_ 2583632475 BatteryPotentialPowerInput1 519445;
BA_ "SigType" SG_ 2583632475 BatteryPotentialPowerInput1 1;
BA_ "SPN" SG_ 2583632475 HVS06_Counter 519446;
BA_ "SPN" SG_ 2583632475 HVS06_Checksum 519447;
BA_ "SPN" SG_ 2583633755 ActualPowerMotorGenerator 519404;
BA_ "SigType" SG_ 2583633755 ActualPowerMotorGenerator 1;
BA_ "SPN" SG_ 2583633755 ActualPowerAuxiliaries 519405;
BA_ "SigType" SG_ 2583633755 ActualPowerAuxiliaries 1;
BA_ "SPN" SG_ 2583633755 ActualPowerePTO 519406;
BA_ "SigType" SG_ 2583633755 ActualPowerePTO 1;
BA_ "SPN" SG_ 2583633755 ActualPowerBrakeResistor 519407;
BA_ "SigType" SG_ 2583633755 ActualPowerBrakeResistor 1;
BA_ "SPN" SG_ 2365573150 OnboardChargerContactorState 521932;
BA_ "SPN" SG_ 2365573150 OnboardChargerPreChargeContactor 519970;
BA_ "SystemSignalLongSymbol" SG_ 2365573150 OnboardChargerPreChargeContactor "OnboardChargerPreChargeContactorState";
BA_ "SPN" SG_ 2365573150 OnboardChargerContactorErro_0000 520077;
BA_ "SystemSignalLongSymbol" SG_ 2365573150 OnboardChargerContactorErro_0000 "OnboardChargerContactorErrorState";
BA_ "SPN" SG_ 2365573150 OnboardChargerPreChargeCont_0000 519971;
BA_ "SystemSignalLongSymbol" SG_ 2365573150 OnboardChargerPreChargeCont_0000 "OnboardChargerPreChargeContactorErrorState";
BA_ "SPN" SG_ 2365573150 HVJBDischargeCurrentLimit 519437;
BA_ "SigType" SG_ 2365573150 HVJBDischargeCurrentLimit 1;
BA_ "SPN" SG_ 2365573150 HVJBChargeCurrentLimit 519438;
BA_ "SigType" SG_ 2365573150 HVJBChargeCurrentLimit 1;
BA_ "SPN" SG_ 2365573150 HVJBTemperatureState 519439;
BA_ "SPN" SG_ 2365573150 HVJB_05MessageCounter 519972;
BA_ "SPN" SG_ 2365573150 HVJB_05MessageChecksum 519973;
BA_ "SPN" SG_ 2566857511 VehicleHVEnableRequest 522027;
BA_ "SPN" SG_ 2566857511 ePTOHVActivationRequest 522028;
BA_ "SPN" SG_ 2566857511 CabACCompressorEnableRequest 520051;
BA_ "SPN" SG_ 2566857511 LowVoltageBatteryChargeRequest 519739;
BA_ "SPN" SG_ 2566857511 StopChargingSwitchStatus 522029;
BA_ "SPN" SG_ 2566857511 CabinDoorLockStatus 520169;
BA_ "SPN" SG_ 2566857511 CabinHeaterEnableCommand 522414;
BA_ "SPN" SG_ 2566857511 BackofficeStopChargingDemand 519720;
BA_ "SPN" SG_ 2566857511 BackofficeChargingMethodSetting 519721;
BA_ "SPN" SG_ 2566857511 BackofficeHighVoltageBattCalibra 519723;
BA_ "SPN" SG_ 2566857511 BackofficeChargingSOCSetting 519722;
BA_ "SPN" SG_ 2566857511 CabHtrCoolantTempReq 522415;
BA_ "SigType" SG_ 2566857511 CabHtrCoolantTempReq 1;
BA_ "SPN" SG_ 2566857511 CabACCompressorSpeedRequest 520167;
BA_ "SigType" SG_ 2566857511 CabACCompressorSpeedRequest 1;
BA_ "SPN" SG_ 2565942823 EPTO_ACSideMotorStartingRMSVReq 9552;
BA_ "SigType" SG_ 2565942823 EPTO_ACSideMotorStartingRMSVReq 1;
BA_ "SPN" SG_ 2565942823 EPTO_OperationalCommand 9329;
BA_ "SigType" SG_ 2565942823 EPTO_OperationalCommand 5;
BA_ "SPN" SG_ 2565942823 EPTO_Status2 9328;
BA_ "SPN" SG_ 2565942823 EPTO_Status1 9327;
BA_ "SPN" SG_ 2565942823 EPTO_FrequencyCommand 9326;
BA_ "SigType" SG_ 2565942823 EPTO_FrequencyCommand 1;
BA_ "SPN" SG_ 2565942823 EPTO_FreqRateOfChangeLmt 9325;
BA_ "SigType" SG_ 2565942823 EPTO_FreqRateOfChangeLmt 1;
BA_ "SPN" SG_ 2565942823 EPTO_RatedRMSVoltage 9324;
BA_ "SigType" SG_ 2565942823 EPTO_RatedRMSVoltage 1;
BA_ "SPN" SG_ 2565942823 EPTO_RatedFrequency 9323;
BA_ "SigType" SG_ 2565942823 EPTO_RatedFrequency 1;
BA_ "SPN" SG_ 2565942823 EPTO_MinFrequency 9322;
BA_ "SigType" SG_ 2565942823 EPTO_MinFrequency 1;
BA_ "SPN" SG_ 2565942823 EPTO_MaxFrequency 9321;
BA_ "SigType" SG_ 2565942823 EPTO_MaxFrequency 1;
BA_ "SPN" SG_ 2365304574 EPTO_CurrentMinLimitReq 9554;
BA_ "SigType" SG_ 2365304574 EPTO_CurrentMinLimitReq 1;
BA_ "SPN" SG_ 2365304574 EPTO_VoltageMaxLimitReq 9553;
BA_ "SigType" SG_ 2365304574 EPTO_VoltageMaxLimitReq 1;
BA_ "SPN" SG_ 2365304574 EPTO_CurrentMaxLimitReq 9358;
BA_ "SigType" SG_ 2365304574 EPTO_CurrentMaxLimitReq 1;
BA_ "SPN" SG_ 2365304574 EPTO_VoltageMinLimitReq 9357;
BA_ "SigType" SG_ 2365304574 EPTO_VoltageMinLimitReq 1;
BA_ "SPN" SG_ 2566865178 DCDC_LVVoltage 520092;
BA_ "SigType" SG_ 2566865178 DCDC_LVVoltage 1;
BA_ "GenSigStartValue" SG_ 2566865178 DCDC_LVCurrent 10000;
BA_ "SPN" SG_ 2566865178 DCDC_LVCurrent 520091;
BA_ "SigType" SG_ 2566865178 DCDC_LVCurrent 1;
BA_ "SPN" SG_ 2566865178 DCDC_HVVoltage 520090;
BA_ "SigType" SG_ 2566865178 DCDC_HVVoltage 1;
BA_ "GenSigStartValue" SG_ 2566865178 DCDC_HVCurrent 10000;
BA_ "SPN" SG_ 2566865178 DCDC_HVCurrent 520089;
BA_ "SigType" SG_ 2566865178 DCDC_HVCurrent 1;
BA_ "SPN" SG_ 2365573467 HVESSModeRequest 519844;
BA_ "SPN" SG_ 2365573467 HVESSStopPreconditioningRequest 519845;
VAL_ 2566613851 HVDCBusAvailability 0 "HVDC bus is not connected." 1 "HVDC bus is connected." 2 "HVDC bus connection in process." 3 "HVDC bus disconnecting" 5 "HVDC bus disconnect forewarning" 14 "Error" 15 "NA" ;
VAL_ 2566613851 HVBusDrivelineAvailability 0 "HVDC bus is not connected." 1 "HVDC bus is connected." 2 "HVDC bus connection in process." 3 "HVDC bus disconnecting" 5 "HVDC bus disconnect forewarning" 14 "Error" 15 "NA" ;
VAL_ 2566613851 HVBusAuxiliariesAvailability 0 "HVDC bus is not connected." 1 "HVDC bus is connected." 2 "HVDC bus connection in process." 3 "HVDC bus disconnecting" 5 "HVDC bus disconnect forewarning" 14 "Error" 15 "NA" ;
VAL_ 2566613851 HVBusePTOAvailability 0 "HVDC bus is not connected." 1 "HVDC bus is connected." 2 "HVDC bus connection in process." 3 "HVDC bus disconnecting" 5 "HVDC bus disconnect forewarning" 14 "Error" 15 "NA" ;
VAL_ 2566613851 HVBusOnboardChargerAvailability 0 "HVDC bus is not connected." 1 "HVDC bus is connected." 2 "HVDC bus connection in process." 3 "HVDC bus disconnecting" 5 "HVDC bus disconnect forewarning" 14 "Error" 15 "NA" ;
VAL_ 2566613851 HVBusOffBoardChargerAvailability 0 "HVDC bus is not connected." 1 "HVDC bus is connected." 2 "HVDC bus connection in process." 3 "HVDC bus disconnecting" 5 "HVDC bus disconnect forewarning" 14 "Error" 15 "NA" ;
VAL_ 2566658651 HVESSThermalManagementSystemHtrE 3 "NOT_AVAILABLE" ;
VAL_ 2566722907 BatteryCharger1State 0 "Idling" 1 "Charging" 2 "Standby or maintaining" 3 "Reserved1" 4 "Reserved2" 5 "Reserved3" 6 "Reserved4" 7 "Reserved5" 8 "Reserved6" 9 "Reserved7" 10 "Reserved8" 11 "Reserved9" 12 "Reserved10" 13 "Battery failure" 14 "Charger failure" 15 "Not available" ;
VAL_ 2566722907 BatteryCharger1PowerLineState 0 "Disconnected" 1 "Connected" 2 "Error" 3 "Not available" ;
VAL_ 2566722907 BCH1_RestartRequiredState 0 "Normal Operation" 1 "Restart Required" 2 "Error" 3 "NotAvailable" ;
VAL_ 2566771751 OperatorKeySwitchIgnitionPower 0 "NOT_ACTIVE" 1 "ACTIVE" 2 "ERROR" 3 "NOT_AVAILABLE" ;
VAL_ 2566827568 ServiceBrakeCircuit1AirPressure 251 "PARAMETER_SPECIFIC" 254 "ERROR" 255 "NOT_AVAILABLE" ;
VAL_ 2566827568 ServiceBrakeCircuit2AirPressure 251 "PARAMETER_SPECIFIC" 254 "ERROR" 255 "NOT_AVAILABLE" ;
VAL_ 2566827568 AirCompressorStatus 0 "NOT_ACTIVE" 1 "ACTIVE" 2 "ERROR" 3 "NOT_AVAILABLE" ;
VAL_ 2566840154 NominalFrictionPercentTorque 251 "PARAMETER_SPECIFIC" 254 "ERROR" 255 "NOT_AVAILABLE" ;
VAL_ 2566842094 Seconds 251 "PARAMETER_SPECIFIC" 254 "ERROR" 255 "NOT_AVAILABLE" ;
VAL_ 2566842094 Minutes 251 "PARAMETER_SPECIFIC" 254 "ERROR" 255 "NOT_AVAILABLE" ;
VAL_ 2566842094 Hours 251 "PARAMETER_SPECIFIC" 254 "ERROR" 255 "NOT_AVAILABLE" ;
VAL_ 2566842094 Month 251 "PARAMETER_SPECIFIC" 254 "ERROR" 255 "NOT_AVAILABLE" ;
VAL_ 2566842094 Day 251 "PARAMETER_SPECIFIC" 254 "ERROR" 255 "NOT_AVAILABLE" ;
VAL_ 2566842094 Year 251 "PARAMETER_SPECIFIC" 254 "ERROR" 255 "NOT_AVAILABLE" ;
VAL_ 2566845696 BarometricPressure 251 "PARAMETER_SPECIFIC" 254 "ERROR" 255 "NOT_AVAILABLE" ;
VAL_ 2566803211 VDCbrakelightrequest 0 "OFF" 1 "ON" 3 "NOT_AVAILABLE" ;
VAL_ 2566803211 ROPEngineControlactive 0 "PASSIVE" 1 "ACTIVE" 3 "NOT_AVAILABLE" ;
VAL_ 2566803211 ROPBrakeControlactive 0 "PASSIVE" 1 "ACTIVE" 3 "NOT_AVAILABLE" ;
VAL_ 2566803211 YCEngineControlactive 0 "PASSIVE" 1 "ACTIVE" 3 "NOT_AVAILABLE" ;
VAL_ 2566803211 YCBrakeControlactive 0 "PASSIVE" 1 "ACTIVE" 3 "NOT_AVAILABLE" ;
VAL_ 2565867787 SteeringWheelAngle 65535 "NOT_AVAILABLE" ;
VAL_ 2565867787 SteeringWheelTurnCounter 63 "NOT_AVAILABLE" ;
VAL_ 2565867787 LongitudinalAcceleration 251 "PARAMETER_SPECIFIC" 254 "ERROR" 255 "NOT_AVAILABLE" ;
VAL_ 2566878532 CabinHeaterStatus 3 "NOT_AVAILABLE" ;
VAL_ 2566878532 CabinHeaterHVILStatus 3 "NOT_AVAILABLE" ;
VAL_ 2566878532 CabinHtrOutputCoolantTemperature 251 "PARAMETER_SPECIFIC" 254 "ERROR" 255 "NOT_AVAILABLE" ;
VAL_ 2566878532 CabinHeaterCurrent 64256 "PARAMETER_SPECIFIC" 65280 "ERROR" 65535 "NOT_AVAILABLE" ;
VAL_ 2566878532 CabinHeaterVoltage 64256 "PARAMETER_SPECIFIC" 65280 "ERROR" 65535 "NOT_AVAILABLE" ;
VAL_ 2566878532 CabinHeaterInternalCurrentLimit 64256 "PARAMETER_SPECIFIC" 65280 "NOT_AVAILABLE" 65535 "NOT_AVAILABLE" ;
VAL_ 2365557851 DriveContactorCommand 0 "ContactorOpen" 1 "ContactorClosed" 2 "Error" 3 "Notavailable" ;
VAL_ 2365557851 DriveContactorPowerDownCommand 0 "Power-down not requested" 1 "Normal power-down" 2 "Emergency power-down" 3 "Dont care/Take no action" ;
VAL_ 2365557851 AuxiliaryContactorCommand 0 "ContactorOpen" 1 "ContactorClosed" 2 "Error" 3 "Notavailable" ;
VAL_ 2365557851 AuxiliaryContactorPowerDownCmd 0 "Power-down not requested" 1 "Normal power-down" 2 "Emergency power-down" 3 "Dont care/Take no action" ;
VAL_ 2365557851 ePTOContactorCommand 0 "ContactorOpen" 1 "ContactorClosed" 2 "Error" 3 "Notavailable" ;
VAL_ 2365557851 ePTOContactorPowerDownCommand 0 "Power-down not requested" 1 "Normal power-down" 2 "Emergency power-down" 3 "Dont care/Take no action" ;
VAL_ 2365557851 OnboardChargerContactorCommand 0 "ContactorOpen" 1 "ContactorClosed" 2 "Error" 3 "Notavailable" ;
VAL_ 2365557851 OnboardContactorPowerDownCommand 0 "Power-down not requested" 1 "Normal power-down" 2 "Emergency power-down" 3 "Dont care/Take no action" ;
VAL_ 2365557851 OffBoardChargerContactorCmd 0 "ContactorOpen" 1 "ContactorClosed" 2 "Error" 3 "Notavailable" ;
VAL_ 2365557851 OffBoardContactorPowerDownCmd 0 "Power-down not requested" 1 "Normal power-down" 2 "Emergency power-down" 3 "Dont care/Take no action" ;
VAL_ 2365557851 ActiveIsolationTest 0 "Not requested" 1 "Test requested" 2 "Inhibit request " 3 "Don't care/Take no action" ;
VAL_ 2583630375 ScheduledChargingConditioningSta 3 "NOT_AVAILABLE" ;
VAL_ 2583630375 ScheduledChargingStartDemand 3 "NOT_AVAILABLE" ;
VAL_ 2583630375 ScheduledBatConditioningCharging 3 "NOT_AVAILABLE" ;
VAL_ 2583630375 ScheduledBatConditioningDriveOff 3 "NOT_AVAILABLE" ;
VAL_ 2556952103 PwrHold 0 "Power Hold Disabled" 1 "Power Hold Enabled" 2 "Reserved" 3 "Don't Care/Take no action" ;
VAL_ 2556952103 EnableCmd 0 "Motor Off" 1 "Motor On Normal Direction" 2 "Motor On Reverse Direction" 3 "Don't Care/Take no action" ;
VAL_ 2365558046 DriveContactorState 0 "ContactorOpen" 1 "ContactorClosed" 2 "Error" 3 "Notavailable" ;
VAL_ 2365558046 DrivePreChargeContactorState 0 "ContactorOpen" 1 "ContactorClosed" 2 "Error" 3 "Notavailable" ;
VAL_ 2365558046 DriveContactorErrorState 0 "Other error" 1 "Failed to Open" 2 "Failed to Close" 3 "Take no action" ;
VAL_ 2365558046 DrivePreChargeContactorErrorStat 0 "Other error" 1 "Failed to Open" 2 "Failed to Close" 3 "Take no action" ;
VAL_ 2365558046 AuxiliaryContactorState 0 "ContactorOpen" 1 "ContactorClosed" 2 "Error" 3 "Notavailable" ;
VAL_ 2365558046 AuxiliaryPreChargeContactorState 0 "ContactorOpen" 1 "ContactorClosed" 2 "Error" 3 "Notavailable" ;
VAL_ 2365558046 AuxiliaryContactorErrorState 0 "Other error" 1 "Failed to Open" 2 "Failed to Close" 3 "Take no action" ;
VAL_ 2365558046 AuxiliaryPreChargeContactorError 0 "Other error" 1 "Failed to Open" 2 "Failed to Close" 3 "Take no action" ;
VAL_ 2365558046 ePTOPositiveContactorState 0 "ContactorOpen" 1 "ContactorClosed" 2 "Error" 3 "Notavailable" ;
VAL_ 2365558046 ePTOPreChargeContactorState 0 "ContactorOpen" 1 "ContactorClosed" 2 "Error" 3 "Notavailable" ;
VAL_ 2365558046 ePTOPositiveContactorErrorState 0 "Other error" 1 "Failed to Open" 2 "Failed to Close" 3 "Take no action" ;
VAL_ 2365558046 ePTOPreChargeContactorErrorState 0 "Other error" 1 "Failed to Open" 2 "Failed to Close" 3 "Take no action" ;
VAL_ 2365558046 ePTONegativeContactorState 0 "ContactorOpen" 1 "ContactorClosed" 2 "Error" 3 "Notavailable" ;
VAL_ 2365558046 OnboardChargerContactorState_IM3 0 "ContactorOpen" 1 "ContactorClosed" 2 "Error" 3 "Notavailable" ;
VAL_ 2365558046 ePTONegativeContactorErrorState 0 "Other error" 1 "Failed to Open" 2 "Failed to Close" 3 "Take no action" ;
VAL_ 2365558046 OnboardChargerContactorErrorStat 0 "Other error" 1 "Failed to Open" 2 "Failed to Close" 3 "Take no action" ;
VAL_ 2365558046 OffBoardChargerPosContactorState 0 "ContactorOpen" 1 "ContactorClosed" 2 "Error" 3 "Notavailable" ;
VAL_ 2365558046 OffBoardChargerNegContactorState 0 "ContactorOpen" 1 "ContactorClosed" 2 "Error" 3 "Notavailable" ;
VAL_ 2365558046 OffBoardChargerPosContactorError 0 "Other error" 1 "Failed to Open" 2 "Failed to Close" 3 "Take no action" ;
VAL_ 2365558046 OffBoardChargerNegContactorError 0 "Other error" 1 "Failed to Open" 2 "Failed to Close" 3 "Take no action" ;
VAL_ 2365558046 HVILStatus1_Drive 0 "HVILClosed" 1 "HVILOpen" 2 "Error" 3 "NotAvailable" ;
VAL_ 2365558046 HVILStatus2_Aux 0 "HVILClosed" 1 "HVILOpen" 2 "Error" 3 "NotAvailable" ;
VAL_ 2365558046 HVILStatus3_ePTO 0 "HVILClosed" 1 "HVILOpen" 2 "Error" 3 "NotAvailable" ;
VAL_ 2365558046 HVJB_OperationalState 0 "Startup" 1 "Operational" 14 "Error" 15 "NotAvailable" ;
VAL_ 2365558302 DriveContactorActualCurrent 64256 "PARAMETER_SPECIFIC" 64511 "PARAMETER_SPECIFIC" 65024 "ERROR" 65279 "ERROR" 65280 "NOT_AVAILABLE" 65535 "NOT_AVAILABLE" ;
VAL_ 2365558302 AuxiliaryContactorActualCurrent 64256 "PARAMETER_SPECIFIC" 64511 "PARAMETER_SPECIFIC" 65024 "ERROR" 65279 "ERROR" 65280 "NOT_AVAILABLE" 65535 "NOT_AVAILABLE" ;
VAL_ 2365558302 ePTOContactorActualCurrent 64256 "PARAMETER_SPECIFIC" 64511 "PARAMETER_SPECIFIC" 65024 "ERROR" 65279 "ERROR" 65280 "NOT_AVAILABLE" 65535 "NOT_AVAILABLE" ;
VAL_ 2365558558 OffBoardChargerActualVoltage 64256 "PARAMETER_SPECIFIC" 64511 "PARAMETER_SPECIFIC" 65024 "ERROR" 65279 "ERROR" 65280 "NOT_AVAILABLE" 65535 "NOT_AVAILABLE" ;
VAL_ 2365571870 ActiveIsolationTestStatus 0 "No test Requested" 1 "Test Requested" 2 "Test in Process" 3 "Test Complete; Acceptable" 4 "Test Complete; Marginal" 5 "Test Complete; Fault" 6 "Test is inhibited" 14 "Error" 15 "Not available" ;
VAL_ 2365571870 IsolationMonitorMeasurementType 0 "Estimation" 1 "Startup measurement" 2 "Normal measurement" 3 "NOT_AVAILABLE" ;
VAL_ 2365571870 TestResultsPositive 64256 "PARAMETER_SPECIFIC" 64511 "PARAMETER_SPECIFIC" 65024 "ERROR" 65279 "ERROR" 65280 "NOT_AVAILABLE" 65535 "NOT_AVAILABLE" ;
VAL_ 2365571870 TestResultsNegative 64256 "PARAMETER_SPECIFIC" 64511 "PARAMETER_SPECIFIC" 65024 "ERROR" 65279 "ERROR" 65280 "NOT_AVAILABLE" 65535 "NOT_AVAILABLE" ;
VAL_ 2365571870 ActiveDischargeStatus 0 "Not Active" 1 "Active" 2 "Error" 3 "NotAvailable" ;
VAL_ 2566613790 HVBusDrivelineAvailability 0 "HVDC bus is not connected." 1 "HVDC bus is connected." 2 "HVDC bus connection in process." 3 "HVDC bus disconnecting" 5 "HVDC bus disconnect forewarning" 14 "Error" 15 "NA" ;
VAL_ 2566613790 HVBusAuxiliariesAvailability 0 "HVDC bus is not connected." 1 "HVDC bus is connected." 2 "HVDC bus connection in process." 3 "HVDC bus disconnecting" 5 "HVDC bus disconnect forewarning" 14 "Error" 15 "NA" ;
VAL_ 2566613790 HVBusePTOAvailability 0 "HVDC bus is not connected." 1 "HVDC bus is connected." 2 "HVDC bus connection in process." 3 "HVDC bus disconnecting" 5 "HVDC bus disconnect forewarning" 14 "Error" 15 "NA" ;
VAL_ 2566613790 HVBusOnboardChargerAvailability 0 "HVDC bus is not connected." 1 "HVDC bus is connected." 2 "HVDC bus connection in process." 3 "HVDC bus disconnecting" 5 "HVDC bus disconnect forewarning" 14 "Error" 15 "NA" ;
VAL_ 2566613790 HVBusOffBoardChargerAvailability 0 "HVDC bus is not connected." 1 "HVDC bus is connected." 2 "HVDC bus connection in process." 3 "HVDC bus disconnecting" 5 "HVDC bus disconnect forewarning" 14 "Error" 15 "NA" ;
VAL_ 2364607476 HVESSThermalEventDetected 0 "No Thermal Event Detected" 1 "Thermal Event Detected" 2 "Error" 3 "Not available" ;
VAL_ 2583632219 CabinACCompressorErrorStatus 0 "No error" 1 "Error" 2 "Reserved" 3 "Not available" ;
VAL_ 2583631911 UrgeToMoveActivationDemand 0 "No activation demand" 1 "Activation demand" 2 "Reserved" 3 "Don't care/take no action" ;
VAL_ 2583631911 UrgeToMoveOverruleDemand 0 "Not Overruled" 1 "Overruled" 2 "Reserved" 3 "Don't care/take no action" ;
VAL_ 2583631911 UrgeToMoveStatus 0 "Disabled" 1 "Inactive" 2 "Active" 3 "Reserved" 4 "Reserved" 5 "Reserved" 6 "Error" 7 "Not Available" ;
VAL_ 2566810971 AuxiliaryHeaterMode 0 "Heater not active" 1 "ADR Inhibit" 2 "Economy mode" 3 "Normal mode" 4 "Heater pump up-keep " 5 "Heater Starting " 6 "Heater Stopping" 7 "Diagnose Active" 8 "Heater Locked" 9 "Reserved1" 10 "Reserved2" 11 "Reserved3" 12 "Reserverd4" 13 "Reserved5" 14 "Error" 15 "Not Available" ;
VAL_ 2583629847 ChargingMethodSetting 0 "Unsecured" 1 "Secured" 2 "Reserved" 3 "Not available" ;
VAL_ 2583629847 ServiceMenuHVDisableDemand 0 "Not requested" 1 "Request to shutdown HV" 2 "Reserved" 3 "Not available" ;
VAL_ 2583629847 HVBatteryCalibrationDemand 0 "Not active" 1 "Active" 2 "Reserved" 3 "Not available" ;
VAL_ 2583631604 HVESSMode 0 "Discharge mode" 1 "Charge mode" 2 "In transition" 3 "Not available" ;
VAL_ 2583631604 HVESSChargedEnergyCycleCounter 1 "Counter value" 13 "Reserved" 15 "Not available" ;
VAL_ 2566889563 StopChargingSwitchIndication 0 "Off" 1 "On" 2 "Error" 3 "Not Available" ;
VAL_ 2566889563 ChargingState 0 "Not connected" 1 "Initializing" 2 "Charging" 3 "Charging Stopped" 4 "Charging Completed" 5 "Charging Error" 6 "Charging Scheduled" 7 "Charging Interrupted" 8 "Charging Paused" 9 "Charging Shutdown Active" 10 "Reserved" 11 "Reserved" 12 "Reserved" 13 "Reserved" 14 "Error" 15 "Not available" ;
VAL_ 2566889563 ChargePlugLockedStatus 0 "Not locked" 1 "Locked" 2 "Error" 3 "Not available" ;
VAL_ 2566889563 ChargePlugUnlockedStatus 0 "Not unlocked" 1 "Unlocked" 2 "Error" 3 "Not available" ;
VAL_ 2566889563 ChargePlugNotSuppNotification 0 "Inactive" 1 "Active" 2 "Reserved" 3 "Not available" ;
VAL_ 2566889563 ChargePlugTempNotification 0 "Not active" 1 "Active" 2 "Reserved" 3 "Not available" ;
VAL_ 2566889563 ChargingInterlockParkBrake 0 "Not active" 1 "Active" 2 "Reserved" 3 "Not available" ;
VAL_ 2566889563 EVSEErrorNotification 0 "Not active" 1 "Active" 2 "Reserved" 3 "Not available" ;
VAL_ 2566889563 EVSECommErrorNotification 0 "Not active" 1 "Active" 2 "Reserved" 3 "Not available" ;
VAL_ 2566889563 EVSEVoltageRangeNotification 0 "Not active" 1 "Active" 2 "Reserved" 3 "Not available" ;
VAL_ 2566889563 EVSECurrentRangeNotification 0 "Not active" 1 "Active" 2 "Reserved" 3 "Not available" ;
VAL_ 2566889563 EVSEIsolationFailNotification 0 "Not active" 1 "Active" 2 "Reserved" 3 "Not available" ;
VAL_ 2566889563 ChargeSessVehRestartNotification 0 "Not active" 1 "Active" 2 "Reserved" 3 "Not available" ;
VAL_ 2566889563 HVBatteryCalibrationStatus 0 "Not required" 1 "Required" 2 "Reserved" 3 "Not available" ;
VAL_ 2566889563 HVBattCalibrationPlannedForNextC 0 "Not active" 1 "Active" 2 "Reserved" 3 "Not available" ;
VAL_ 2566889563 ChargingSOCActualSetting 0 "30%" 1 "35%" 2 "40%" 3 "45%" 4 "50%" 5 "55%" 6 "60%" 7 "65%" 8 "70%" 9 "75%" 10 "80%" 11 "85%" 12 "90%" 13 "95%" 14 "100%" 15 "Not available" ;
VAL_ 2566889563 ChargeSOCDriverSettingNotPossibl 0 "Not active" 1 "Active" 2 "Reserved" 3 "Not available" ;
VAL_ 2566889563 ChargingMethodSelected 0 "Unsecured" 1 "Secured" 2 "Reserved" 3 "Not available" ;
VAL_ 2566890587 HVBatteryUsageClassification 0 "HV battery disconnected" 1 "HV battery disconnection in progress" 2 "HV battery connected - normal usage" 3 "HV battery connected - thermal after run" 4 "HV battery connected - auxiliaries only" 5 "Reserved" 15 "Not Available" ;
VAL_ 2566890587 RegenBrakingLimitedReason 0 "Normal Operation" 1 "Battery State of Charge too high" 2 "Battery Temperature too low" 3 "Reserved" 4 "Reserved" 5 "Reserved" 6 "Reserved" 7 "Not Available" ;
VAL_ 2566890587 EHPSControlStatus 0 "Normal Operation" 1 "Derated Operation" 2 "Derated Operation Imminent" 3 "Not Available" ;
VAL_ 2566890587 RegenBrakingLimitedNotification 0 "Normal Operation" 1 "Derated Operation" 2 "Reserved" 3 "Not Available" ;
VAL_ 2566890587 HVACCompressorDemand 0 "Not active" 1 "Active" 2 "Error" 3 "Not Available" ;
VAL_ 2566775131 AirConditionerCompressorStatus 0 "Air Conditioner Compressor is OFF" 1 "Air Conditioner Compressor is ON" 2 "Error" 3 "Not Available" ;
VAL_ 2566573919 CompatibilityCode 0 "EVSE is compatible" 1 "Digital Communications" 2 "Ventilation" 3 "Reserved" 4 "Reserved" 5 "Reserved" 6 "Reserved" 7 "Reserved" 8 "Reserved" 9 "Reserved" 10 "Reserved" 11 "Reserved" 12 "Reserved" 13 "Other" 14 "No EVSE connected" 15 "Not available" ;
VAL_ 2566573919 CtrlPilotSubState 0 "Sub-state 1" 1 "Sub-state 2" 2 "LIN communications detected on Control Pilot." 3 "Reserved" 4 "Reserved" 5 "Reserved" 6 "Reserved" 7 "Reserved" 8 "Reserved" 9 "Reserved" 10 "Reserved" 11 "Reserved" 12 "Reserved" 13 "Pending" 14 "Error" 15 "Not available" ;
VAL_ 2566573919 CtrlPilotState 0 "State A" 1 "State B" 2 "State C" 3 "State D" 4 "State E" 5 "State F" 6 "Reserved" 7 "Reserved" 8 "Reserved" 9 "Reserved" 10 "Reserved" 11 "Reserved" 12 "Reserved" 13 "Pending" 14 "Error" 15 "Not available" ;
VAL_ 2566567003 EVSupportedEnergyTransferTypes 0 "DC-Extended" 1 "DC-Core" ;
VAL_ 2566544219 ErrorCode 0 "No Error" 1 "Battery Temperature too hot/cold" 2 "Shift Position " 3 "Connector Lock fault" 4 "Vehicle charging system fault" 5 "Charging Current differential" 6 "Charging Voltage Out of Range" 7 "Reserved" 8 "Reserved" 9 "Reserved" 10 "Reserved" 11 "Reserved" 12 "Reserved" 13 "Charging system not compatible" 14 "No Data" 15 "Not available" ;
VAL_ 2566544219 RESSConditioningFlag 0 "Battery conditioning not active" 1 "Battery conditioning active" 2 "Reserved" 3 "Not available" ;
VAL_ 2566544219 CabinConditioningFlag 0 "Cabin conditioning not active" 1 "Cabin conditioning active" 2 "Reserved" 3 "Not available" ;
VAL_ 2555600731 EVReady 0 "Not Ready" 1 "Ready" 2 "Reserved" 3 "Not available" ;
VAL_ 2555600731 DCStageReq 0 "Idle" 1 "Parameter Discovery Request" 2 "Cable Check Request" 3 "Pre-Charge Request" 4 "Power Delivery Request, Ready To Charge State = TRUE)" 5 "Current Demand Request" 6 "Power Delivery Request, Ready To Charge State = FALSE)" 7 "Welding Detection Request" 8 "Termination Request" 9 "Reserved" 10 "Reserved" 11 "Reserved" 12 "Reserved" 13 "Reserved" 14 "Reserved" 15 "Don't care" ;
VAL_ 2555600731 ConnectorLockCmd 0 "Unlock Request" 1 "Lock Request" 2 "Reserved" 3 "Reserved" 4 "Reserved" 5 "Reserved" 6 "Reserved" 7 "Reserved" 8 "Reserved" 9 "Reserved" 10 "Reserved" 11 "Reserved" 12 "Reserved" 13 "Reserved" 14 "Reserved" 15 "Don't care / Take no action" ;
VAL_ 2566568287 DCInletContactorCommand 0 "Open Contactor" 1 "Close Contactor" 2 "Reserved" 3 "Don't Care / Take no action" ;
VAL_ 2566568539 DCInletContactor1State 0 "Contactor Open" 1 "Contactor Closed" 2 "Error- Contactor fault detected" 3 "Not available" ;
VAL_ 2566567263 EVSESupportedEnergyTransferTypes 0 "DC-Extended" 1 "DC-Core" 13 "No EVSE connected" 14 "Error" 15 "Data not available" ;
VAL_ 2566568031 EVSEResponseCode 0 "OK" 1 "OK New Session Established" 2 "OK Old Session Joined" 3 "OK Certificate Expires Soon" 4 "FAILED" 5 "FAILED Sequence Error" 6 "FAILED Service ID Invalid" 7 "FAILED Unknown Session" 8 "FAILED Service Selection Invalid" 9 "FAILED Payment Selection Invalid" 10 "FAILED Certificate Expired" 11 "FAILED Signature Error" 12 "FAILED No Certificate Available" 13 "FAILED Cert Chain Error" 14 "FAILED Challenge Invalid" 15 "FAILED Contract Canceled" 16 "FAILED Wrong Charge Parameter" 17 "FAILED Power Delivery Not Applied" 18 "FAILED Tariff Selection Invalid" 19 "FAILED Charging Profile Invalid" 20 "FAILED EVSE Present Voltage Too Low" 21 "FAILED Metering Signature Not Valid" 22 "FAILED Wrong Energy Transfer Type" 255 "Not Available" ;
VAL_ 2566568031 EVSEProcessingState 0 "Finished" 1 "Ongoing" 2 "Reserved" 3 "Not available" ;
VAL_ 2566568031 EVSEIsolationStatus 0 "Valid" 1 "Warning" 2 "Fault" 3 "Reserved" 4 "Reserved" 5 "Reserved" 6 "Reserved" 7 "Reserved" 8 "Reserved" 9 "Reserved" 10 "Reserved" 11 "Reserved" 12 "Reserved" 13 "Reserved" 14 "Invalid" 15 "Not available" ;
VAL_ 2566568031 EVSEStatus 0 "EVSE Not Ready" 1 "EVSE Ready" 2 "EVSE Shutdown" 3 "Utility Interrupt Event" 4 "Isolation Monitoring Active" 5 "Emergency Shutdown" 6 "Malfunction" 7 "Reserved" 8 "Reserved" 9 "Reserved" 10 "Reserved" 11 "Reserved" 12 "Reserved" 13 "Reserved" 14 "No EVSE Connected" 15 "Not available" ;
VAL_ 2566568031 EVSEPowerLimitReached 0 "Not limited or no EVSE connected" 1 "Limit achieved" 2 "reserved" 3 "Not available" ;
VAL_ 2566568031 EVSECurrentLimitReached 0 "Not limited or no EVSE connected" 1 "Limit achieved" 2 "reserved" 3 "Not available" ;
VAL_ 2566568031 EVSEVoltageLimitReached 0 "Not limited or no EVSE connected" 1 "Limit achieved" 2 "reserved" 3 "Not available" ;
VAL_ 2566568031 ChargingState 0 "Idle" 1 "Charging" 2 "Standby" 3 "Reserved" 4 "Power Delivery, Start-up)" 5 "reserved" 6 "Power Delivery, Shutdown)" 7 "Welding Check" 8 "Charge Parameter Discovery" 9 "Cable Check" 10 "Initializing" 11 "Pre-charge" 12 "Terminating" 13 "Battery failure" 14 "EVSE fault" 15 "Not available" ;
VAL_ 2566575711 EVSEConnectorLockPermission 0 "Lock control prohibitted" 1 "Lock control allowed" 2 "reserved" 3 "Not available" ;
VAL_ 2566575711 EVSEConnectorLockState 0 "Unlocked" 1 "Locked" 2 "In transition to/from Locked" 3 "Reserved" 4 "Reserved" 5 "No locking mechanism is available on this vehicle" 6 "Error" 7 "Not available" ;
VAL_ 2566575711 EVSEManualOvrd 0 "Manual override not active" 1 "Manual override active" 2 "Error" 3 "Not available" ;
VAL_ 2566575711 EVSEConnectorReleaseLatch 0 "Latch released" 1 "Latch engaged" 2 "Unknown" 3 "Not available" ;
VAL_ 2558590815 ConnectedEnergySourceType 0 "AC Energy source" 1 "DC Energy source" 2 "SAE Reserved" 3 "Don't care / Take no action" ;
VAL_ 2566837855 OffBoardChargerConnectionState 0 "Off-board charger is not connected" 1 "Off-board charger is connected" 2 "Error" 3 "Not available" ;
VAL_ 2566899039 VehIsolationMoningDisCommand 0 "Not requested" 1 "Requested" 2 "Reserved" 3 "Not available" ;
VAL_ 2566899039 ProximityPinResistance 0 "100 Ohm" 1 "220 Ohm" 2 "680 Ohm" 3 "1500 Ohm" 4 "S3 150 Ohm" 5 "S3 480 Ohm" 6 "Error" 7 "Not available" ;
VAL_ 2566898779 StopChargingRequest 0 "Not active" 1 "Active" 2 "Error" 3 "Not available" ;
VAL_ 2566898779 EmergencyStopChargingRequest 0 "Inactive" 1 "Emergency Stop Active" 2 "Reserved" 3 "Not Available" ;
VAL_ 2566898779 IsolationMonitorStatusVehicle 0 "Not Active" 1 "Active" 2 "Error" 3 "Not available" ;
VAL_ 2566898779 PermitToSleep 0 "Not Active" 1 "Active" 2 "Error" 3 "Not available" ;
VAL_ 2566898779 LED1Command 0 "Off" 1 "On" 2 "Reserved" 3 "Not Available" ;
VAL_ 2566898779 LED2Command 0 "Off" 1 "On" 2 "Reserved" 3 "Not Available" ;
VAL_ 2566898779 LED3Command 0 "Off" 1 "On" 2 "Reserved" 3 "Not Available" ;
VAL_ 2365573150 OnboardChargerContactorState 0 "Contactor Open" 1 "Contactor Closed" 2 "Error" 3 "Not available" ;
VAL_ 2365573150 OnboardChargerPreChargeContactor 0 "Contactor Open" 1 "Contactor Closed" 2 "Error" 3 "Not available" ;
VAL_ 2365573150 OnboardChargerContactorErro_0000 0 "Other error" 1 "Failed to Open" 2 "Failed to Close" 3 "Take no action (leave function as is)" ;
VAL_ 2365573150 OnboardChargerPreChargeCont_0000 0 "Other error" 1 "Failed to Open" 2 "Failed to Close" 3 "Take no action (leave function as is)" ;
VAL_ 2365573150 HVJBTemperatureState 0 "Normal" 1 "High" 2 "Critical" 3 "Not available" ;
VAL_ 2566857511 VehicleHVEnableRequest 0 "Not active" 1 "Active" 2 "Reserved" 3 "Not available" ;
VAL_ 2566857511 ePTOHVActivationRequest 0 "Not active" 1 "Active" 2 "Reserved" 3 "Not available" ;
VAL_ 2566857511 CabACCompressorEnableRequest 0 "Not active" 1 "Active" 2 "Reserved" 3 "Not available" ;
VAL_ 2566857511 LowVoltageBatteryChargeRequest 0 "Not active" 1 "Active" 2 "Reserved" 3 "Not available" ;
VAL_ 2566857511 StopChargingSwitchStatus 0 "Not active" 1 "Active" 2 "Error" 3 "Not available" ;
VAL_ 2566857511 CabinDoorLockStatus 0 "Not active" 1 "Active" 2 "Error" 3 "Not available" ;
VAL_ 2566857511 CabinHeaterEnableCommand 0 "Disable" 1 "Enable" 2 "Reserved" 3 "Not available" ;
VAL_ 2566857511 BackofficeStopChargingDemand 0 "Not active" 1 "Active" 2 "Reserved" 3 "Not available" ;
VAL_ 2566857511 BackofficeChargingMethodSetting 0 "Unsecured" 1 "Secured" 2 "Reserved" 3 "Not available" ;
VAL_ 2566857511 BackofficeHighVoltageBattCalibra 0 "Not active" 1 "Active" 2 "Reserved" 3 "Not available" ;
VAL_ 2566857511 BackofficeChargingSOCSetting 0 "30%" 1 "35%" 2 "40%" 3 "45%" 4 "50%" 5 "55%" 6 "60%" 7 "65%" 8 "70%" 9 "75%" 10 "80%" 11 "85%" 12 "90%" 13 "95%" 14 "100%" 15 "Not available" ;
VAL_ 2565942823 EPTO_OperationalCommand 0 "Disable DC/AC Accessory Inverter Output" 1 "Enable DC/AC Accessory Inverter Output" 2 "Power down DC/AC Accessory Inverter Controller" 3 "Don't care/take no action" ;
VAL_ 2565942823 EPTO_Status2 0 "On" 1 "Off" 2 "Faulted On" 3 "Faulted Off" 4 "Reserved for SAE Assignment" 5 "Reserved for SAE Assignment" 6 "Error" 7 "Not Available" ;
VAL_ 2565942823 EPTO_Status1 0 "On" 1 "Off" 2 "Faulted On" 3 "Faulted Off" 4 "Reserved for SAE Assignment" 5 "Reserved for SAE Assignment" 6 "Error" 7 "Not Available" ;
VAL_ 2566865178 DCDC_LVVoltage 64256 "PARAMETER_SPECIFIC" 64511 "PARAMETER_SPECIFIC" 65024 "ERROR" 65279 "ERROR" 65280 "NOT_AVAILABLE" 65535 "NOT_AVAILABLE" ;
VAL_ 2566865178 DCDC_LVCurrent 64256 "PARAMETER_SPECIFIC" 64511 "PARAMETER_SPECIFIC" 65024 "ERROR" 65279 "ERROR" 65280 "NOT_AVAILABLE" 65535 "NOT_AVAILABLE" ;
VAL_ 2566865178 DCDC_HVVoltage 64256 "PARAMETER_SPECIFIC" 64511 "PARAMETER_SPECIFIC" 65024 "ERROR" 65279 "ERROR" 65280 "NOT_AVAILABLE" 65535 "NOT_AVAILABLE" ;
VAL_ 2566865178 DCDC_HVCurrent 64256 "PARAMETER_SPECIFIC" 64511 "PARAMETER_SPECIFIC" 65024 "ERROR" 65279 "ERROR" 65280 "NOT_AVAILABLE" 65535 "NOT_AVAILABLE" ;
VAL_ 2365573467 HVESSModeRequest 0 "Discharge mode" 1 "Charge mode" 2 "Reserved" 3 "Not available" ;
VAL_ 2365573467 HVESSStopPreconditioningRequest 0 "Not active" 1 "Active" 2 "Reserved" 3 "Not available" ;
